VERSION ""

NS_ :

BS_:

BU_: BSM BSM2 CADM CVADAS ECM EPS ORC CANOE EVCU2

BO_ 2654556161 ME_SystemDebugData_1: 64 CVADAS
 SG_ FD14_1_Hook_PresentPtr_MCU1_0 : 0|32@1+ (1,0) [0|0] ""  CANOE
 SG_ FD14_1_ErrFaultInfo_MCU2_0 : 32|16@1+ (1,0) [0|0] ""  CANOE
 SG_ FD14_1_Err_FaultInfo_MCU2_1 : 48|16@1+ (1,0) [0|0] ""  CANOE
 SG_ FD14_1_Err_FaultInfo_MPU1_0 : 64|16@1+ (1,0) [0|0] ""  CANOE
 SG_ FD14_1_Err_FaultInfo_MCU1_0 : 80|16@1+ (1,0) [0|0] ""  CANOE
 SG_ FD14_1_WDG_Error_ID_MCU1_0 : 96|16@1+ (1,0) [0|0] ""  CANOE
 SG_ FD14_1_SDL_Fault_MCU1_0 : 112|16@1+ (1,0) [0|0] ""  CANOE
 SG_ FD14_1_Hook_Service_MCU1_0 : 128|16@1+ (1,0) [0|0] ""  CANOE
 SG_ FD14_1_Hook_DtErr_MCU1_0 : 144|16@1+ (1,0) [0|0] ""  CANOE
 SG_ FD14_1_Hook_Reserved_MCU1_0 : 160|16@1+ (1,0) [0|0] ""  CANOE
 SG_ FD14_1_Hook_fatalErr_MCU1_0 : 176|8@1+ (1,0) [0|0] ""  CANOE
 SG_ FD14_1_Hook_actTsk_MCU1_0 : 184|8@1+ (1,0) [0|0] ""  CANOE
 SG_ FD14_1_Hook_Error_MCU1_0 : 192|8@1+ (1,0) [0|0] ""  CANOE
 SG_ FD14_1_Hook_Type_MCU1_0 : 200|8@1+ (1,0) [0|0] ""  CANOE
 SG_ FD14_1_SSM_FltData1_MCU1_0 : 208|8@1+ (1,0) [0|0] ""  CANOE
 SG_ FD14_1_SSM_FltData2_MCU1_0 : 216|8@1+ (1,0) [0|0] ""  CANOE
 SG_ FD14_1_SSM_FltData3_MCU1_0 : 224|8@1+ (1,0) [0|0] ""  CANOE
 SG_ FD14_1_SSM_FltData4_MCU1_0 : 232|8@1+ (1,0) [0|0] ""  CANOE
 SG_ FD14_1_SSM_FltData5_MCU1_0 : 240|8@1+ (1,0) [0|0] ""  CANOE
 SG_ FD14_1_SSM_FltData6_MCU1_0 : 248|8@1+ (1,0) [0|0] ""  CANOE
 SG_ FD14_1_SSM_FltData7_MCU1_0 : 256|8@1+ (1,0) [0|0] ""  CANOE
 SG_ FD14_1_SSM_FltData8_MCU1_0 : 264|8@1+ (1,0) [0|0] ""  CANOE
 SG_ FD14_1_SSM_FltData9_MCU1_0 : 272|8@1+ (1,0) [0|0] ""  CANOE
 SG_ FD14_1_SSM_FltData10_MCU1_0 : 280|8@1+ (1,0) [0|0] ""  CANOE
 SG_ FD14_1_SSM_FltData11_MCU1_0 : 288|8@1+ (1,0) [0|0] ""  CANOE
 SG_ FD14_1_SSM_FltData12_MCU1_0 : 296|8@1+ (1,0) [0|0] ""  CANOE
 SG_ FD14_1_SSM_FltData13_MCU1_0 : 304|8@1+ (1,0) [0|0] ""  CANOE
 SG_ FD14_1_SSM_FltData14_MCU1_0 : 312|8@1+ (1,0) [0|0] ""  CANOE
 SG_ FD14_1_SSM_FltData15_MCU1_0 : 320|8@1+ (1,0) [0|0] ""  CANOE
 SG_ FD14_1_SSM_FltData16_MCU1_0 : 328|8@1+ (1,0) [0|0] ""  CANOE
 SG_ FD14_1_SSM_FltData17_MCU1_0 : 336|8@1+ (1,0) [0|0] ""  CANOE
 SG_ FD14_1_SSM_FltData18_MCU1_0 : 344|8@1+ (1,0) [0|0] ""  CANOE
 SG_ FD14_1_Err_FaultNum_MCU2_0 : 352|8@1+ (1,0) [0|0] ""  CANOE
 SG_ FD14_1_Err_FaultNum_MCU2_1 : 360|8@1+ (1,0) [0|0] ""  CANOE
 SG_ FD14_1_Err_FaultNum_MPU1_0 : 368|8@1+ (1,0) [0|0] ""  CANOE
 SG_ FD14_1_Err_FaultNum_MCU1_0 : 376|8@1+ (1,0) [0|0] ""  CANOE
 SG_ FD14_1_Reserved_MCU2_0 : 384|8@1+ (1,0) [0|0] ""  CANOE
 SG_ FD14_1_Reserved_MCU2_1 : 392|8@1+ (1,0) [0|0] ""  CANOE
 SG_ FD14_1_Reserved_MPU1_0 : 400|8@1+ (1,0) [0|0] ""  CANOE
 SG_ FD14_1_Reserved_MCU1_0 : 408|8@1+ (1,0) [0|0] ""  CANOE

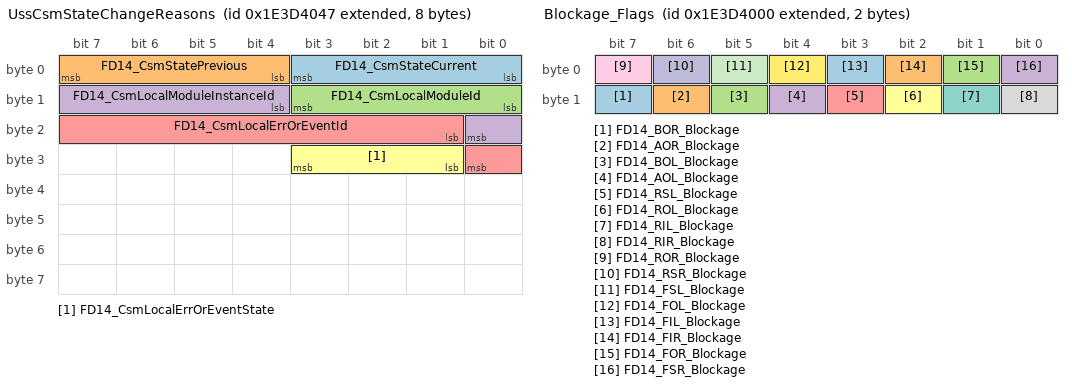
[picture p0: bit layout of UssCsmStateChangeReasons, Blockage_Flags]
BO_ 2654814279 UssCsmStateChangeReasons: 8 CVADAS
 SG_ FD14_CsmStateCurrent : 0|4@1+ (1,0) [0|15] ""  CANOE
 SG_ FD14_CsmStatePrevious : 4|4@1+ (1,0) [0|15] ""  CANOE
 SG_ FD14_CsmLocalModuleId : 8|4@1+ (1,0) [0|15] ""  CANOE
 SG_ FD14_CsmLocalModuleInstanceId : 12|5@1+ (1,0) [0|31] ""  CANOE
 SG_ FD14_CsmLocalErrOrEventId : 17|8@1+ (1,0) [0|255] ""  CANOE
 SG_ FD14_CsmLocalErrOrEventState : 25|3@1+ (1,0) [0|7] ""  CANOE

BO_ 2654552135 PntDebugData_Rx: 8 CANOE
 SG_ FD14_RawPntDebugSignal : 0|64@1+ (1,0) [0|0] ""  CVADAS

BO_ 2654552136 SetUSSParkingMode: 1 CANOE
 SG_ FD14_UssParkingModeSignal : 0|8@1+ (1,0) [0|0] ""  CVADAS

BO_ 2654814208 Blockage_Flags: 2 CVADAS
 SG_ FD14_BOR_Blockage : 15|1@1+ (1,0) [0|1] ""  CANOE
 SG_ FD14_AOR_Blockage : 14|1@1+ (1,0) [0|1] ""  CANOE
 SG_ FD14_BOL_Blockage : 13|1@1+ (1,0) [0|1] ""  CANOE
 SG_ FD14_AOL_Blockage : 12|1@1+ (1,0) [0|1] ""  CANOE
 SG_ FD14_RSL_Blockage : 11|1@1+ (1,0) [0|1] ""  CANOE
 SG_ FD14_ROL_Blockage : 10|1@1+ (1,0) [0|1] ""  CANOE
 SG_ FD14_RIL_Blockage : 9|1@1+ (1,0) [0|1] ""  CANOE
 SG_ FD14_RIR_Blockage : 8|1@1+ (1,0) [0|1] ""  CANOE
 SG_ FD14_ROR_Blockage : 7|1@1+ (1,0) [0|1] ""  CANOE
 SG_ FD14_RSR_Blockage : 6|1@1+ (1,0) [0|1] ""  CANOE
 SG_ FD14_FSL_Blockage : 5|1@1+ (1,0) [0|1] ""  CANOE
 SG_ FD14_FOL_Blockage : 4|1@1+ (1,0) [0|1] ""  CANOE
 SG_ FD14_FIL_Blockage : 3|1@1+ (1,0) [0|1] ""  CANOE
 SG_ FD14_FIR_Blockage : 2|1@1+ (1,0) [0|1] ""  CANOE
 SG_ FD14_FOR_Blockage : 1|1@1+ (1,0) [0|1] ""  CANOE
 SG_ FD14_FSR_Blockage : 0|1@1+ (1,0) [0|1] ""  CANOE

BO_ 2654552169 Debug_AP_Variables: 64 CVADAS
 SG_ FD14_IeAutoPark_e_AlgoState : 344|3@1+ (1,0) [0|4] ""  CANOE
 SG_ FD14_IeAP_e_AutoParkStatus : 331|3@1+ (1,0) [0|6] ""  CANOE
 SG_ FD14_MeAP_e_ParkAssistStatus : 336|3@1+ (1,0) [0|4] ""  CANOE
 SG_ FD14_MeAP_e_Park_state : 299|32@1- (1,0) [-32768|32768] ""  CANOE
 SG_ FD14_MeAP_a_ThrtlCmd : 267|32@1- (0.0001,0) [3.4E-038|3.4E+038] ""  CANOE
 SG_ FD14_MeAP_a_BrkCmd : 235|32@1- (0.0001,0) [3.4E-038|3.4E+038] ""  CANOE
 SG_ FD14_MeAP_deg_StrCmd : 203|32@1- (0.0001,0) [3.4E-038|3.4E+038] ""  CANOE
 SG_ FD14_MeAP_b_PPPADisable : 202|1@1+ (1,0) [0|1] ""  CANOE
 SG_ FD14_MeAP_b_PPPADefEng : 201|1@1+ (1,0) [0|1] ""  CANOE
 SG_ FD14_MeAP_b_PPPAActv4LOW : 200|1@1+ (1,0) [0|1] ""  CANOE
 SG_ FD14_MeAP_b_PPPAActvTrlr : 199|1@1+ (1,0) [0|1] ""  CANOE
 SG_ FD14_MeAP_b_PARBDisable : 198|1@1+ (1,0) [0|1] ""  CANOE
 SG_ FD14_MeAP_b_PARBActv4LOW : 197|1@1+ (1,0) [0|1] ""  CANOE
 SG_ FD14_MeAP_b_PARBActvTrlr : 196|1@1+ (1,0) [0|1] ""  CANOE
 SG_ FD14_MeAP_b_RPAVolDefMed : 195|1@1+ (1,0) [0|1] ""  CANOE
 SG_ FD14_MeAP_b_FPAVolDefMed : 194|1@1+ (1,0) [0|1] ""  CANOE
 SG_ FD14_MeAP_b_PAVolDefMed : 193|1@1+ (1,0) [0|1] ""  CANOE
 SG_ FD14_MeAP_b_RPAActvTrlr : 192|1@1+ (1,0) [0|1] ""  CANOE
 SG_ FD14_MeAP_b_RPADisable : 191|1@1+ (1,0) [0|1] ""  CANOE
 SG_ FD14_MeAP_b_FPADisable : 190|1@1+ (1,0) [0|1] ""  CANOE
 SG_ FD14_MeAP_b_FeatureEnbl : 189|1@1+ (1,0) [0|1] ""  CANOE
 SG_ FD14_MeAP_b_VehCndSts : 188|1@1+ (1,0) [0|1] ""  CANOE
 SG_ FD14_IeAP_b_MnvPosOk : 187|1@1+ (1,0) [0|1] ""  CANOE
 SG_ FD14_MeAP_b_SteerActionReq : 186|1@1+ (1,0) [0|1] ""  CANOE
 SG_ FD14_MeAP_b_PosMet : 185|1@1+ (1,0) [0|1] ""  CANOE
 SG_ FD14_MeAP_b_ManeuverSuccess : 184|1@1+ (1,0) [0|1] ""  CANOE
 SG_ FD14_MeAP_b_ManeuverAbort : 183|1@1+ (1,0) [0|1] ""  CANOE
 SG_ FD14_MeAP_b_BSMHandshakeActv : 182|1@1+ (1,0) [0|1] ""  CANOE
 SG_ FD14_MeAP_b_StandStill : 181|1@1+ (1,0) [0|1] ""  CANOE
 SG_ FD14_MeAP_b_DriverOverride : 180|1@1+ (1,0) [0|1] ""  CANOE
 SG_ FD14_MeAP_b_APInitSts : 179|1@1+ (1,0) [0|1] ""  CANOE
 SG_ FD14_MeAP_b_SeekSpdExceedTimeout : 178|1@1+ (1,0) [0|1] ""  CANOE
 SG_ FD14_MeAP_b_PausedPressBtnTimeou : 177|1@1+ (1,0) [0|1] ""  CANOE
 SG_ FD14_MeAP_b_ObjInPathTimeout : 176|1@1+ (1,0) [0|1] ""  CANOE
 SG_ FD14_MeAP_b_CamHandshakeTimeout : 175|1@1+ (1,0) [0|1] ""  CANOE
 SG_ FD14_MeAP_b_GearShiftWaitTimeout : 174|1@1+ (1,0) [0|1] ""  CANOE
 SG_ FD14_MeAP_b_EPSInterfaceTimeout : 173|1@1+ (1,0) [0|1] ""  CANOE
 SG_ FD14_MeAP_b_BSMInterfaceTimeout : 172|1@1+ (1,0) [0|1] ""  CANOE
 SG_ FD14_MeAP_b_VCOpPaused : 171|1@1+ (1,0) [0|1] ""  CANOE
 SG_ FD14_MeAP_b_RPAwithBrkStatus : 170|1@1+ (1,0) [0|1] ""  CANOE
 SG_ FD14_MeAP_b_RPAStatus : 169|1@1+ (1,0) [0|1] ""  CANOE
 SG_ FD14_MeAP_b_FPAStatus : 168|1@1+ (1,0) [0|1] ""  CANOE
 SG_ FD14_IeAP_e_AbortCon : 160|8@1+ (1,0) [0|255] ""  CANOE
 SG_ FD14_IeAP_cnt_CurrentVehSweep : 152|8@1+ (1,0) [0|255] ""  CANOE
 SG_ FD14_MeAP_e_PP_state : 144|8@1- (1,0) [-128|127] ""  CANOE
 SG_ FD14_MeAP_cm_RearRightMinXDist : 128|16@1- (1,0) [-32768|32768] ""  CANOE
 SG_ FD14_MeAP_cm_RearLeftMinXDist : 112|16@1- (1,0) [-32768|32768] ""  CANOE
 SG_ FD14_MeAP_cm_RearCenterMinXDist : 96|16@1- (1,0) [-32768|32768] ""  CANOE
 SG_ FD14_MeAP_cm_FrntRightMinXDist : 80|16@1- (1,0) [-32768|32768] ""  CANOE
 SG_ FD14_MeAP_cm_FrntLeftMinXDist : 64|16@1- (1,0) [-32768|32768] ""  CANOE
 SG_ FD14_MeAP_cm_FrntCenterMinXDist : 48|16@1- (1,0) [-32768|32768] ""  CANOE
 SG_ FD14_MeAP_cnt_TransDebugVar_Copy : 32|16@1- (1,0) [-32768|32768] ""  CANOE
 SG_ FD14_MeAP_cnt_TransDebugVar : 16|16@1+ (1,0) [0|512] ""  CANOE
 SG_ FD14_MeAP_cnt_StateDebugVar : 0|16@1+ (1,0) [0|512] ""  CANOE

BO_ 2654552217 Debug_CalibSts: 64 CVADAS
 SG_ FD14_CalibStatus_STM_Current_Rig : 120|8@1+ (1,0) [0|4] ""  CANOE
 SG_ FD14_CalibStatus_STM_Current_Rea : 112|8@1+ (1,0) [0|4] ""  CANOE
 SG_ FD14_CalibStatus_STM_Current_Lef : 104|8@1+ (1,0) [0|4] ""  CANOE
 SG_ FD14_CalibStatus_STM_Current_Fro : 96|8@1+ (1,0) [0|4] ""  CANOE
 SG_ FD14_CalibStatus_STM_OC_Right : 88|8@1+ (1,0) [0|4] ""  CANOE
 SG_ FD14_CalibStatus_STM_OC_Rear : 80|8@1+ (1,0) [0|4] ""  CANOE
 SG_ FD14_CalibStatus_STM_OC_Left : 72|8@1+ (1,0) [0|4] ""  CANOE
 SG_ FD14_CalibStatus_STM_OC_Front : 64|8@1+ (1,0) [0|4] ""  CANOE
 SG_ FD14_CalibStatus_STM_SC_Right : 56|8@1+ (1,0) [0|4] ""  CANOE
 SG_ FD14_CalibStatus_STM_SC_Rear : 48|8@1+ (1,0) [0|4] ""  CANOE
 SG_ FD14_CalibStatus_STM_SC_Left : 40|8@1+ (1,0) [0|4] ""  CANOE
 SG_ FD14_CalibStatus_STM_SC_Front : 32|8@1+ (1,0) [0|4] ""  CANOE
 SG_ FD14_CalibStatus_STM_EOL_Right : 24|8@1+ (1,0) [0|4] ""  CANOE
 SG_ FD14_CalibStatus_STM_EOL_Rear : 16|8@1+ (1,0) [0|4] ""  CANOE
 SG_ FD14_CalibStatus_STM_EOL_Left : 8|8@1+ (1,0) [0|4] ""  CANOE
 SG_ FD14_CalibStatus_STM_EOL_Front : 0|8@1+ (1,0) [0|4] ""  CANOE

BO_ 2654552163 Debug_CurrentCalib_Data_2: 64 CVADAS
 SG_ FD14_Z_f32_Current_Right : 352|32@1- (0.0001,0) [3.4E-038|3.4E+038] ""  CANOE
 SG_ FD14_Z_f32_Current_Rear : 320|32@1- (0.0001,0) [3.4E-038|3.4E+038] ""  CANOE
 SG_ FD14_Pitch_f32_Current_Right : 288|32@1- (0.0001,0) [3.4E-038|3.4E+038] ""  CANOE
 SG_ FD14_Pitch_f32_Current_Rear : 256|32@1- (0.0001,0) [3.4E-038|3.4E+038] ""  CANOE
 SG_ FD14_Roll_f32_Current_Right : 224|32@1- (0.0001,0) [3.4E-038|3.4E+038] ""  CANOE
 SG_ FD14_Roll_f32_Current_Rear : 192|32@1- (0.0001,0) [3.4E-038|3.4E+038] ""  CANOE
 SG_ FD14_Yaw_f32_Current_Right : 160|32@1- (0.0001,0) [3.4E-038|3.4E+038] ""  CANOE
 SG_ FD14_Yaw_f32_Current_Rear : 128|32@1- (0.0001,0) [3.4E-038|3.4E+038] ""  CANOE
 SG_ FD14_Y_f32_Current_Right : 96|32@1- (0.0001,0) [3.4E-038|3.4E+038] ""  CANOE
 SG_ FD14_Y_f32_Current_Rear : 64|32@1- (0.0001,0) [3.4E-038|3.4E+038] ""  CANOE
 SG_ FD14_X_f32_Current_Right : 32|32@1- (0.0001,0) [3.4E-038|3.4E+038] ""  CANOE
 SG_ FD14_X_f32_Current_Rear : 0|32@1- (0.0001,0) [3.4E-038|3.4E+038] ""  CANOE

BO_ 2654552152 Debug_EOLCalib_Data_1: 64 CVADAS
 SG_ FD14_Pitch_f32_EOL_Left : 352|32@1- (0.0001,0) [3.4E-038|3.4E+038] ""  CANOE
 SG_ FD14_Roll_f32_EOL_Left : 320|32@1- (0.0001,0) [3.4E-038|3.4E+038] ""  CANOE
 SG_ FD14_Yaw_f32_EOL_Left : 288|32@1- (0.0001,0) [3.4E-038|3.4E+038] ""  CANOE
 SG_ FD14_Z_f32_EOL_Left : 256|32@1- (0.0001,0) [3.4E-038|3.4E+038] ""  CANOE
 SG_ FD14_Y_f32_EOL_Left : 224|32@1- (0.0001,0) [3.4E-038|3.4E+038] ""  CANOE
 SG_ FD14_X_f32_EOL_Left : 192|32@1- (0.0001,0) [3.4E-038|3.4E+038] ""  CANOE
 SG_ FD14_Pitch_f32_EOL_Front : 160|32@1- (0.0001,0) [3.4E-038|3.4E+038] ""  CANOE
 SG_ FD14_Roll_f32_EOL_Front : 128|32@1- (0.0001,0) [3.4E-038|3.4E+038] ""  CANOE
 SG_ FD14_Yaw_f32_EOL_Front : 96|32@1- (0.0001,0) [3.4E-038|3.4E+038] ""  CANOE
 SG_ FD14_Z_f32_EOL_Front : 64|32@1- (0.0001,0) [3.4E-038|3.4E+038] ""  CANOE
 SG_ FD14_Y_f32_EOL_Front : 32|32@1- (0.0001,0) [3.4E-038|3.4E+038] ""  CANOE
 SG_ FD14_X_f32_EOL_Front : 0|32@1- (0.0001,0) [3.4E-038|3.4E+038] ""  CANOE

BO_ 2654552164 Debug_EOLCalib_Data_2: 64 CVADAS
 SG_ FD14_Roll_f32_EOL_Right : 352|32@1- (0.0001,0) [3.4E-038|3.4E+038] ""  CANOE
 SG_ FD14_Pitch_f32_EOL_Right : 320|32@1- (0.0001,0) [3.4E-038|3.4E+038] ""  CANOE
 SG_ FD14_Yaw_f32_EOL_Right : 288|32@1- (0.0001,0) [3.4E-038|3.4E+038] ""  CANOE
 SG_ FD14_Z_f32_EOL_Right : 256|32@1- (0.0001,0) [3.4E-038|3.4E+038] ""  CANOE
 SG_ FD14_Y_f32_EOL_Right : 224|32@1- (0.0001,0) [3.4E-038|3.4E+038] ""  CANOE
 SG_ FD14_X_f32_EOL_Right : 192|32@1- (0.0001,0) [3.4E-038|3.4E+038] ""  CANOE
 SG_ FD14_Pitch_f32_EOL_Rear : 160|32@1- (0.0001,0) [3.4E-038|3.4E+038] ""  CANOE
 SG_ FD14_Roll_f32_EOL_Rear : 128|32@1- (0.0001,0) [3.4E-038|3.4E+038] ""  CANOE
 SG_ FD14_Yaw_f32_EOL_Rear : 96|32@1- (0.0001,0) [3.4E-038|3.4E+038] ""  CANOE
 SG_ FD14_Z_f32_EOL_Rear : 64|32@1- (0.0001,0) [3.4E-038|3.4E+038] ""  CANOE
 SG_ FD14_Y_f32_EOL_Rear : 32|32@1- (0.0001,0) [3.4E-038|3.4E+038] ""  CANOE
 SG_ FD14_X_f32_EOL_Rear : 0|32@1- (0.0001,0) [3.4E-038|3.4E+038] ""  CANOE

BO_ 2654552216 Debug_ErrCodeAlgo: 64 CVADAS
 SG_ FD14_Err_Code_OC_Right : 88|8@1+ (1,0) [0|7] ""  CANOE
 SG_ FD14_Err_Code_OC_Rear : 80|8@1+ (1,0) [0|7] ""  CANOE
 SG_ FD14_Err_Code_OC_Left : 72|8@1+ (1,0) [0|7] ""  CANOE
 SG_ FD14_Err_Code_OC_Front : 64|8@1+ (1,0) [0|7] ""  CANOE
 SG_ FD14_Err_Code_SC_Right : 56|8@1+ (1,0) [0|7] ""  CANOE
 SG_ FD14_Err_Code_SC_Rear : 48|8@1+ (1,0) [0|7] ""  CANOE
 SG_ FD14_Err_Code_SC_Left : 40|8@1+ (1,0) [0|7] ""  CANOE
 SG_ FD14_Err_Code_SC_Front : 32|8@1+ (1,0) [0|7] ""  CANOE
 SG_ FD14_Err_Code_EOL_Rear_Copy_1 : 24|8@1+ (1,0) [0|19] ""  CANOE
 SG_ FD14_Err_Code_EOL_Rear : 16|8@1+ (1,0) [0|19] ""  CANOE
 SG_ FD14_Err_Code_EOL_Left : 8|8@1+ (1,0) [0|19] ""  CANOE
 SG_ FD14_Err_Code_EOL_Front : 0|8@1+ (1,0) [0|19] ""  CANOE

BO_ 2654552162 Debug_FeatureCollection: 64 CVADAS
 SG_ FD14_InvalidFeatures_Right_u32 : 352|32@1+ (1,0) [0|4294967295] ""  CANOE
 SG_ FD14_IgnoredFeatures_Right_u32 : 320|32@1+ (1,0) [0|4294967295] ""  CANOE
 SG_ FD14_ValidFeatures_Right_u32 : 288|32@1+ (1,0) [0|4294967295] ""  CANOE
 SG_ FD14_InvalidFeatures_Rear_u32 : 256|32@1+ (1,0) [0|4294967295] ""  CANOE
 SG_ FD14_IgnoredFeatures_Rear_u32 : 224|32@1+ (1,0) [0|4294967295] ""  CANOE
 SG_ FD14_ValidFeatures_Rear_u32 : 192|32@1+ (1,0) [0|4294967295] ""  CANOE
 SG_ FD14_InvalidFeatures_Left_u32 : 160|32@1+ (1,0) [0|4294967295] ""  CANOE
 SG_ FD14_IgnoredFeatures_Left_u32 : 128|32@1+ (1,0) [0|4294967295] ""  CANOE
 SG_ FD14_ValidFeatures_Left_u32 : 96|32@1+ (1,0) [0|4294967295] ""  CANOE
 SG_ FD14_InvalidFeatures_Front_u32 : 64|32@1+ (1,0) [0|4294967295] ""  CANOE
 SG_ FD14_IgnoredFeatures_Front_u32 : 32|32@1+ (1,0) [0|4294967295] ""  CANOE
 SG_ FD14_ValidFeatures_Front_u32 : 0|32@1+ (1,0) [0|4294967295] ""  CANOE

BO_ 2654552178 Debug_FPA_HMI_InfoToVC: 64 CVADAS
 SG_ FD14_perpParkDirectionSel : 296|2@1+ (1,0) [0|2] ""  CANOE
 SG_ FD14_parkExtSideSel : 288|2@1+ (1,0) [0|2] ""  CANOE
 SG_ FD14_slotSide : 280|2@1+ (1,0) [0|2] ""  CANOE
 SG_ FD14_parkingDirection : 272|2@1+ (1,0) [0|2] ""  CANOE
 SG_ FD14_parkingSlotType : 264|3@1+ (1,0) [0|7] ""  CANOE
 SG_ FD14_IsBackSftbtnSel : 259|1@1+ (1,0) [0|1] ""  CANOE
 SG_ FD14_IsSlotSel : 258|1@1+ (1,0) [0|1] ""  CANOE
 SG_ FD14_IsExitSftBtnSel : 257|1@1+ (1,0) [0|1] ""  CANOE
 SG_ FD14_IsParkSftBtnSel : 256|1@1+ (1,0) [0|1] ""  CANOE
 SG_ FD14_MaAP_m_ParkSpot4RearStreetY : 224|32@1- (0.0001,0) [-15|15] ""  CANOE
 SG_ FD14_MaAP_m_ParkSpot4RearStreetX : 192|32@1- (0.0001,0) [-15|15] ""  CANOE
 SG_ FD14_MaAP_m_ParkSpot3RearBorderY : 160|32@1- (0.0001,0) [-15|15] ""  CANOE
 SG_ FD14_MaAP_m_ParkSpot3RearBorderX : 128|32@1- (0.0001,0) [-15|15] ""  CANOE
 SG_ FD14_MaAP_m_ParkSpot2FrntBorderY : 96|32@1- (0.0001,0) [-15|15] ""  CANOE
 SG_ FD14_MaAP_m_ParkSpot2FrntBorderX : 64|32@1- (0.0001,0) [-15|15] ""  CANOE
 SG_ FD14_MaAP_m_ParkSpot1FrntStreetY : 32|32@1- (0.0001,0) [-15|15] ""  CANOE
 SG_ FD14_MaAP_m_ParkSpot1FrntStreetX : 0|32@1- (0.0001,0) [-15|15] ""  CANOE

BO_ 2654552149 Debug_HMI_Input_Data: 64 CVADAS
 SG_ FD14_tchScrnStatus_e : 216|8@1+ (1,0) [0|7] ""  CANOE
 SG_ FD14_View_Error_e : 208|8@1+ (1,0) [0|0] ""  CANOE
 SG_ FD14_DynOvl_Error_e : 200|8@1+ (1,0) [0|0] ""  CANOE
 SG_ FD14_SoftBtn_Error_e : 192|8@1+ (1,0) [0|0] ""  CANOE
 SG_ FD14_ImageDefeat_Error_e : 184|8@1+ (1,0) [0|0] ""  CANOE
 SG_ FD14_tgwDispStatus_e : 176|8@1+ (1,0) [0|0] ""  CANOE
 SG_ FD14_CameraDisplaySts2_e : 168|8@1+ (1,0) [0|0] ""  CANOE
 SG_ FD14_prndStatus_e : 160|8@1+ (1,0) [0|0] ""  CANOE
 SG_ FD14_transEquipped_e : 152|8@1+ (1,0) [0|0] ""  CANOE
 SG_ FD14_ignitionStatus_e : 144|8@1+ (1,0) [0|0] ""  CANOE
 SG_ FD14_trscStat_e : 136|8@1+ (1,0) [0|0] ""  CANOE
 SG_ FD14_NetCfg_TRSCM_e : 128|8@1+ (1,0) [0|0] ""  CANOE
 SG_ FD14_revGear_e : 120|8@1+ (1,0) [0|0] ""  CANOE
 SG_ FD14_lrwsST_e : 112|8@1+ (1,0) [0|0] ""  CANOE
 SG_ FD14_GW_C_I6_timeout_b : 109|1@1+ (1,0) [0|1] ""  CANOE
 SG_ FD14_SVC_Delay_Feature_b : 108|1@1+ (1,0) [0|1] ""  CANOE
 SG_ FD14_SVC_FFCV_Gridlines_Feature_ : 107|1@1+ (1,0) [0|1] ""  CANOE
 SG_ FD14_SVC_Static_Gridlines_Featur : 106|1@1+ (1,0) [0|1] ""  CANOE
 SG_ FD14_SVC_Dynamic_Gridlines_Featu : 105|1@1+ (1,0) [0|1] ""  CANOE
 SG_ FD14_TopVideoBlanked_b : 104|1@1+ (1,0) [0|1] ""  CANOE
 SG_ FD14_LanguageSelection_u8 : 96|8@1+ (1,0) [0|255] ""  CANOE
 SG_ FD14_vehicleLine_e : 88|8@1+ (1,0) [0|255] ""  CANOE
 SG_ FD14_tchScrnCoord_s_Y_u16 : 80|8@1+ (1,0) [0|255] ""  CANOE
 SG_ FD14_tchScrnCoord_s_X_u16 : 72|8@1+ (1,0) [0|255] ""  CANOE
 SG_ FD14_CAM_NA_Bitfield_u8 : 64|8@1+ (1,0) [0|255] ""  CANOE
 SG_ FD14_vehicleSpeed_f32 : 32|32@1- (1,0) [3.4E-038|3.4E+038] ""  CANOE
 SG_ FD14_steeringWheelAngle_f32 : 0|32@1- (1,0) [3.4E-038|3.4E+038] ""  CANOE

BO_ 2654552150 Debug_HMI_Internal_Data: 16 CVADAS
 SG_ FD14_LastViewBeforeTestPattern_e : 88|8@1+ (1,0) [0|25] ""  CANOE
 SG_ FD14_Prev_DisplayedViewByAcore_e : 80|8@1+ (1,0) [0|25] ""  CANOE
 SG_ FD14_Curr_DisplayedViewByAcore_e : 72|8@1+ (1,0) [0|25] ""  CANOE
 SG_ FD14_Prev_RequestedViewByHmiM_e : 64|8@1+ (1,0) [0|25] ""  CANOE
 SG_ FD14_Curr_RequestedViewByHmiM_e : 56|8@1+ (1,0) [0|25] ""  CANOE
 SG_ FD14_Prev_SystemState_e : 48|8@1+ (1,0) [0|2] ""  CANOE
 SG_ FD14_Curr_SystemState_e : 40|8@1+ (1,0) [0|2] ""  CANOE
 SG_ FD14_M_FFClatch_e : 32|8@1+ (1,0) [0|1] ""  CANOE
 SG_ FD14_M_BURV_Memory_e : 24|8@1+ (1,0) [0|1] ""  CANOE
 SG_ FD14_FRONT_TOP_BTN_PRESSED_b : 20|1@1+ (1,0) [0|1] ""  CANOE
 SG_ FD14_REAR_TOP_BTN_PRESSED_b : 19|1@1+ (1,0) [0|1] ""  CANOE
 SG_ FD14_MAGNIFIER_BTN_PRESSED_b : 18|1@1+ (1,0) [0|1] ""  CANOE
 SG_ FD14_X_BTN_PRESSED_b : 17|1@1+ (1,0) [0|1] ""  CANOE
 SG_ FD14_OFFROAD_ABSNT_MC_BTN_PRESSE : 16|1@1+ (1,0) [0|1] ""  CANOE
 SG_ FD14_OFFROAD_PRSNT_MC_BTN_PRESSE : 15|1@1+ (1,0) [0|1] ""  CANOE
 SG_ FD14_OFFRD_ABSNT_AUXCAM_BTN_PRES : 14|1@1+ (1,0) [0|1] ""  CANOE
 SG_ FD14_OFFRD_PRSNT_AUXCAM_BTN_PRES : 13|1@1+ (1,0) [0|1] ""  CANOE
 SG_ FD14_RVCONLY_BTN_PRESSED_b : 12|1@1+ (1,0) [0|1] ""  CANOE
 SG_ FD14_FFCV_BTN_PRESSED_b : 11|1@1+ (1,0) [0|1] ""  CANOE
 SG_ FD14_FRONT_CROSS_BTN_PRESSED_b : 10|1@1+ (1,0) [0|1] ""  CANOE
 SG_ FD14_REAR_CROSS_BTN_PRESSED_b : 9|1@1+ (1,0) [0|1] ""  CANOE
 SG_ FD14_IgnoreVehicleOffSpeed : 8|1@1+ (1,0) [0|1] ""  CANOE
 SG_ FD14_ZoomFactor_u8 : 0|8@1+ (1,0) [0|255] ""  CANOE

BO_ 2654552148 Debug_HMI_Trailer_Views_Data: 64 CVADAS
 SG_ FD14_TrailerCalibrationStatus : 264|8@1+ (1,0) [0|2] ""  CANOE
 SG_ FD14_TrscStatus : 256|8@1+ (1,0) [0|7] ""  CANOE
 SG_ FD14__JackKnifeAngle : 224|32@1- (1,0) [3.4E-038|3.4E+038] ""  CANOE
 SG_ FD14_TrailerAngleSign : 136|8@1+ (1,0) [0|1] ""  CANOE
 SG_ FD14_Prev_TRG_Stat : 128|8@1+ (1,0) [0|3] ""  CANOE
 SG_ FD14_Curr_TRG_Stat : 120|8@1+ (1,0) [0|3] ""  CANOE
 SG_ FD14_ItbmTrailerStatus : 216|8@1+ (1,0) [0|255] ""  CANOE
 SG_ FD14_TrailerConnectionStatus : 80|8@1+ (1,0) [0|255] ""  CANOE
 SG_ FD14_TrailerWheelBase : 208|8@1+ (1,0) [0|255] ""  CANOE
 SG_ FD14_KnobAngle : 176|32@1- (1,0) [3.4E-038|3.4E+038] ""  CANOE
 SG_ FD14_MaxTadAngle : 144|32@1- (1,0) [3.4E-038|3.4E+038] ""  CANOE
 SG_ FD14_TadAngle : 88|32@1- (1,0) [3.4E-038|3.4E+038] ""  CANOE
 SG_ FD14_STM_v_TRGAUTO_BTN_PRESSED_b : 31|1@1+ (1,0) [0|1] ""  CANOE
 SG_ FD14_STM_v_TRGRIGHT_BTN_PRESSED_ : 30|1@1+ (1,0) [0|1] ""  CANOE
 SG_ FD14_STM_v_TRGLEFT_BTN_PRESSED_b : 29|1@1+ (1,0) [0|1] ""  CANOE
 SG_ FD14_M_Progress_Bar_Percentage : 72|8@1+ (1,0) [0|255] ""  CANOE
 SG_ FD14_M_Maneuver_Initial_Run : 64|8@1+ (1,0) [0|255] ""  CANOE
 SG_ FD14_M_Progress_Bar_Distance : 56|8@1+ (1,0) [0|255] ""  CANOE
 SG_ FD14_M_Cplr_Htch_Distance : 48|8@1+ (1,0) [0|255] ""  CANOE
 SG_ FD14_M_CPLR_POS_Y_u : 40|8@1+ (1,0) [0|255] ""  CANOE
 SG_ FD14_M_CPLR_POS_X_u : 32|8@1+ (1,0) [0|255] ""  CANOE
 SG_ FD14_M_THA_SFT_BTN_PRESSED_b : 28|1@1+ (1,0) [0|1] ""  CANOE
 SG_ FD14_M_START_BTN_PRESSED_b : 24|1@1+ (1,0) [0|1] ""  CANOE
 SG_ FD14_M_CONFIRM_BTN_PRESSED_b : 25|1@1+ (1,0) [0|1] ""  CANOE
 SG_ FD14_M_VIEW_SCRN_TCH_STS_b : 26|1@1+ (1,0) [0|1] ""  CANOE
 SG_ FD14_M_VIEW_ZOOM_STS_b : 27|1@1+ (1,0) [0|1] ""  CANOE
 SG_ FD14_M_Current_THA_State_On_Scre : 16|8@1+ (1,0) [0|255] ""  CANOE
 SG_ FD14_M_Current_THA_State_On_Zync : 8|8@1+ (1,0) [0|255] ""  CANOE
 SG_ FD14_M_Requested_THA_State : 0|8@1+ (1,0) [0|255] ""  CANOE

BO_ 2654552320 Debug_ModuleState: 64 CVADAS
 SG_ FD14_OC_ModuleState_STM_Right : 88|8@1+ (1,0) [0|11] ""  CANOE
 SG_ FD14_OC_ModuleState_STM_Rear : 80|8@1+ (1,0) [0|11] ""  CANOE
 SG_ FD14_OC_ModuleState_STM_Left : 72|8@1+ (1,0) [0|11] ""  CANOE
 SG_ FD14_OC_ModuleState_STM_Front : 64|8@1+ (1,0) [0|11] ""  CANOE
 SG_ FD14_SC_ModuleState_STM_Right : 56|8@1+ (1,0) [0|12] ""  CANOE
 SG_ FD14_SC_ModuleState_STM_Rear : 48|8@1+ (1,0) [0|12] ""  CANOE
 SG_ FD14_SC_ModuleState_STM_Left : 40|8@1+ (1,0) [0|12] ""  CANOE
 SG_ FD14_SC_ModuleState_STM_Front : 32|8@1+ (1,0) [0|12] ""  CANOE
 SG_ FD14_EOL_ModuleState_STM_Right : 24|8@1+ (1,0) [0|8] ""  CANOE
 SG_ FD14_EOL_ModuleState_STM_Rear : 16|8@1+ (1,0) [0|8] ""  CANOE
 SG_ FD14_EOL_ModuleState_STM_Left : 8|8@1+ (1,0) [0|8] ""  CANOE
 SG_ FD14_EOL_ModuleState_STM_Front : 0|8@1+ (1,0) [0|8] ""  CANOE

BO_ 2654552176 Debug_NFCD_Obj_0_4: 64 CVADAS
 SG_ FD14_NFCD_DistanceToClosestPoint : 296|32@1- (0.0001,0) [-15|15] ""  CANOE
 SG_ FD14_NFCD_DistanceToClosest_0000 : 264|32@1- (0.0001,0) [-15|15] ""  CANOE
 SG_ FD14_NFCD_ObjValid_4 : 68|1@1+ (1,0) [0|1] ""  CANOE
 SG_ FD14_NFCD_ObjValid_3 : 67|1@1+ (1,0) [0|1] ""  CANOE
 SG_ FD14_NFCD_DistanceToClosest_0001 : 232|32@1- (0.0001,0) [-15|15] ""  CANOE
 SG_ FD14_NFCD_DistanceToClosest_0002 : 200|32@1- (0.0001,0) [-15|15] ""  CANOE
 SG_ FD14_NFCD_ObjValid_2 : 66|1@1+ (1,0) [0|1] ""  CANOE
 SG_ FD14_NFCD_DistanceToClosest_0003 : 168|32@1- (0.0001,0) [-15|15] ""  CANOE
 SG_ FD14_NFCD_DistanceToClosest_0004 : 136|32@1- (0.0001,0) [-15|15] ""  CANOE
 SG_ FD14_NFCD_ObjValid_1 : 65|1@1+ (1,0) [0|1] ""  CANOE
 SG_ FD14_NFCD_DistanceToClosest_0005 : 104|32@1- (0.0001,0) [-15|15] ""  CANOE
 SG_ FD14_NFCD_DistanceToClosest_0006 : 72|32@1- (0.0001,0) [-15|15] ""  CANOE
 SG_ FD14_NFCD_ObjValid_0 : 64|1@1+ (1,0) [0|1] ""  CANOE
 SG_ FD14_NFCD_DistanceToClosest_0007 : 32|32@1- (0.0001,0) [-15|15] ""  CANOE
 SG_ FD14_NFCD_DistanceToClosest_0008 : 0|32@1- (0.0001,0) [-15|15] ""  CANOE

BO_ 2654552177 Debug_NFCD_Obj_5_9: 64 CVADAS
 SG_ FD14_IeVBII_nfcd_MinDisToCollisi : 336|32@1- (0.0001,0) [-15|15] ""  CANOE
 SG_ FD14_NFCD_ObjValid_9 : 68|1@1+ (1,0) [0|1] ""  CANOE
 SG_ FD14_NFCD_DistanceToClosest_0009 : 304|32@1- (0.0001,0) [-15|15] ""  CANOE
 SG_ FD14_NFCD_DistanceToClosest_0010 : 272|32@1- (0.0001,0) [-15|15] ""  CANOE
 SG_ FD14_NFCD_ObjValid_8 : 67|1@1+ (1,0) [0|1] ""  CANOE
 SG_ FD14_NFCD_DistanceToClosest_0011 : 240|32@1- (0.0001,0) [-15|15] ""  CANOE
 SG_ FD14_NFCD_DistanceToClosest_0012 : 208|32@1- (0.0001,0) [-15|15] ""  CANOE
 SG_ FD14_NFCD_ObjValid_7 : 66|1@1+ (1,0) [0|1] ""  CANOE
 SG_ FD14_NFCD_DistanceToClosest_0013 : 176|32@1- (0.0001,0) [-15|15] ""  CANOE
 SG_ FD14_NFCD_DistanceToClosest_0014 : 144|32@1- (0.0001,0) [-15|15] ""  CANOE
 SG_ FD14_NFCD_ObjValid_6 : 65|1@1+ (1,0) [0|1] ""  CANOE
 SG_ FD14_NFCD_DistanceToClosest_0015 : 112|32@1- (0.0001,0) [-15|15] ""  CANOE
 SG_ FD14_NFCD_DistanceToClosest_0016 : 80|32@1- (0.0001,0) [-15|15] ""  CANOE
 SG_ FD14_NFCD_ObjValid_5 : 64|1@1+ (1,0) [0|1] ""  CANOE
 SG_ FD14_NFCD_DistanceToClosest_0017 : 32|32@1- (0.0001,0) [-15|15] ""  CANOE
 SG_ FD14_NFCD_DistanceToClosest_0018 : 0|32@1- (0.0001,0) [-15|15] ""  CANOE

BO_ 2654552160 Debug_OCCalib_Data: 64 CVADAS
 SG_ FD14_Z_f32_Current_Rear : 448|32@1- (0.0001,0) [3.4E-038|3.4E+038] ""  CANOE
 SG_ FD14_Y_f32_Current_Rear : 416|32@1- (0.0001,0) [3.4E-038|3.4E+038] ""  CANOE
 SG_ FD14_X_f32_Current_Rear : 384|32@1- (0.0001,0) [3.4E-038|3.4E+038] ""  CANOE
 SG_ FD14_Pitch_f32_OC_Right : 352|32@1- (0.0001,0) [3.4E-038|3.4E+038] ""  CANOE
 SG_ FD14_Roll_f32_OC_Right : 320|32@1- (0.0001,0) [3.4E-038|3.4E+038] ""  CANOE
 SG_ FD14_Yaw_f32_OC_Right : 288|32@1- (0.0001,0) [3.4E-038|3.4E+038] ""  CANOE
 SG_ FD14_Pitch_f32_OC_Rear : 256|32@1- (0.0001,0) [3.4E-038|3.4E+038] ""  CANOE
 SG_ FD14_Roll_f32_OC_Rear : 224|32@1- (0.0001,0) [3.4E-038|3.4E+038] ""  CANOE
 SG_ FD14_Yaw_f32_OC_Rear : 192|32@1- (0.0001,0) [3.4E-038|3.4E+038] ""  CANOE
 SG_ FD14_Pitch_f32_OC_Left : 160|32@1- (0.0001,0) [3.4E-038|3.4E+038] ""  CANOE
 SG_ FD14_Roll_f32_OC_Left : 128|32@1- (0.0001,0) [3.4E-038|3.4E+038] ""  CANOE
 SG_ FD14_Yaw_f32_OC_Left : 96|32@1- (0.0001,0) [3.4E-038|3.4E+038] ""  CANOE
 SG_ FD14_Pitch_f32_OC_Front : 64|32@1- (0.0001,0) [3.4E-038|3.4E+038] ""  CANOE
 SG_ FD14_Roll_f32_OC_Front : 32|32@1- (0.0001,0) [3.4E-038|3.4E+038] ""  CANOE
 SG_ FD14_Yaw_f32_OC_Front : 0|32@1- (0.0001,0) [3.4E-038|3.4E+038] ""  CANOE

BO_ 2654552153 Debug_SCCalib_Data: 64 CVADAS
 SG_ FD14_Pitch_f32_SC_Right : 352|32@1- (0.0001,0) [3.4E-038|3.4E+038] ""  CANOE
 SG_ FD14_Roll_f32_SC_Right : 320|32@1- (0.0001,0) [3.4E-038|3.4E+038] ""  CANOE
 SG_ FD14_Yaw_f32_SC_Right : 288|32@1- (0.0001,0) [3.4E-038|3.4E+038] ""  CANOE
 SG_ FD14_Pitch_f32_SC_Rear : 256|32@1- (0.0001,0) [3.4E-038|3.4E+038] ""  CANOE
 SG_ FD14_Roll_f32_SC_Rear : 224|32@1- (0.0001,0) [3.4E-038|3.4E+038] ""  CANOE
 SG_ FD14_Yaw_f32_SC_Rear : 192|32@1- (0.0001,0) [3.4E-038|3.4E+038] ""  CANOE
 SG_ FD14_Pitch_f32_SC_Left : 160|32@1- (0.0001,0) [3.4E-038|3.4E+038] ""  CANOE
 SG_ FD14_Roll_f32_SC_Left : 128|32@1- (0.0001,0) [3.4E-038|3.4E+038] ""  CANOE
 SG_ FD14_Yaw_f32_SC_Left : 96|32@1- (0.0001,0) [3.4E-038|3.4E+038] ""  CANOE
 SG_ FD14_Pitch_f32_SC_Front : 64|32@1- (0.0001,0) [3.4E-038|3.4E+038] ""  CANOE
 SG_ FD14_Roll_f32_SC_Front : 32|32@1- (0.0001,0) [3.4E-038|3.4E+038] ""  CANOE
 SG_ FD14_Yaw_f32_SC_Front : 0|32@1- (0.0001,0) [3.4E-038|3.4E+038] ""  CANOE

BO_ 2654552161 Debug_TargetData: 64 CVADAS
 SG_ FD14_TargetDetectRightRear_Right : 208|8@1- (1,0) [-128|127] ""  CANOE
 SG_ FD14_TargetDetectRightFront_Righ : 200|8@1- (1,0) [-128|127] ""  CANOE
 SG_ FD14_TargetDetectLeftRear_Right_ : 192|8@1- (1,0) [-128|127] ""  CANOE
 SG_ FD14_TargetDetectLeftFront_Right : 184|8@1- (1,0) [-128|127] ""  CANOE
 SG_ FD14_TargetLimitRear_Right_s8 : 176|8@1- (1,0) [-128|127] ""  CANOE
 SG_ FD14_TargetLimitFront_Right_s8 : 168|8@1- (1,0) [-128|127] ""  CANOE
 SG_ FD14_TargetInit_Right_s8 : 160|8@1- (1,0) [-128|127] ""  CANOE
 SG_ FD14_TargetDetectRightRear_Rear_ : 152|8@1- (1,0) [-128|127] ""  CANOE
 SG_ FD14_TargetDetectRightFront_Rear : 144|8@1- (1,0) [-128|127] ""  CANOE
 SG_ FD14_TargetDetectLeftRear_Rear_s : 136|8@1- (1,0) [-128|127] ""  CANOE
 SG_ FD14_TargetDetectLeftFront_Rear_ : 128|8@1- (1,0) [-128|127] ""  CANOE
 SG_ FD14_TargetLimitRear_Rear_s8 : 120|8@1- (1,0) [-128|127] ""  CANOE
 SG_ FD14_TargetLimitFront_Rear_s8 : 112|8@1- (1,0) [-128|127] ""  CANOE
 SG_ FD14_TargetInit_Rear_s8 : 104|8@1- (1,0) [-128|127] ""  CANOE
 SG_ FD14_TargetDetectRightRear_Left_ : 96|8@1- (1,0) [-128|127] ""  CANOE
 SG_ FD14_TargetDetectRightFront_Left : 88|8@1- (1,0) [-128|127] ""  CANOE
 SG_ FD14_TargetDetectLeftFront_Left_ : 80|8@1- (1,0) [-128|127] ""  CANOE
 SG_ FD14_TargetLimitRear_Left_s8 : 72|8@1- (1,0) [-128|127] ""  CANOE
 SG_ FD14_TargetLimitFront_Left_s8 : 64|8@1- (1,0) [-128|127] ""  CANOE
 SG_ FD14_TargetInit_Left_s8 : 56|8@1- (1,0) [-128|127] ""  CANOE
 SG_ FD14_TargetDetectRightRear_Front : 48|8@1- (1,0) [-128|127] ""  CANOE
 SG_ FD14_TargetDetectRightFront_Fron : 40|8@1- (1,0) [-128|127] ""  CANOE
 SG_ FD14_TargetDetectLeftRear_Front_ : 32|8@1- (1,0) [-128|127] ""  CANOE
 SG_ FD14_TargetDetectLeftFront_Front : 24|8@1- (1,0) [-128|127] ""  CANOE
 SG_ FD14_TargetLimitRear_Front_s8 : 16|8@1- (1,0) [-128|127] ""  CANOE
 SG_ FD14_TargetLimitFront_Front_s8 : 8|8@1- (1,0) [-128|127] ""  CANOE
 SG_ FD14_TargetInit_Front_s8 : 0|8@1- (1,0) [-128|127] ""  CANOE

BO_ 2654552194 DebugModelOutput: 64 CVADAS
 SG_ FD14_IeAP_cm_RearRightMinXDist_K : 176|12@1+ (1,0) [0|2000] "cm"  CANOE
 SG_ FD14_IeAP_cm_RearRightMinXDist : 160|12@1+ (1,0) [0|2000] "cm"  CANOE
 SG_ FD14_IeAP_cm_RearLeftMinXDist_KP : 144|12@1+ (1,0) [0|2000] "cm"  CANOE
 SG_ FD14_IeAP_cm_RearLeftMinXDist : 128|12@1+ (1,0) [0|2000] "cm"  CANOE
 SG_ FD14_IeAP_cm_RearCenterMinXDist_ : 112|12@1+ (1,0) [0|2000] "cm"  CANOE
 SG_ FD14_IeAP_cm_RearCenterMinXDist : 96|12@1+ (1,0) [0|2000] "cm"  CANOE
 SG_ FD14_IeAP_cm_FrntRightMinXDist_K : 80|12@1+ (1,0) [0|2000] "cm"  CANOE
 SG_ FD14_IeAP_cm_FrntRightMinXDist : 64|12@1+ (1,0) [0|2000] "cm"  CANOE
 SG_ FD14_IeAP_cm_FrntLeftMinXDist_KP : 48|12@1+ (1,0) [0|2000] "cm"  CANOE
 SG_ FD14_IeAP_cm_FrntLeftMinXDist : 32|12@1+ (1,0) [0|2000] "cm"  CANOE
 SG_ FD14_IeAP_cm_FrntCenterMinXDist_ : 16|12@1+ (1,0) [0|2000] "cm"  CANOE
 SG_ FD14_IeAP_cm_FrntCenterMinXDist : 0|12@1+ (1,0) [0|2000] "cm"  CANOE

BO_ 2654814232 DebugModelOutput_Feature_KPI_Tx: 64 CVADAS
 SG_ FD14_IeAP_cm_RearRightMinXD_0000 : 60|12@1+ (1,0) [0|2000] "cm"  CANOE
 SG_ FD14_IeAP_cm_RearLeftMinXDi_0000 : 48|12@1+ (1,0) [0|2000] "cm"  CANOE
 SG_ FD14_IeAP_cm_RearCenterMinX_0000 : 36|12@1+ (1,0) [0|2000] "cm"  CANOE
 SG_ FD14_IeAP_cm_FrntRightMinXD_0000 : 24|12@1+ (1,0) [0|2000] "cm"  CANOE
 SG_ FD14_IeAP_cm_FrntLeftMinXDi_0000 : 12|12@1+ (1,0) [0|2000] "cm"  CANOE
 SG_ FD14_IeAP_cm_FrntCenterMinX_0000 : 0|12@1+ (1,0) [0|2000] "cm"  CANOE

BO_ 2654814209 Diagnostics_Flags: 8 CVADAS
 SG_ FD14_BOR_CommUnknown : 63|1@1+ (1,0) [0|1] ""  CANOE
 SG_ FD14_AOR_CommUnknown : 62|1@1+ (1,0) [0|1] ""  CANOE
 SG_ FD14_BOL_CommUnknown : 61|1@1+ (1,0) [0|1] ""  CANOE
 SG_ FD14_AOL_CommUnknown : 60|1@1+ (1,0) [0|1] ""  CANOE
 SG_ FD14_RSL_CommUnknown : 59|1@1+ (1,0) [0|1] ""  CANOE
 SG_ FD14_ROL_CommUnknown : 58|1@1+ (1,0) [0|1] ""  CANOE
 SG_ FD14_RIL_CommUnknown : 57|1@1+ (1,0) [0|1] ""  CANOE
 SG_ FD14_RIR_CommUnknown : 56|1@1+ (1,0) [0|1] ""  CANOE
 SG_ FD14_ROR_CommUnknown : 55|1@1+ (1,0) [0|1] ""  CANOE
 SG_ FD14_RSR_CommUnknown : 54|1@1+ (1,0) [0|1] ""  CANOE
 SG_ FD14_FSL_CommUnknown : 53|1@1+ (1,0) [0|1] ""  CANOE
 SG_ FD14_FOL_CommUnknown : 52|1@1+ (1,0) [0|1] ""  CANOE
 SG_ FD14_FIL_CommUnknown : 51|1@1+ (1,0) [0|1] ""  CANOE
 SG_ FD14_FIR_CommUnknown : 50|1@1+ (1,0) [0|1] ""  CANOE
 SG_ FD14_FOR_CommUnknown : 49|1@1+ (1,0) [0|1] ""  CANOE
 SG_ FD14_FSR_CommUnknown : 48|1@1+ (1,0) [0|1] ""  CANOE
 SG_ FD14_BOR_hardware_Fault : 47|1@1+ (1,0) [0|1] ""  CANOE
 SG_ FD14_AOR_hardware_Fault : 46|1@1+ (1,0) [0|1] ""  CANOE
 SG_ FD14_BOL_hardware_Fault : 45|1@1+ (1,0) [0|1] ""  CANOE
 SG_ FD14_AOL_hardware_Fault : 44|1@1+ (1,0) [0|1] ""  CANOE
 SG_ FD14_RSL_hardware_Fault : 43|1@1+ (1,0) [0|1] ""  CANOE
 SG_ FD14_ROL_hardware_Fault : 42|1@1+ (1,0) [0|1] ""  CANOE
 SG_ FD14_RIL_hardware_Fault : 41|1@1+ (1,0) [0|1] ""  CANOE
 SG_ FD14_RIR_hardware_Fault : 40|1@1+ (1,0) [0|1] ""  CANOE
 SG_ FD14_ROR_hardware_Fault : 39|1@1+ (1,0) [0|1] ""  CANOE
 SG_ FD14_RSR_hardware_Fault : 38|1@1+ (1,0) [0|1] ""  CANOE
 SG_ FD14_FSL_hardware_Fault : 37|1@1+ (1,0) [0|1] ""  CANOE
 SG_ FD14_FOL_hardware_Fault : 36|1@1+ (1,0) [0|1] ""  CANOE
 SG_ FD14_FIL_hardware_Fault : 35|1@1+ (1,0) [0|1] ""  CANOE
 SG_ FD14_FIR_hardware_Fault : 34|1@1+ (1,0) [0|1] ""  CANOE
 SG_ FD14_FOR_hardware_Fault : 33|1@1+ (1,0) [0|1] ""  CANOE
 SG_ FD14_FSR_hardware_Fault : 32|1@1+ (1,0) [0|1] ""  CANOE
 SG_ FD14_FIR_comm_Fault : 18|1@1+ (1,0) [0|1] ""  CANOE
 SG_ FD14_BOR_comm_Fault : 31|1@1+ (1,0) [0|1] ""  CANOE
 SG_ FD14_AOR_comm_Fault : 30|1@1+ (1,0) [0|1] ""  CANOE
 SG_ FD14_BOL_comm_Fault : 29|1@1+ (1,0) [0|1] ""  CANOE
 SG_ FD14_AOL_comm_Fault : 28|1@1+ (1,0) [0|1] ""  CANOE
 SG_ FD14_RSL_comm_Fault : 27|1@1+ (1,0) [0|1] ""  CANOE
 SG_ FD14_ROL_comm_Fault : 26|1@1+ (1,0) [0|1] ""  CANOE
 SG_ FD14_RIL_comm_Fault : 25|1@1+ (1,0) [0|1] ""  CANOE
 SG_ FD14_RIR_comm_Fault : 24|1@1+ (1,0) [0|1] ""  CANOE
 SG_ FD14_ROR_comm_Fault : 23|1@1+ (1,0) [0|1] ""  CANOE
 SG_ FD14_RSR_comm_Fault : 22|1@1+ (1,0) [0|1] ""  CANOE
 SG_ FD14_FSL_comm_Fault : 21|1@1+ (1,0) [0|1] ""  CANOE
 SG_ FD14_FOL_comm_Fault : 20|1@1+ (1,0) [0|1] ""  CANOE
 SG_ FD14_FIL_comm_Fault : 19|1@1+ (1,0) [0|1] ""  CANOE
 SG_ FD14_FOR_comm_Fault : 17|1@1+ (1,0) [0|1] ""  CANOE
 SG_ FD14_FSR_comm_Fault : 16|1@1+ (1,0) [0|1] ""  CANOE
 SG_ FD14_RSR_overTemp_Fault : 6|1@1+ (1,0) [0|1] ""  CANOE
 SG_ FD14_RSL_overTemp_Fault : 11|1@1+ (1,0) [0|1] ""  CANOE
 SG_ FD14_ROR_overTemp_Fault : 7|1@1+ (1,0) [0|1] ""  CANOE
 SG_ FD14_ROL_overTemp_Fault : 10|1@1+ (1,0) [0|1] ""  CANOE
 SG_ FD14_RIR_overTemp_Fault : 8|1@1+ (1,0) [0|1] ""  CANOE
 SG_ FD14_RIL_overTemp_Fault : 9|1@1+ (1,0) [0|1] ""  CANOE
 SG_ FD14_FSL_overTemp_Fault : 5|1@1+ (1,0) [0|1] ""  CANOE
 SG_ FD14_FOL_overTemp_Fault : 4|1@1+ (1,0) [0|1] ""  CANOE
 SG_ FD14_FIR_overTemp_Fault : 2|1@1+ (1,0) [0|1] ""  CANOE
 SG_ FD14_FIL_overTemp_Fault : 3|1@1+ (1,0) [0|1] ""  CANOE
 SG_ FD14_BOR_overTemp_Fault : 15|1@1+ (1,0) [0|1] ""  CANOE
 SG_ FD14_BOL_overTemp_Fault : 13|1@1+ (1,0) [0|1] ""  CANOE
 SG_ FD14_AOR_overTemp_Fault : 14|1@1+ (1,0) [0|1] ""  CANOE
 SG_ FD14_AOL_overTemp_Fault : 12|1@1+ (1,0) [0|1] ""  CANOE
 SG_ FD14_FOR_overTemp_Fault : 1|1@1+ (1,0) [0|1] ""  CANOE
 SG_ FD14_FSR_overTemp_Fault : 0|1@1+ (1,0) [0|1] ""  CANOE

BO_ 2654552195 Distance_Point_Map_0: 64 CVADAS
 SG_ FD14_Point_Map_Cruising_Age_7 : 482|6@1+ (1,0) [0|63] ""  CANOE
 SG_ FD14_Point_Map_Cruising_Age_6 : 418|6@1+ (1,0) [0|63] ""  CANOE
 SG_ FD14_Point_Map_Cruising_Age_5 : 354|6@1+ (1,0) [0|63] ""  CANOE
 SG_ FD14_Point_Map_Cruising_Age_4 : 290|6@1+ (1,0) [0|63] ""  CANOE
 SG_ FD14_Point_Map_Cruising_Age_3 : 226|6@1+ (1,0) [0|63] ""  CANOE
 SG_ FD14_Point_Map_Cruising_Age_2 : 162|6@1+ (1,0) [0|63] ""  CANOE
 SG_ FD14_Point_Map_Cruising_Age_1 : 98|6@1+ (1,0) [0|63] ""  CANOE
 SG_ FD14_Point_Map_Cruising_Age_0 : 34|6@1+ (1,0) [0|63] ""  CANOE
 SG_ FD14_Point_Map_Reserved_7 : 504|8@1+ (1,0) [0|255] ""  CANOE
 SG_ FD14_Point_Map_Reserved_6 : 440|8@1+ (1,0) [0|255] ""  CANOE
 SG_ FD14_Point_Map_Reserved_5 : 376|8@1+ (1,0) [0|255] ""  CANOE
 SG_ FD14_Point_Map_Reserved_4 : 312|8@1+ (1,0) [0|255] ""  CANOE
 SG_ FD14_Point_Map_Reserved_3 : 248|8@1+ (1,0) [0|255] ""  CANOE
 SG_ FD14_Point_Map_Reserved_2 : 184|8@1+ (1,0) [0|255] ""  CANOE
 SG_ FD14_Point_Map_Reserved_1 : 120|8@1+ (1,0) [0|255] ""  CANOE
 SG_ FD14_Point_Map_Reserved_0 : 56|8@1+ (1,0) [0|255] ""  CANOE
 SG_ FD14_Point_Map_Age_7 : 496|8@1+ (1,0) [0|255] ""  CANOE
 SG_ FD14_Point_Map_Confidence_7 : 488|8@1+ (1,0) [0|255] ""  CANOE
 SG_ FD14_Point_Map_Height_7 : 480|2@1+ (1,0) [0|3] ""  CANOE
 SG_ FD14_Point_Map_Y_7 : 464|16@1- (1,0) [-32768|32767] ""  CANOE
 SG_ FD14_Point_Map_X_7 : 448|16@1- (1,0) [-32768|32767] ""  CANOE
 SG_ FD14_Point_Map_Age_6 : 432|8@1+ (1,0) [0|255] ""  CANOE
 SG_ FD14_Point_Map_Confidence_6 : 424|8@1+ (1,0) [0|255] ""  CANOE
 SG_ FD14_Point_Map_Height_6 : 416|2@1+ (1,0) [0|3] ""  CANOE
 SG_ FD14_Point_Map_Y_6 : 400|16@1- (1,0) [-32768|32767] ""  CANOE
 SG_ FD14_Point_Map_X_6 : 384|16@1- (1,0) [-32768|32767] ""  CANOE
 SG_ FD14_Point_Map_Age_5 : 368|8@1+ (1,0) [0|255] ""  CANOE
 SG_ FD14_Point_Map_Confidence_5 : 360|8@1+ (1,0) [0|255] ""  CANOE
 SG_ FD14_Point_Map_Height_5 : 352|2@1+ (1,0) [0|3] ""  CANOE
 SG_ FD14_Point_Map_Y_5 : 336|16@1- (1,0) [-32768|32767] ""  CANOE
 SG_ FD14_Point_Map_X_5 : 320|16@1- (1,0) [-32768|32767] ""  CANOE
 SG_ FD14_Point_Map_Age_4 : 304|8@1+ (1,0) [0|255] ""  CANOE
 SG_ FD14_Point_Map_Confidence_4 : 296|8@1+ (1,0) [0|255] ""  CANOE
 SG_ FD14_Point_Map_Height_4 : 288|2@1+ (1,0) [0|3] ""  CANOE
 SG_ FD14_Point_Map_Y_4 : 272|16@1- (1,0) [-32768|32767] ""  CANOE
 SG_ FD14_Point_Map_X_4 : 256|16@1- (1,0) [-32768|32767] ""  CANOE
 SG_ FD14_Point_Map_Age_3 : 240|8@1+ (1,0) [0|255] ""  CANOE
 SG_ FD14_Point_Map_Confidence_3 : 232|8@1+ (1,0) [0|255] ""  CANOE
 SG_ FD14_Point_Map_Height_3 : 224|2@1+ (1,0) [0|3] ""  CANOE
 SG_ FD14_Point_Map_Y_3 : 208|16@1- (1,0) [-32768|32767] ""  CANOE
 SG_ FD14_Point_Map_X_3 : 192|16@1- (1,0) [-32768|32767] ""  CANOE
 SG_ FD14_Point_Map_Age_2 : 176|8@1+ (1,0) [0|255] ""  CANOE
 SG_ FD14_Point_Map_Confidence_2 : 168|8@1+ (1,0) [0|255] ""  CANOE
 SG_ FD14_Point_Map_Height_2 : 160|2@1+ (1,0) [0|3] ""  CANOE
 SG_ FD14_Point_Map_Y_2 : 144|16@1- (1,0) [-32768|32767] ""  CANOE
 SG_ FD14_Point_Map_X_2 : 128|16@1- (1,0) [-32768|32767] ""  CANOE
 SG_ FD14_Point_Map_Age_1 : 112|8@1+ (1,0) [0|255] ""  CANOE
 SG_ FD14_Point_Map_Confidence_1 : 104|8@1+ (1,0) [0|255] ""  CANOE
 SG_ FD14_Point_Map_Height_1 : 96|2@1+ (1,0) [0|3] ""  CANOE
 SG_ FD14_Point_Map_Y_1 : 80|16@1- (1,0) [-32768|32767] ""  CANOE
 SG_ FD14_Point_Map_X_1 : 64|16@1- (1,0) [-32768|32767] ""  CANOE
 SG_ FD14_Point_Map_Age_0 : 48|8@1+ (1,0) [0|255] ""  CANOE
 SG_ FD14_Point_Map_Confidence_0 : 40|8@1+ (1,0) [0|255] ""  CANOE
 SG_ FD14_Point_Map_Height_0 : 32|2@1+ (1,0) [0|3] ""  CANOE
 SG_ FD14_Point_Map_Y_0 : 16|16@1- (1,0) [-32768|32767] ""  CANOE
 SG_ FD14_Point_Map_X_0 : 0|16@1- (1,0) [-32768|32767] ""  CANOE

BO_ 2654552196 Distance_Point_Map_1: 64 CVADAS
 SG_ FD14_Point_Map_Cruising_Age_15 : 482|6@1+ (1,0) [0|63] ""  CANOE
 SG_ FD14_Point_Map_Cruising_Age_14 : 418|6@1+ (1,0) [0|63] ""  CANOE
 SG_ FD14_Point_Map_Cruising_Age_13 : 354|6@1+ (1,0) [0|63] ""  CANOE
 SG_ FD14_Point_Map_Cruising_Age_12 : 290|6@1+ (1,0) [0|63] ""  CANOE
 SG_ FD14_Point_Map_Cruising_Age_11 : 226|6@1+ (1,0) [0|63] ""  CANOE
 SG_ FD14_Point_Map_Cruising_Age_10 : 162|6@1+ (1,0) [0|63] ""  CANOE
 SG_ FD14_Point_Map_Cruising_Age_9 : 98|6@1+ (1,0) [0|63] ""  CANOE
 SG_ FD14_Point_Map_Cruising_Age_8 : 34|6@1+ (1,0) [0|63] ""  CANOE
 SG_ FD14_Point_Map_Reserved_8 : 56|8@1+ (1,0) [0|255] ""  CANOE
 SG_ FD14_Point_Map_Age_8 : 48|8@1+ (1,0) [0|255] ""  CANOE
 SG_ FD14_Point_Map_Confidence_8 : 40|8@1+ (1,0) [0|255] ""  CANOE
 SG_ FD14_Point_Map_Height_8 : 32|2@1+ (1,0) [0|3] ""  CANOE
 SG_ FD14_Point_Map_Y_8 : 16|16@1- (1,0) [-32768|32767] ""  CANOE
 SG_ FD14_Point_Map_X_8 : 0|16@1- (1,0) [-32768|32767] ""  CANOE
 SG_ FD14_Point_Map_Reserved_15 : 504|8@1+ (1,0) [0|255] ""  CANOE
 SG_ FD14_Point_Map_Reserved_14 : 440|8@1+ (1,0) [0|255] ""  CANOE
 SG_ FD14_Point_Map_Reserved_13 : 376|8@1+ (1,0) [0|255] ""  CANOE
 SG_ FD14_Point_Map_Reserved_12 : 312|8@1+ (1,0) [0|255] ""  CANOE
 SG_ FD14_Point_Map_Reserved_11 : 248|8@1+ (1,0) [0|255] ""  CANOE
 SG_ FD14_Point_Map_Reserved_10 : 184|8@1+ (1,0) [0|255] ""  CANOE
 SG_ FD14_Point_Map_Reserved_9 : 120|8@1+ (1,0) [0|255] ""  CANOE
 SG_ FD14_Point_Map_Age_15 : 496|8@1+ (1,0) [0|255] ""  CANOE
 SG_ FD14_Point_Map_Confidence_15 : 488|8@1+ (1,0) [0|255] ""  CANOE
 SG_ FD14_Point_Map_Height_15 : 480|2@1+ (1,0) [0|3] ""  CANOE
 SG_ FD14_Point_Map_Y_15 : 464|16@1- (1,0) [-32768|32767] ""  CANOE
 SG_ FD14_Point_Map_X_15 : 448|16@1- (1,0) [-32768|32767] ""  CANOE
 SG_ FD14_Point_Map_Age_14 : 432|8@1+ (1,0) [0|255] ""  CANOE
 SG_ FD14_Point_Map_Confidence_14 : 424|8@1+ (1,0) [0|255] ""  CANOE
 SG_ FD14_Point_Map_Height_14 : 416|2@1+ (1,0) [0|3] ""  CANOE
 SG_ FD14_Point_Map_Y_14 : 400|16@1- (1,0) [-32768|32767] ""  CANOE
 SG_ FD14_Point_Map_X_14 : 384|16@1- (1,0) [-32768|32767] ""  CANOE
 SG_ FD14_Point_Map_Age_13 : 368|8@1+ (1,0) [0|255] ""  CANOE
 SG_ FD14_Point_Map_Confidence_13 : 360|8@1+ (1,0) [0|255] ""  CANOE
 SG_ FD14_Point_Map_Height_13 : 352|2@1+ (1,0) [0|3] ""  CANOE
 SG_ FD14_Point_Map_Y_13 : 336|16@1- (1,0) [-32768|32767] ""  CANOE
 SG_ FD14_Point_Map_X_13 : 320|16@1- (1,0) [-32768|32767] ""  CANOE
 SG_ FD14_Point_Map_Age_12 : 304|8@1+ (1,0) [0|255] ""  CANOE
 SG_ FD14_Point_Map_Confidence_12 : 296|8@1+ (1,0) [0|255] ""  CANOE
 SG_ FD14_Point_Map_Height_12 : 288|2@1+ (1,0) [0|3] ""  CANOE
 SG_ FD14_Point_Map_Y_12 : 272|16@1- (1,0) [-32768|32767] ""  CANOE
 SG_ FD14_Point_Map_X_12 : 256|16@1- (1,0) [-32768|32767] ""  CANOE
 SG_ FD14_Point_Map_Age_11 : 240|8@1+ (1,0) [0|255] ""  CANOE
 SG_ FD14_Point_Map_Confidence_11 : 232|8@1+ (1,0) [0|255] ""  CANOE
 SG_ FD14_Point_Map_Height_11 : 224|2@1+ (1,0) [0|3] ""  CANOE
 SG_ FD14_Point_Map_Y_11 : 208|16@1- (1,0) [-32768|32767] ""  CANOE
 SG_ FD14_Point_Map_X_11 : 192|16@1- (1,0) [-32768|32767] ""  CANOE
 SG_ FD14_Point_Map_Age_10 : 176|8@1+ (1,0) [0|255] ""  CANOE
 SG_ FD14_Point_Map_Confidence_10 : 168|8@1+ (1,0) [0|255] ""  CANOE
 SG_ FD14_Point_Map_Height_10 : 160|2@1+ (1,0) [0|3] ""  CANOE
 SG_ FD14_Point_Map_Y_10 : 144|16@1- (1,0) [-32768|32767] ""  CANOE
 SG_ FD14_Point_Map_X_10 : 128|16@1- (1,0) [-32768|32767] ""  CANOE
 SG_ FD14_Point_Map_Age_9 : 112|8@1+ (1,0) [0|255] ""  CANOE
 SG_ FD14_Point_Map_Confidence_9 : 104|8@1+ (1,0) [0|255] ""  CANOE
 SG_ FD14_Point_Map_Height_9 : 96|2@1+ (1,0) [0|3] ""  CANOE
 SG_ FD14_Point_Map_Y_9 : 80|16@1- (1,0) [-32768|32767] ""  CANOE
 SG_ FD14_Point_Map_X_9 : 64|16@1- (1,0) [-32768|32767] ""  CANOE

BO_ 2654552197 Distance_Point_Map_2: 64 CVADAS
 SG_ FD14_Point_Map_Cruising_Age_23 : 482|6@1+ (1,0) [0|63] ""  CANOE
 SG_ FD14_Point_Map_Cruising_Age_22 : 418|6@1+ (1,0) [0|63] ""  CANOE
 SG_ FD14_Point_Map_Cruising_Age_21 : 354|6@1+ (1,0) [0|63] ""  CANOE
 SG_ FD14_Point_Map_Cruising_Age_20 : 290|6@1+ (1,0) [0|63] ""  CANOE
 SG_ FD14_Point_Map_Cruising_Age_19 : 226|6@1+ (1,0) [0|63] ""  CANOE
 SG_ FD14_Point_Map_Cruising_Age_18 : 162|6@1+ (1,0) [0|63] ""  CANOE
 SG_ FD14_Point_Map_Cruising_Age_17 : 98|6@1+ (1,0) [0|63] ""  CANOE
 SG_ FD14_Point_Map_Cruising_Age_16 : 34|6@1+ (1,0) [0|63] ""  CANOE
 SG_ FD14_Point_Map_Reserved_17 : 120|8@1+ (1,0) [0|255] ""  CANOE
 SG_ FD14_Point_Map_Height_17 : 96|2@1+ (1,0) [0|3] ""  CANOE
 SG_ FD14_Point_Map_Age_17 : 112|8@1+ (1,0) [0|255] ""  CANOE
 SG_ FD14_Point_Map_Confidence_17 : 104|8@1+ (1,0) [0|255] ""  CANOE
 SG_ FD14_Point_Map_Y_17 : 80|16@1- (1,0) [-32768|32767] ""  CANOE
 SG_ FD14_Point_Map_X_17 : 64|16@1- (1,0) [-32768|32767] ""  CANOE
 SG_ FD14_Point_Map_Reserved_16 : 56|8@1+ (1,0) [0|255] ""  CANOE
 SG_ FD14_Point_Map_Age_16 : 48|8@1+ (1,0) [0|255] ""  CANOE
 SG_ FD14_Point_Map_Confidence_16 : 40|8@1+ (1,0) [0|255] ""  CANOE
 SG_ FD14_Point_Map_Height_16 : 32|2@1+ (1,0) [0|3] ""  CANOE
 SG_ FD14_Point_Map_Y_16 : 16|16@1- (1,0) [-32768|32767] ""  CANOE
 SG_ FD14_Point_Map_X_16 : 0|16@1- (1,0) [-32768|32767] ""  CANOE
 SG_ FD14_Point_Map_Reserved_23 : 504|8@1+ (1,0) [0|255] ""  CANOE
 SG_ FD14_Point_Map_Reserved_22 : 440|8@1+ (1,0) [0|255] ""  CANOE
 SG_ FD14_Point_Map_Reserved_21 : 376|8@1+ (1,0) [0|255] ""  CANOE
 SG_ FD14_Point_Map_Reserved_20 : 312|8@1+ (1,0) [0|255] ""  CANOE
 SG_ FD14_Point_Map_Reserved_19 : 248|8@1+ (1,0) [0|255] ""  CANOE
 SG_ FD14_Point_Map_Reserved_18 : 184|8@1+ (1,0) [0|255] ""  CANOE
 SG_ FD14_Point_Map_Age_23 : 496|8@1+ (1,0) [0|255] ""  CANOE
 SG_ FD14_Point_Map_Confidence_23 : 488|8@1+ (1,0) [0|255] ""  CANOE
 SG_ FD14_Point_Map_Height_23 : 480|2@1+ (1,0) [0|3] ""  CANOE
 SG_ FD14_Point_Map_Y_23 : 464|16@1- (1,0) [-32768|32767] ""  CANOE
 SG_ FD14_Point_Map_X_23 : 448|16@1- (1,0) [-32768|32767] ""  CANOE
 SG_ FD14_Point_Map_Age_22 : 432|8@1+ (1,0) [0|255] ""  CANOE
 SG_ FD14_Point_Map_Confidence_22 : 424|8@1+ (1,0) [0|255] ""  CANOE
 SG_ FD14_Point_Map_Height_22 : 416|2@1+ (1,0) [0|3] ""  CANOE
 SG_ FD14_Point_Map_Y_22 : 400|16@1- (1,0) [-32768|32767] ""  CANOE
 SG_ FD14_Point_Map_X_22 : 384|16@1- (1,0) [-32768|32767] ""  CANOE
 SG_ FD14_Point_Map_Age_21 : 368|8@1+ (1,0) [0|255] ""  CANOE
 SG_ FD14_Point_Map_Confidence_21 : 360|8@1+ (1,0) [0|255] ""  CANOE
 SG_ FD14_Point_Map_Height_21 : 352|2@1+ (1,0) [0|3] ""  CANOE
 SG_ FD14_Point_Map_Y_21 : 336|16@1- (1,0) [-32768|32767] ""  CANOE
 SG_ FD14_Point_Map_X_21 : 320|16@1- (1,0) [-32768|32767] ""  CANOE
 SG_ FD14_Point_Map_Age_20 : 304|8@1+ (1,0) [0|255] ""  CANOE
 SG_ FD14_Point_Map_Confidence_20 : 296|8@1+ (1,0) [0|255] ""  CANOE
 SG_ FD14_Point_Map_Height_20 : 288|2@1+ (1,0) [0|3] ""  CANOE
 SG_ FD14_Point_Map_Y_20 : 272|16@1- (1,0) [-32768|32767] ""  CANOE
 SG_ FD14_Point_Map_X_20 : 256|16@1- (1,0) [-32768|32767] ""  CANOE
 SG_ FD14_Point_Map_Age_19 : 240|8@1+ (1,0) [0|255] ""  CANOE
 SG_ FD14_Point_Map_Confidence_19 : 232|8@1+ (1,0) [0|255] ""  CANOE
 SG_ FD14_Point_Map_Height_19 : 224|2@1+ (1,0) [0|3] ""  CANOE
 SG_ FD14_Point_Map_Y_19 : 208|16@1- (1,0) [-32768|32767] ""  CANOE
 SG_ FD14_Point_Map_X_19 : 192|16@1- (1,0) [-32768|32767] ""  CANOE
 SG_ FD14_Point_Map_Age_18 : 176|8@1+ (1,0) [0|255] ""  CANOE
 SG_ FD14_Point_Map_Confidence_18 : 168|8@1+ (1,0) [0|255] ""  CANOE
 SG_ FD14_Point_Map_Height_18 : 160|2@1+ (1,0) [0|3] ""  CANOE
 SG_ FD14_Point_Map_Y_18 : 144|16@1- (1,0) [-32768|32767] ""  CANOE
 SG_ FD14_Point_Map_X_18 : 128|16@1- (1,0) [-32768|32767] ""  CANOE

BO_ 2654552198 Distance_Point_Map_3: 64 CVADAS
 SG_ FD14_Point_Map_Cruising_Age_31 : 482|6@1+ (1,0) [0|63] ""  CANOE
 SG_ FD14_Point_Map_Cruising_Age_30 : 418|6@1+ (1,0) [0|63] ""  CANOE
 SG_ FD14_Point_Map_Cruising_Age_29 : 354|6@1+ (1,0) [0|63] ""  CANOE
 SG_ FD14_Point_Map_Cruising_Age_28 : 290|6@1+ (1,0) [0|63] ""  CANOE
 SG_ FD14_Point_Map_Cruising_Age_27 : 226|6@1+ (1,0) [0|63] ""  CANOE
 SG_ FD14_Point_Map_Cruising_Age_26 : 162|6@1+ (1,0) [0|63] ""  CANOE
 SG_ FD14_Point_Map_Cruising_Age_25 : 98|6@1+ (1,0) [0|63] ""  CANOE
 SG_ FD14_Point_Map_Cruising_Age_24 : 34|6@1+ (1,0) [0|63] ""  CANOE
 SG_ FD14_Point_Map_Reserved_26 : 184|8@1+ (1,0) [0|255] ""  CANOE
 SG_ FD14_Point_Map_Age_26 : 176|8@1+ (1,0) [0|255] ""  CANOE
 SG_ FD14_Point_Map_Confidence_26 : 168|8@1+ (1,0) [0|255] ""  CANOE
 SG_ FD14_Point_Map_Height_26 : 160|2@1+ (1,0) [0|3] ""  CANOE
 SG_ FD14_Point_Map_Y_26 : 144|16@1- (1,0) [-32768|32767] ""  CANOE
 SG_ FD14_Point_Map_X_26 : 128|16@1- (1,0) [-32768|32767] ""  CANOE
 SG_ FD14_Point_Map_Reserved_25 : 120|8@1+ (1,0) [0|255] ""  CANOE
 SG_ FD14_Point_Map_Age_25 : 112|8@1+ (1,0) [0|255] ""  CANOE
 SG_ FD14_Point_Map_Confidence_25 : 104|8@1+ (1,0) [0|255] ""  CANOE
 SG_ FD14_Point_Map_Height_25 : 96|2@1+ (1,0) [0|3] ""  CANOE
 SG_ FD14_Point_Map_Y_25 : 80|16@1- (1,0) [-32768|32767] ""  CANOE
 SG_ FD14_Point_Map_X_25 : 64|16@1- (1,0) [-32768|32767] ""  CANOE
 SG_ FD14_Point_Map_Reserved_24 : 56|8@1+ (1,0) [0|255] ""  CANOE
 SG_ FD14_Point_Map_Age_24 : 48|8@1+ (1,0) [0|255] ""  CANOE
 SG_ FD14_Point_Map_Confidence_24 : 40|8@1+ (1,0) [0|255] ""  CANOE
 SG_ FD14_Point_Map_Height_24 : 32|2@1+ (1,0) [0|3] ""  CANOE
 SG_ FD14_Point_Map_Y_24 : 16|16@1- (1,0) [-32768|32767] ""  CANOE
 SG_ FD14_Point_Map_X_24 : 0|16@1- (1,0) [-32768|32767] ""  CANOE
 SG_ FD14_Point_Map_Reserved_31 : 504|8@1+ (1,0) [0|255] ""  CANOE
 SG_ FD14_Point_Map_Reserved_30 : 440|8@1+ (1,0) [0|255] ""  CANOE
 SG_ FD14_Point_Map_Reserved_29 : 376|8@1+ (1,0) [0|255] ""  CANOE
 SG_ FD14_Point_Map_Reserved_28 : 312|8@1+ (1,0) [0|255] ""  CANOE
 SG_ FD14_Point_Map_Reserved_27 : 248|8@1+ (1,0) [0|255] ""  CANOE
 SG_ FD14_Point_Map_Age_31 : 496|8@1+ (1,0) [0|255] ""  CANOE
 SG_ FD14_Point_Map_Confidence_31 : 488|8@1+ (1,0) [0|255] ""  CANOE
 SG_ FD14_Point_Map_Height_31 : 480|2@1+ (1,0) [0|3] ""  CANOE
 SG_ FD14_Point_Map_Y_31 : 464|16@1- (1,0) [-32768|32767] ""  CANOE
 SG_ FD14_Point_Map_X_31 : 448|16@1- (1,0) [-32768|32767] ""  CANOE
 SG_ FD14_Point_Map_Age_30 : 432|8@1+ (1,0) [0|255] ""  CANOE
 SG_ FD14_Point_Map_Confidence_30 : 424|8@1+ (1,0) [0|255] ""  CANOE
 SG_ FD14_Point_Map_Height_30 : 416|2@1+ (1,0) [0|3] ""  CANOE
 SG_ FD14_Point_Map_Y_30 : 400|16@1- (1,0) [-32768|32767] ""  CANOE
 SG_ FD14_Point_Map_X_30 : 384|16@1- (1,0) [-32768|32767] ""  CANOE
 SG_ FD14_Point_Map_Age_29 : 368|8@1+ (1,0) [0|255] ""  CANOE
 SG_ FD14_Point_Map_Confidence_29 : 360|8@1+ (1,0) [0|255] ""  CANOE
 SG_ FD14_Point_Map_Height_29 : 352|2@1+ (1,0) [0|3] ""  CANOE
 SG_ FD14_Point_Map_Y_29 : 336|16@1- (1,0) [-32768|32767] ""  CANOE
 SG_ FD14_Point_Map_X_29 : 320|16@1- (1,0) [-32768|32767] ""  CANOE
 SG_ FD14_Point_Map_Age_28 : 304|8@1+ (1,0) [0|255] ""  CANOE
 SG_ FD14_Point_Map_Confidence_28 : 296|8@1+ (1,0) [0|255] ""  CANOE
 SG_ FD14_Point_Map_Height_28 : 288|2@1+ (1,0) [0|3] ""  CANOE
 SG_ FD14_Point_Map_Y_28 : 272|16@1- (1,0) [-32768|32767] ""  CANOE
 SG_ FD14_Point_Map_X_27 : 192|16@1- (1,0) [-32768|32767] ""  CANOE
 SG_ FD14_Point_Map_Age_27 : 240|8@1+ (1,0) [0|255] ""  CANOE
 SG_ FD14_Point_Map_Confidence_27 : 232|8@1+ (1,0) [0|255] ""  CANOE
 SG_ FD14_Point_Map_Height_27 : 224|2@1+ (1,0) [0|3] ""  CANOE
 SG_ FD14_Point_Map_Y_27 : 208|16@1- (1,0) [-32768|32767] ""  CANOE
 SG_ FD14_Point_Map_X_28 : 256|16@1- (1,0) [-32768|32767] ""  CANOE

BO_ 2654552199 Distance_Point_Map_4: 64 CVADAS
 SG_ FD14_Point_Map_Cruising_Age_39 : 482|6@1+ (1,0) [0|63] ""  CANOE
 SG_ FD14_Point_Map_Cruising_Age_38 : 418|6@1+ (1,0) [0|63] ""  CANOE
 SG_ FD14_Point_Map_Cruising_Age_37 : 354|6@1+ (1,0) [0|63] ""  CANOE
 SG_ FD14_Point_Map_Cruising_Age_36 : 290|6@1+ (1,0) [0|63] ""  CANOE
 SG_ FD14_Point_Map_Cruising_Age_35 : 226|6@1+ (1,0) [0|63] ""  CANOE
 SG_ FD14_Point_Map_Cruising_Age_34 : 162|6@1+ (1,0) [0|63] ""  CANOE
 SG_ FD14_Point_Map_Cruising_Age_33 : 98|6@1+ (1,0) [0|63] ""  CANOE
 SG_ FD14_Point_Map_Cruising_Age_32 : 34|6@1+ (1,0) [0|63] ""  CANOE
 SG_ FD14_Point_Map_Reserved_35 : 248|8@1+ (1,0) [0|255] ""  CANOE
 SG_ FD14_Point_Map_Age_35 : 240|8@1+ (1,0) [0|255] ""  CANOE
 SG_ FD14_Point_Map_Confidence_35 : 232|8@1+ (1,0) [0|255] ""  CANOE
 SG_ FD14_Point_Map_Height_35 : 224|2@1+ (1,0) [0|3] ""  CANOE
 SG_ FD14_Point_Map_Y_35 : 208|16@1- (1,0) [-32768|32767] ""  CANOE
 SG_ FD14_Point_Map_X_35 : 192|16@1- (1,0) [-32768|32767] ""  CANOE
 SG_ FD14_Point_Map_Reserved_34 : 184|8@1+ (1,0) [0|255] ""  CANOE
 SG_ FD14_Point_Map_Age_34 : 176|8@1+ (1,0) [0|255] ""  CANOE
 SG_ FD14_Point_Map_Confidence_34 : 168|8@1+ (1,0) [0|255] ""  CANOE
 SG_ FD14_Point_Map_Height_34 : 160|2@1+ (1,0) [0|3] ""  CANOE
 SG_ FD14_Point_Map_Y_34 : 144|16@1- (1,0) [-32768|32767] ""  CANOE
 SG_ FD14_Point_Map_X_34 : 128|16@1- (1,0) [-32768|32767] ""  CANOE
 SG_ FD14_Point_Map_Reserved_33 : 120|8@1+ (1,0) [0|255] ""  CANOE
 SG_ FD14_Point_Map_Age_33 : 112|8@1+ (1,0) [0|255] ""  CANOE
 SG_ FD14_Point_Map_Confidence_33 : 104|8@1+ (1,0) [0|255] ""  CANOE
 SG_ FD14_Point_Map_Height_33 : 96|2@1+ (1,0) [0|3] ""  CANOE
 SG_ FD14_Point_Map_Y_33 : 80|16@1- (1,0) [-32768|32767] ""  CANOE
 SG_ FD14_Point_Map_X_33 : 64|16@1- (1,0) [-32768|32767] ""  CANOE
 SG_ FD14_Point_Map_Reserved_32 : 56|8@1+ (1,0) [0|255] ""  CANOE
 SG_ FD14_Point_Map_Age_32 : 48|8@1+ (1,0) [0|255] ""  CANOE
 SG_ FD14_Point_Map_Confidence_32 : 40|8@1+ (1,0) [0|255] ""  CANOE
 SG_ FD14_Point_Map_Height_32 : 32|2@1+ (1,0) [0|3] ""  CANOE
 SG_ FD14_Point_Map_Y_32 : 16|16@1- (1,0) [-32768|32767] ""  CANOE
 SG_ FD14_Point_Map_X_32 : 0|16@1- (1,0) [-32768|32767] ""  CANOE
 SG_ FD14_Point_Map_Reserved_39 : 504|8@1+ (1,0) [0|255] ""  CANOE
 SG_ FD14_Point_Map_Reserved_38 : 440|8@1+ (1,0) [0|255] ""  CANOE
 SG_ FD14_Point_Map_Reserved_37 : 376|8@1+ (1,0) [0|255] ""  CANOE
 SG_ FD14_Point_Map_Reserved_36 : 312|8@1+ (1,0) [0|255] ""  CANOE
 SG_ FD14_Point_Map_Age_39 : 496|8@1+ (1,0) [0|255] ""  CANOE
 SG_ FD14_Point_Map_Confidence_39 : 488|8@1+ (1,0) [0|255] ""  CANOE
 SG_ FD14_Point_Map_Height_39 : 480|2@1+ (1,0) [0|3] ""  CANOE
 SG_ FD14_Point_Map_Y_39 : 464|16@1- (1,0) [-32768|32767] ""  CANOE
 SG_ FD14_Point_Map_X_39 : 448|16@1- (1,0) [-32768|32767] ""  CANOE
 SG_ FD14_Point_Map_Age_38 : 432|8@1+ (1,0) [0|255] ""  CANOE
 SG_ FD14_Point_Map_Confidence_38 : 424|8@1+ (1,0) [0|255] ""  CANOE
 SG_ FD14_Point_Map_Height_38 : 416|2@1+ (1,0) [0|3] ""  CANOE
 SG_ FD14_Point_Map_Y_38 : 400|16@1- (1,0) [-32768|32767] ""  CANOE
 SG_ FD14_Point_Map_X_38 : 384|16@1- (1,0) [-32768|32767] ""  CANOE
 SG_ FD14_Point_Map_Age_37 : 368|8@1+ (1,0) [0|255] ""  CANOE
 SG_ FD14_Point_Map_Confidence_37 : 360|8@1+ (1,0) [0|255] ""  CANOE
 SG_ FD14_Point_Map_Height_37 : 352|2@1+ (1,0) [0|3] ""  CANOE
 SG_ FD14_Point_Map_Y_37 : 336|16@1- (1,0) [-32768|32767] ""  CANOE
 SG_ FD14_Point_Map_X_37 : 320|16@1- (1,0) [-32768|32767] ""  CANOE
 SG_ FD14_Point_Map_Age_36 : 304|8@1+ (1,0) [0|255] ""  CANOE
 SG_ FD14_Point_Map_Confidence_36 : 296|8@1+ (1,0) [0|255] ""  CANOE
 SG_ FD14_Point_Map_Height_36 : 288|2@1+ (1,0) [0|3] ""  CANOE
 SG_ FD14_Point_Map_Y_36 : 272|16@1- (1,0) [-32768|32767] ""  CANOE
 SG_ FD14_Point_Map_X_36 : 256|16@1- (1,0) [-32768|32767] ""  CANOE

BO_ 2654552200 Distance_Point_Map_5: 64 CVADAS
 SG_ FD14_Point_Map_Cruising_Age_47 : 482|6@1+ (1,0) [0|63] ""  CANOE
 SG_ FD14_Point_Map_Cruising_Age_46 : 418|6@1+ (1,0) [0|63] ""  CANOE
 SG_ FD14_Point_Map_Cruising_Age_45 : 354|6@1+ (1,0) [0|63] ""  CANOE
 SG_ FD14_Point_Map_Cruising_Age_44 : 290|6@1+ (1,0) [0|63] ""  CANOE
 SG_ FD14_Point_Map_Cruising_Age_43 : 226|6@1+ (1,0) [0|63] ""  CANOE
 SG_ FD14_Point_Map_Cruising_Age_42 : 162|6@1+ (1,0) [0|63] ""  CANOE
 SG_ FD14_Point_Map_Cruising_Age_41 : 98|6@1+ (1,0) [0|63] ""  CANOE
 SG_ FD14_Point_Map_Cruising_Age_40 : 34|6@1+ (1,0) [0|63] ""  CANOE
 SG_ FD14_Point_Map_Reserved_44 : 312|8@1+ (1,0) [0|255] ""  CANOE
 SG_ FD14_Point_Map_Age_44 : 304|8@1+ (1,0) [0|255] ""  CANOE
 SG_ FD14_Point_Map_Confidence_44 : 296|8@1+ (1,0) [0|255] ""  CANOE
 SG_ FD14_Point_Map_Height_44 : 288|2@1+ (1,0) [0|3] ""  CANOE
 SG_ FD14_Point_Map_Y_44 : 272|16@1- (1,0) [-32768|32767] ""  CANOE
 SG_ FD14_Point_Map_X_44 : 256|16@1- (1,0) [-32768|32767] ""  CANOE
 SG_ FD14_Point_Map_Reserved_43 : 248|8@1+ (1,0) [0|255] ""  CANOE
 SG_ FD14_Point_Map_Age_43 : 240|8@1+ (1,0) [0|255] ""  CANOE
 SG_ FD14_Point_Map_Confidence_43 : 232|8@1+ (1,0) [0|255] ""  CANOE
 SG_ FD14_Point_Map_Height_43 : 224|2@1+ (1,0) [0|3] ""  CANOE
 SG_ FD14_Point_Map_Y_43 : 208|16@1- (1,0) [-32768|32767] ""  CANOE
 SG_ FD14_Point_Map_X_43 : 192|16@1- (1,0) [-32768|32767] ""  CANOE
 SG_ FD14_Point_Map_Reserved_42 : 184|8@1+ (1,0) [0|255] ""  CANOE
 SG_ FD14_Point_Map_Age_42 : 176|8@1+ (1,0) [0|255] ""  CANOE
 SG_ FD14_Point_Map_Confidence_42 : 168|8@1+ (1,0) [0|255] ""  CANOE
 SG_ FD14_Point_Map_Height_42 : 160|2@1+ (1,0) [0|3] ""  CANOE
 SG_ FD14_Point_Map_Y_42 : 144|16@1- (1,0) [-32768|32767] ""  CANOE
 SG_ FD14_Point_Map_X_42 : 128|16@1- (1,0) [-32768|32767] ""  CANOE
 SG_ FD14_Point_Map_Reserved_41 : 120|8@1+ (1,0) [0|255] ""  CANOE
 SG_ FD14_Point_Map_Age_41 : 112|8@1+ (1,0) [0|255] ""  CANOE
 SG_ FD14_Point_Map_Confidence_41 : 104|8@1+ (1,0) [0|255] ""  CANOE
 SG_ FD14_Point_Map_Height_41 : 96|2@1+ (1,0) [0|3] ""  CANOE
 SG_ FD14_Point_Map_Y_41 : 80|16@1- (1,0) [-32768|32767] ""  CANOE
 SG_ FD14_Point_Map_X_41 : 64|16@1- (1,0) [-32768|32767] ""  CANOE
 SG_ FD14_Point_Map_Reserved_40 : 56|8@1+ (1,0) [0|255] ""  CANOE
 SG_ FD14_Point_Map_Age_40 : 48|8@1+ (1,0) [0|255] ""  CANOE
 SG_ FD14_Point_Map_Confidence_40 : 40|8@1+ (1,0) [0|255] ""  CANOE
 SG_ FD14_Point_Map_Height_40 : 32|2@1+ (1,0) [0|3] ""  CANOE
 SG_ FD14_Point_Map_Y_40 : 16|16@1- (1,0) [-32768|32767] ""  CANOE
 SG_ FD14_Point_Map_X_40 : 0|16@1- (1,0) [-32768|32767] ""  CANOE
 SG_ FD14_Point_Map_Reserved_47 : 504|8@1+ (1,0) [0|255] ""  CANOE
 SG_ FD14_Point_Map_Reserved_46 : 440|8@1+ (1,0) [0|255] ""  CANOE
 SG_ FD14_Point_Map_Reserved_45 : 376|8@1+ (1,0) [0|255] ""  CANOE
 SG_ FD14_Point_Map_Age_47 : 496|8@1+ (1,0) [0|255] ""  CANOE
 SG_ FD14_Point_Map_Confidence_47 : 488|8@1+ (1,0) [0|255] ""  CANOE
 SG_ FD14_Point_Map_Height_47 : 480|2@1+ (1,0) [0|3] ""  CANOE
 SG_ FD14_Point_Map_Y_47 : 464|16@1- (1,0) [-32768|32767] ""  CANOE
 SG_ FD14_Point_Map_X_47 : 448|16@1- (1,0) [-32768|32767] ""  CANOE
 SG_ FD14_Point_Map_Age_46 : 432|8@1+ (1,0) [0|255] ""  CANOE
 SG_ FD14_Point_Map_Confidence_46 : 424|8@1+ (1,0) [0|255] ""  CANOE
 SG_ FD14_Point_Map_Height_46 : 416|2@1+ (1,0) [0|3] ""  CANOE
 SG_ FD14_Point_Map_Y_46 : 400|16@1- (1,0) [-32768|32767] ""  CANOE
 SG_ FD14_Point_Map_X_46 : 384|16@1- (1,0) [-32768|32767] ""  CANOE
 SG_ FD14_Point_Map_Age_45 : 368|8@1+ (1,0) [0|255] ""  CANOE
 SG_ FD14_Point_Map_Confidence_45 : 360|8@1+ (1,0) [0|255] ""  CANOE
 SG_ FD14_Point_Map_Height_45 : 352|2@1+ (1,0) [0|3] ""  CANOE
 SG_ FD14_Point_Map_Y_45 : 336|16@1- (1,0) [-32768|32767] ""  CANOE
 SG_ FD14_Point_Map_X_45 : 320|16@1- (1,0) [-32768|32767] ""  CANOE

BO_ 2654552201 Distance_Point_Map_6: 64 CVADAS
 SG_ FD14_Point_Map_Cruising_Age_55 : 482|6@1+ (1,0) [0|63] ""  CANOE
 SG_ FD14_Point_Map_Cruising_Age_54 : 418|6@1+ (1,0) [0|63] ""  CANOE
 SG_ FD14_Point_Map_Cruising_Age_53 : 354|6@1+ (1,0) [0|63] ""  CANOE
 SG_ FD14_Point_Map_Cruising_Age_52 : 290|6@1+ (1,0) [0|63] ""  CANOE
 SG_ FD14_Point_Map_Cruising_Age_51 : 226|6@1+ (1,0) [0|63] ""  CANOE
 SG_ FD14_Point_Map_Cruising_Age_50 : 162|6@1+ (1,0) [0|63] ""  CANOE
 SG_ FD14_Point_Map_Cruising_Age_49 : 98|6@1+ (1,0) [0|63] ""  CANOE
 SG_ FD14_Point_Map_Cruising_Age_48 : 34|6@1+ (1,0) [0|63] ""  CANOE
 SG_ FD14_Point_Map_Reserved_53 : 376|8@1+ (1,0) [0|255] ""  CANOE
 SG_ FD14_Point_Map_Age_53 : 368|8@1+ (1,0) [0|255] ""  CANOE
 SG_ FD14_Point_Map_Confidence_53 : 360|8@1+ (1,0) [0|255] ""  CANOE
 SG_ FD14_Point_Map_Height_53 : 352|2@1+ (1,0) [0|3] ""  CANOE
 SG_ FD14_Point_Map_Y_53 : 336|16@1- (1,0) [-32768|32767] ""  CANOE
 SG_ FD14_Point_Map_X_53 : 320|16@1- (1,0) [-32768|32767] ""  CANOE
 SG_ FD14_Point_Map_Reserved_52 : 312|8@1+ (1,0) [0|255] ""  CANOE
 SG_ FD14_Point_Map_Age_52 : 304|8@1+ (1,0) [0|255] ""  CANOE
 SG_ FD14_Point_Map_Confidence_52 : 296|8@1+ (1,0) [0|255] ""  CANOE
 SG_ FD14_Point_Map_Height_52 : 288|2@1+ (1,0) [0|3] ""  CANOE
 SG_ FD14_Point_Map_Y_52 : 272|16@1- (1,0) [-32768|32767] ""  CANOE
 SG_ FD14_Point_Map_X_52 : 256|16@1- (1,0) [-32768|32767] ""  CANOE
 SG_ FD14_Point_Map_Reserved_51 : 248|8@1+ (1,0) [0|255] ""  CANOE
 SG_ FD14_Point_Map_Age_51 : 240|8@1+ (1,0) [0|255] ""  CANOE
 SG_ FD14_Point_Map_Confidence_51 : 232|8@1+ (1,0) [0|255] ""  CANOE
 SG_ FD14_Point_Map_Height_51 : 224|2@1+ (1,0) [0|3] ""  CANOE
 SG_ FD14_Point_Map_Y_51 : 208|16@1- (1,0) [-32768|32767] ""  CANOE
 SG_ FD14_Point_Map_X_51 : 192|16@1- (1,0) [-32768|32767] ""  CANOE
 SG_ FD14_Point_Map_Reserved_50 : 184|8@1+ (1,0) [0|255] ""  CANOE
 SG_ FD14_Point_Map_Age_50 : 176|8@1+ (1,0) [0|255] ""  CANOE
 SG_ FD14_Point_Map_Confidence_50 : 168|8@1+ (1,0) [0|255] ""  CANOE
 SG_ FD14_Point_Map_Height_50 : 160|2@1+ (1,0) [0|3] ""  CANOE
 SG_ FD14_Point_Map_Y_50 : 144|16@1- (1,0) [-32768|32767] ""  CANOE
 SG_ FD14_Point_Map_X_50 : 128|16@1- (1,0) [-32768|32767] ""  CANOE
 SG_ FD14_Point_Map_Reserved_49 : 120|8@1+ (1,0) [0|255] ""  CANOE
 SG_ FD14_Point_Map_Age_49 : 112|8@1+ (1,0) [0|255] ""  CANOE
 SG_ FD14_Point_Map_Confidence_49 : 104|8@1+ (1,0) [0|255] ""  CANOE
 SG_ FD14_Point_Map_Height_49 : 96|2@1+ (1,0) [0|3] ""  CANOE
 SG_ FD14_Point_Map_Y_49 : 80|16@1- (1,0) [-32768|32767] ""  CANOE
 SG_ FD14_Point_Map_X_49 : 64|16@1- (1,0) [-32768|32767] ""  CANOE
 SG_ FD14_Point_Map_Reserved_48 : 56|8@1+ (1,0) [0|255] ""  CANOE
 SG_ FD14_Point_Map_Age_48 : 48|8@1+ (1,0) [0|255] ""  CANOE
 SG_ FD14_Point_Map_Confidence_48 : 40|8@1+ (1,0) [0|255] ""  CANOE
 SG_ FD14_Point_Map_Height_48 : 32|2@1+ (1,0) [0|3] ""  CANOE
 SG_ FD14_Point_Map_Y_48 : 16|16@1- (1,0) [-32768|32767] ""  CANOE
 SG_ FD14_Point_Map_X_48 : 0|16@1- (1,0) [-32768|32767] ""  CANOE
 SG_ FD14_Point_Map_Reserved_54 : 440|8@1+ (1,0) [0|255] ""  CANOE
 SG_ FD14_Point_Map_Reserved_55 : 504|8@1+ (1,0) [0|255] ""  CANOE
 SG_ FD14_Point_Map_Confidence_55 : 488|8@1+ (1,0) [0|255] ""  CANOE
 SG_ FD14_Point_Map_Age_55 : 496|8@1+ (1,0) [0|255] ""  CANOE
 SG_ FD14_Point_Map_Height_55 : 480|2@1+ (1,0) [0|3] ""  CANOE
 SG_ FD14_Point_Map_Y_55 : 464|16@1- (1,0) [-32768|32767] ""  CANOE
 SG_ FD14_Point_Map_X_55 : 448|16@1- (1,0) [-32768|32767] ""  CANOE
 SG_ FD14_Point_Map_Age_54 : 432|8@1+ (1,0) [0|255] ""  CANOE
 SG_ FD14_Point_Map_Confidence_54 : 424|8@1+ (1,0) [0|255] ""  CANOE
 SG_ FD14_Point_Map_Height_54 : 416|2@1+ (1,0) [0|3] ""  CANOE
 SG_ FD14_Point_Map_Y_54 : 400|16@1- (1,0) [-32768|32767] ""  CANOE
 SG_ FD14_Point_Map_X_54 : 384|16@1- (1,0) [-32768|32767] ""  CANOE

BO_ 2654552208 Distance_Point_Map_7: 64 CVADAS
 SG_ FD14_Point_Map_Cruising_Age_63 : 482|6@1+ (1,0) [0|63] ""  CANOE
 SG_ FD14_Point_Map_Cruising_Age_62 : 418|6@1+ (1,0) [0|63] ""  CANOE
 SG_ FD14_Point_Map_Cruising_Age_61 : 354|6@1+ (1,0) [0|63] ""  CANOE
 SG_ FD14_Point_Map_Cruising_Age_60 : 290|6@1+ (1,0) [0|63] ""  CANOE
 SG_ FD14_Point_Map_Cruising_Age_59 : 226|6@1+ (1,0) [0|63] ""  CANOE
 SG_ FD14_Point_Map_Cruising_Age_58 : 162|6@1+ (1,0) [0|63] ""  CANOE
 SG_ FD14_Point_Map_Cruising_Age_57 : 98|6@1+ (1,0) [0|63] ""  CANOE
 SG_ FD14_Point_Map_Cruising_Age_56 : 34|6@1+ (1,0) [0|63] ""  CANOE
 SG_ FD14_Point_Map_Reserved_62 : 440|8@1+ (1,0) [0|255] ""  CANOE
 SG_ FD14_Point_Map_Age_62 : 432|8@1+ (1,0) [0|255] ""  CANOE
 SG_ FD14_Point_Map_Confidence_62 : 424|8@1+ (1,0) [0|255] ""  CANOE
 SG_ FD14_Point_Map_Height_62 : 416|2@1+ (1,0) [0|3] ""  CANOE
 SG_ FD14_Point_Map_Y_62 : 400|16@1- (1,0) [-32768|32767] ""  CANOE
 SG_ FD14_Point_Map_X_62 : 384|16@1- (1,0) [-32768|32767] ""  CANOE
 SG_ FD14_Point_Map_Reserved_61 : 376|8@1+ (1,0) [0|255] ""  CANOE
 SG_ FD14_Point_Map_Age_61 : 368|8@1+ (1,0) [0|255] ""  CANOE
 SG_ FD14_Point_Map_Confidence_61 : 360|8@1+ (1,0) [0|255] ""  CANOE
 SG_ FD14_Point_Map_Height_61 : 352|2@1+ (1,0) [0|3] ""  CANOE
 SG_ FD14_Point_Map_Y_61 : 336|16@1- (1,0) [-32768|32767] ""  CANOE
 SG_ FD14_Point_Map_X_61 : 320|16@1- (1,0) [-32768|32767] ""  CANOE
 SG_ FD14_Point_Map_Reserved_60 : 312|8@1+ (1,0) [0|255] ""  CANOE
 SG_ FD14_Point_Map_Confidence_60 : 296|8@1+ (1,0) [0|255] ""  CANOE
 SG_ FD14_Point_Map_Height_60 : 288|2@1+ (1,0) [0|3] ""  CANOE
 SG_ FD14_Point_Map_Age_60 : 304|8@1+ (1,0) [0|255] ""  CANOE
 SG_ FD14_Point_Map_Y_60 : 272|16@1- (1,0) [-32768|32767] ""  CANOE
 SG_ FD14_Point_Map_X_60 : 256|16@1- (1,0) [-32768|32767] ""  CANOE
 SG_ FD14_Point_Map_Reserved_59 : 248|8@1+ (1,0) [0|255] ""  CANOE
 SG_ FD14_Point_Map_Age_59 : 240|8@1+ (1,0) [0|255] ""  CANOE
 SG_ FD14_Point_Map_Confidence_59 : 232|8@1+ (1,0) [0|255] ""  CANOE
 SG_ FD14_Point_Map_Height_59 : 224|2@1+ (1,0) [0|3] ""  CANOE
 SG_ FD14_Point_Map_Y_59 : 208|16@1- (1,0) [-32768|32767] ""  CANOE
 SG_ FD14_Point_Map_X_59 : 192|16@1- (1,0) [-32768|32767] ""  CANOE
 SG_ FD14_Point_Map_Reserved_58 : 184|8@1+ (1,0) [0|255] ""  CANOE
 SG_ FD14_Point_Map_Age_58 : 176|8@1+ (1,0) [0|255] ""  CANOE
 SG_ FD14_Point_Map_Confidence_58 : 168|8@1+ (1,0) [0|255] ""  CANOE
 SG_ FD14_Point_Map_Height_58 : 160|2@1+ (1,0) [0|3] ""  CANOE
 SG_ FD14_Point_Map_Y_58 : 144|16@1- (1,0) [-32768|32767] ""  CANOE
 SG_ FD14_Point_Map_X_58 : 128|16@1- (1,0) [-32768|32767] ""  CANOE
 SG_ FD14_Point_Map_Reserved_57 : 120|8@1+ (1,0) [0|255] ""  CANOE
 SG_ FD14_Point_Map_Age_57 : 112|8@1+ (1,0) [0|255] ""  CANOE
 SG_ FD14_Point_Map_Confidence_57 : 104|8@1+ (1,0) [0|255] ""  CANOE
 SG_ FD14_Point_Map_Height_57 : 96|2@1+ (1,0) [0|3] ""  CANOE
 SG_ FD14_Point_Map_Y_57 : 80|16@1- (1,0) [-32768|32767] ""  CANOE
 SG_ FD14_Point_Map_X_57 : 64|16@1- (1,0) [-32768|32767] ""  CANOE
 SG_ FD14_Point_Map_Reserved_56 : 56|8@1+ (1,0) [0|255] ""  CANOE
 SG_ FD14_Point_Map_Age_56 : 48|8@1+ (1,0) [0|255] ""  CANOE
 SG_ FD14_Point_Map_Confidence_56 : 40|8@1+ (1,0) [0|255] ""  CANOE
 SG_ FD14_Point_Map_Height_56 : 32|2@1+ (1,0) [0|3] ""  CANOE
 SG_ FD14_Point_Map_Y_56 : 16|16@1- (1,0) [-32768|32767] ""  CANOE
 SG_ FD14_Point_Map_X_56 : 0|16@1- (1,0) [-32768|32767] ""  CANOE
 SG_ FD14_Point_Map_Reserved_63 : 504|8@1+ (1,0) [0|255] ""  CANOE
 SG_ FD14_Point_Map_Age_63 : 496|8@1+ (1,0) [0|255] ""  CANOE
 SG_ FD14_Point_Map_Confidence_63 : 488|8@1+ (1,0) [0|255] ""  CANOE
 SG_ FD14_Point_Map_Height_63 : 480|2@1+ (1,0) [0|3] ""  CANOE
 SG_ FD14_Point_Map_Y_63 : 464|16@1- (1,0) [-32768|32767] ""  CANOE
 SG_ FD14_Point_Map_X_63 : 448|16@1- (1,0) [-32768|32767] ""  CANOE

CM_ "Project_DT24_ProjectStandard_FD-CAN14 [CS00155_FD]";
BA_DEF_ SG_  "GenSigStartValue" INT 0 2147483647;
BA_DEF_ SG_  "GenSigInactiveValue" INT 0 2147483647;
BA_DEF_ SG_  "GenSigSendType" ENUM  "NotUsed","OnWrite","OnWriteWithRepetition","OnChange","OnChangeWithRepetition","IfActive","IfActiveWithRepetition","NoSigSendType";
BA_DEF_ SG_  "GenSigTimeoutTime_BSM" INT 0 65535;
BA_DEF_ SG_  "GenSigTimeoutTime_BSM2" INT 0 65535;
BA_DEF_ SG_  "GenSigTimeoutTime_CADM" INT 0 65535;
BA_DEF_ SG_  "GenSigTimeoutTime_CVADAS" INT 0 65535;
BA_DEF_ SG_  "GenSigTimeoutTime_ECM" INT 0 65535;
BA_DEF_ SG_  "GenSigTimeoutTime_EPS" INT 0 65535;
BA_DEF_ SG_  "GenSigTimeoutTime_EVCU2" INT 0 65535;
BA_DEF_ SG_  "GenSigTimeoutTime_ORC" INT 0 65535;
BA_DEF_ BO_  "DiagRequest" ENUM  "No","Yes";
BA_DEF_ BO_  "Type" ENUM  "P","C","PE","COC","PE_Cntrl","E","E_Cntrl","OC","S","BAF","DC","EM","MM","ISO-TP","-";
BA_DEF_ BO_  "DiagResponse" ENUM  "No","Yes";
BA_DEF_ BO_  "NmMessage" ENUM  "No","Yes";
BA_DEF_ BO_  "GenMsgSendType" ENUM  "Cyclic","NotUsed","NotUsed","NotUsed","NotUsed","NotUsed","NotUsed","NotUsed","NoMsgSendType";
BA_DEF_ BO_  "GenMsgNrOfRepetition" INT 0 255;
BA_DEF_ BO_  "GenMsgILSupport" ENUM  "No","Yes";
BA_DEF_ BO_  "GenMsgCycleTimeFast" INT 0 65535;
BA_DEF_ BO_  "GenMsgCycleTime" INT 0 65535;
BA_DEF_ BO_  "GenMsgDelayTime" INT 0 65535;
BA_DEF_ BO_  "NmAsrMessage" ENUM  "No","Yes";
BA_DEF_ BO_  "DiagState" ENUM  "No","Yes";
BA_DEF_ BO_  "DiagConnection" HEX 0 65535;
BA_DEF_ BO_  "VFrameFormat" ENUM  "StandardCAN","ExtendedCAN","reserved","reserved","reserved","reserved","reserved","reserved","reserved","reserved","reserved","reserved","reserved","reserved","StandardCAN_FD","ExtendedCAN_FD";
BA_DEF_ BO_  "CANFD_BRS" ENUM  "No","Yes";
BA_DEF_  "Manufacturer" STRING ;
BA_DEF_  "NmType" STRING ;
BA_DEF_  "BusType" STRING ;
BA_DEF_  "Baudrate" INT 0 1000000;
BA_DEF_  "DBName" STRING ;
BA_DEF_  "NmAsrTimeoutTime" INT 1 65535;
BA_DEF_  "NmAsrWaitBusSleepTime" INT 1 65535;
BA_DEF_  "NmAsrRepeatMessageTime" INT 1 65535;
BA_DEF_  "NmAsrMessageCount" INT 1 256;
BA_DEF_  "NmAsrBaseAddress" HEX 235487232 2147483647;
BA_DEF_  "NmAsrCanMsgCycleTime" INT 1 65535;
BA_DEF_  "Version" HEX 0 255;
BA_DEF_  "VersionWeek" INT 0 53;
BA_DEF_  "VersionYear" INT 0 99;
BA_DEF_ BU_  "Description" STRING ;
BA_DEF_ BU_  "NmStationAddress" HEX 0 255;
BA_DEF_ BU_  "NmNode" ENUM  "No","Yes";
BA_DEF_ BU_  "NmAsrNode" ENUM  "No","Yes";
BA_DEF_ BU_  "NmAsrNodeIdentifier" HEX 0 255;
BA_DEF_ BU_  "NmAsrCanMsgReducedTime" INT 1 65535;
BA_DEF_ BU_  "NmNodeType" ENUM  "+15_NotWakeable","+30_Wakeable","+30_NotWakeable","kMaster","kSlave15","kSlave30","none";
BA_DEF_ BU_  "NwmNodeType" ENUM  "+15_NotWakeable","+30_Wakeable","+30_NotWakeable","kMaster","kSlave15","kSlave30","none";
BA_DEF_ SG_  "SystemSignalLongSymbol" STRING ;
BA_DEF_DEF_  "GenSigStartValue" 0;
BA_DEF_DEF_  "GenSigInactiveValue" 0;
BA_DEF_DEF_  "GenSigSendType" "NoSigSendType";
BA_DEF_DEF_  "GenSigTimeoutTime_BSM" 2500;
BA_DEF_DEF_  "GenSigTimeoutTime_BSM2" 2500;
BA_DEF_DEF_  "GenSigTimeoutTime_CADM" 2500;
BA_DEF_DEF_  "GenSigTimeoutTime_CVADAS" 2500;
BA_DEF_DEF_  "GenSigTimeoutTime_ECM" 2500;
BA_DEF_DEF_  "GenSigTimeoutTime_EPS" 2500;
BA_DEF_DEF_  "GenSigTimeoutTime_EVCU2" 2500;
BA_DEF_DEF_  "GenSigTimeoutTime_ORC" 2500;
BA_DEF_DEF_  "DiagRequest" "No";
BA_DEF_DEF_  "Type" "-";
BA_DEF_DEF_  "DiagResponse" "No";
BA_DEF_DEF_  "NmMessage" "No";
BA_DEF_DEF_  "GenMsgSendType" "NoMsgSendType";
BA_DEF_DEF_  "GenMsgNrOfRepetition" 0;
BA_DEF_DEF_  "GenMsgILSupport" "No";
BA_DEF_DEF_  "GenMsgCycleTimeFast" 0;
BA_DEF_DEF_  "GenMsgCycleTime" 0;
BA_DEF_DEF_  "GenMsgDelayTime" 0;
BA_DEF_DEF_  "NmAsrMessage" "No";
BA_DEF_DEF_  "DiagState" "No";
BA_DEF_DEF_  "DiagConnection" 0;
BA_DEF_DEF_  "VFrameFormat" "StandardCAN_FD";
BA_DEF_DEF_  "CANFD_BRS" "No";
BA_DEF_DEF_  "Manufacturer" "Fiat";
BA_DEF_DEF_  "NmType" "";
BA_DEF_DEF_  "BusType" "CAN";
BA_DEF_DEF_  "Baudrate" 500000;
BA_DEF_DEF_  "DBName" "CAN";
BA_DEF_DEF_  "NmAsrTimeoutTime" 1000;
BA_DEF_DEF_  "NmAsrWaitBusSleepTime" 750;
BA_DEF_DEF_  "NmAsrRepeatMessageTime" 800;
BA_DEF_DEF_  "NmAsrMessageCount" 256;
BA_DEF_DEF_  "NmAsrBaseAddress" 506724352;
BA_DEF_DEF_  "NmAsrCanMsgCycleTime" 200;
BA_DEF_DEF_  "Version" 160;
BA_DEF_DEF_  "VersionWeek" 45;
BA_DEF_DEF_  "VersionYear" 22;
BA_DEF_DEF_  "Description" "";
BA_DEF_DEF_  "NmStationAddress" 0;
BA_DEF_DEF_  "NmNode" "Yes";
BA_DEF_DEF_  "NmAsrNode" "Yes";
BA_DEF_DEF_  "NmAsrNodeIdentifier" 0;
BA_DEF_DEF_  "NmAsrCanMsgReducedTime" 100;
BA_DEF_DEF_  "NmNodeType" "none";
BA_DEF_DEF_  "NwmNodeType" "none";
BA_DEF_DEF_  "SystemSignalLongSymbol" "";
BA_ "NmType" "NmAsr";
BA_ "BusType" "CAN FD";
BA_ "NmAsrTimeoutTime" 8000;
BA_ "NmAsrWaitBusSleepTime" 1000;
BA_ "NmAsrRepeatMessageTime" 5000;
BA_ "NmAsrBaseAddress" 507002880;
BA_ "NmAsrCanMsgCycleTime" 1000;
BA_ "DBName" "FDCAN14";
BA_ "Description" BU_ BSM "Braking System Module";
BA_ "NmStationAddress" BU_ BSM 6;
BA_ "NmAsrNodeIdentifier" BU_ BSM 6;
BA_ "NmAsrCanMsgReducedTime" BU_ BSM 525;
BA_ "NmNodeType" BU_ BSM 2;
BA_ "NwmNodeType" BU_ BSM 2;
BA_ "Description" BU_ BSM2 "Brake System Module 2";
BA_ "NmStationAddress" BU_ BSM2 148;
BA_ "NmAsrNodeIdentifier" BU_ BSM2 148;
BA_ "NmAsrCanMsgReducedTime" BU_ BSM2 625;
BA_ "NmNodeType" BU_ BSM2 2;
BA_ "NwmNodeType" BU_ BSM2 2;
BA_ "Description" BU_ CADM "Central ADAS Decision Module";
BA_ "NmStationAddress" BU_ CADM 141;
BA_ "NmAsrNodeIdentifier" BU_ CADM 141;
BA_ "NmAsrCanMsgReducedTime" BU_ CADM 650;
BA_ "NmNodeType" BU_ CADM 2;
BA_ "NwmNodeType" BU_ CADM 2;
BA_ "Description" BU_ CVADAS "Central Vision ADAS";
BA_ "NmStationAddress" BU_ CVADAS 24;
BA_ "NmAsrNodeIdentifier" BU_ CVADAS 24;
BA_ "NmAsrCanMsgReducedTime" BU_ CVADAS 675;
BA_ "NmNodeType" BU_ CVADAS 2;
BA_ "NwmNodeType" BU_ CVADAS 2;
BA_ "Description" BU_ ECM "Engine Control Module";
BA_ "NmStationAddress" BU_ ECM 1;
BA_ "NmAsrNodeIdentifier" BU_ ECM 1;
BA_ "NmAsrCanMsgReducedTime" BU_ ECM 575;
BA_ "NmNodeType" BU_ ECM 2;
BA_ "NwmNodeType" BU_ ECM 2;
BA_ "Description" BU_ EPS "Electric Power Steering";
BA_ "NmStationAddress" BU_ EPS 2;
BA_ "NmAsrNodeIdentifier" BU_ EPS 2;
BA_ "NmAsrCanMsgReducedTime" BU_ EPS 600;
BA_ "NmNodeType" BU_ EPS 2;
BA_ "NwmNodeType" BU_ EPS 2;
BA_ "Description" BU_ ORC "Occupant Restraint Control";
BA_ "NmStationAddress" BU_ ORC 26;
BA_ "NmAsrNodeIdentifier" BU_ ORC 26;
BA_ "NmAsrCanMsgReducedTime" BU_ ORC 925;
BA_ "NmNodeType" BU_ ORC 2;
BA_ "NwmNodeType" BU_ ORC 2;
BA_ "NwmNodeType" BU_ EVCU2 2;
BA_ "NmNodeType" BU_ EVCU2 2;
BA_ "NmAsrCanMsgReducedTime" BU_ EVCU2 950;
BA_ "NmAsrNodeIdentifier" BU_ EVCU2 64;
BA_ "NmStationAddress" BU_ EVCU2 64;
BA_ "Description" BU_ EVCU2 "Electric Vehicle Control Unit 2";
BA_ "CANFD_BRS" BO_ 2654556161 1;
BA_ "GenMsgILSupport" BO_ 2654556161 1;
BA_ "VFrameFormat" BO_ 2654556161 15;
BA_ "GenMsgILSupport" BO_ 2654814279 1;
BA_ "CANFD_BRS" BO_ 2654814279 1;
BA_ "VFrameFormat" BO_ 2654814279 15;
BA_ "CANFD_BRS" BO_ 2654552135 1;
BA_ "GenMsgCycleTime" BO_ 2654552135 40;
BA_ "GenMsgILSupport" BO_ 2654552135 1;
BA_ "GenMsgSendType" BO_ 2654552135 0;
BA_ "VFrameFormat" BO_ 2654552135 15;
BA_ "GenMsgCycleTime" BO_ 2654552136 40;
BA_ "GenMsgILSupport" BO_ 2654552136 1;
BA_ "GenMsgSendType" BO_ 2654552136 0;
BA_ "VFrameFormat" BO_ 2654552136 1;
BA_ "GenMsgILSupport" BO_ 2654814208 1;
BA_ "VFrameFormat" BO_ 2654814208 1;
BA_ "CANFD_BRS" BO_ 2654552169 1;
BA_ "GenMsgILSupport" BO_ 2654552169 1;
BA_ "VFrameFormat" BO_ 2654552169 15;
BA_ "CANFD_BRS" BO_ 2654552217 1;
BA_ "GenMsgILSupport" BO_ 2654552217 1;
BA_ "VFrameFormat" BO_ 2654552217 15;
BA_ "CANFD_BRS" BO_ 2654552163 1;
BA_ "GenMsgILSupport" BO_ 2654552163 1;
BA_ "VFrameFormat" BO_ 2654552163 15;
BA_ "CANFD_BRS" BO_ 2654552152 1;
BA_ "GenMsgILSupport" BO_ 2654552152 1;
BA_ "VFrameFormat" BO_ 2654552152 15;
BA_ "CANFD_BRS" BO_ 2654552164 1;
BA_ "GenMsgILSupport" BO_ 2654552164 1;
BA_ "VFrameFormat" BO_ 2654552164 15;
BA_ "CANFD_BRS" BO_ 2654552216 1;
BA_ "GenMsgILSupport" BO_ 2654552216 1;
BA_ "VFrameFormat" BO_ 2654552216 15;
BA_ "CANFD_BRS" BO_ 2654552162 1;
BA_ "GenMsgILSupport" BO_ 2654552162 1;
BA_ "VFrameFormat" BO_ 2654552162 15;
BA_ "CANFD_BRS" BO_ 2654552178 1;
BA_ "GenMsgILSupport" BO_ 2654552178 1;
BA_ "VFrameFormat" BO_ 2654552178 15;
BA_ "CANFD_BRS" BO_ 2654552149 1;
BA_ "GenMsgILSupport" BO_ 2654552149 1;
BA_ "VFrameFormat" BO_ 2654552149 15;
BA_ "CANFD_BRS" BO_ 2654552150 1;
BA_ "GenMsgILSupport" BO_ 2654552150 1;
BA_ "VFrameFormat" BO_ 2654552150 15;
BA_ "CANFD_BRS" BO_ 2654552148 1;
BA_ "GenMsgILSupport" BO_ 2654552148 1;
BA_ "VFrameFormat" BO_ 2654552148 15;
BA_ "CANFD_BRS" BO_ 2654552320 1;
BA_ "GenMsgILSupport" BO_ 2654552320 1;
BA_ "VFrameFormat" BO_ 2654552320 15;
BA_ "CANFD_BRS" BO_ 2654552176 1;
BA_ "GenMsgILSupport" BO_ 2654552176 1;
BA_ "VFrameFormat" BO_ 2654552176 15;
BA_ "CANFD_BRS" BO_ 2654552177 1;
BA_ "GenMsgILSupport" BO_ 2654552177 1;
BA_ "VFrameFormat" BO_ 2654552177 15;
BA_ "CANFD_BRS" BO_ 2654552160 1;
BA_ "GenMsgILSupport" BO_ 2654552160 1;
BA_ "VFrameFormat" BO_ 2654552160 15;
BA_ "CANFD_BRS" BO_ 2654552153 1;
BA_ "GenMsgILSupport" BO_ 2654552153 1;
BA_ "VFrameFormat" BO_ 2654552153 15;
BA_ "CANFD_BRS" BO_ 2654552161 1;
BA_ "GenMsgILSupport" BO_ 2654552161 1;
BA_ "VFrameFormat" BO_ 2654552161 15;
BA_ "CANFD_BRS" BO_ 2654552194 1;
BA_ "GenMsgILSupport" BO_ 2654552194 1;
BA_ "VFrameFormat" BO_ 2654552194 15;
BA_ "CANFD_BRS" BO_ 2654814232 1;
BA_ "GenMsgILSupport" BO_ 2654814232 1;
BA_ "VFrameFormat" BO_ 2654814232 15;
BA_ "CANFD_BRS" BO_ 2654814209 1;
BA_ "GenMsgILSupport" BO_ 2654814209 1;
BA_ "VFrameFormat" BO_ 2654814209 15;
BA_ "CANFD_BRS" BO_ 2654552195 1;
BA_ "GenMsgILSupport" BO_ 2654552195 1;
BA_ "VFrameFormat" BO_ 2654552195 15;
BA_ "CANFD_BRS" BO_ 2654552196 1;
BA_ "GenMsgILSupport" BO_ 2654552196 1;
BA_ "VFrameFormat" BO_ 2654552196 15;
BA_ "CANFD_BRS" BO_ 2654552197 1;
BA_ "GenMsgILSupport" BO_ 2654552197 1;
BA_ "VFrameFormat" BO_ 2654552197 15;
BA_ "CANFD_BRS" BO_ 2654552198 1;
BA_ "GenMsgILSupport" BO_ 2654552198 1;
BA_ "VFrameFormat" BO_ 2654552198 15;
BA_ "CANFD_BRS" BO_ 2654552199 1;
BA_ "GenMsgILSupport" BO_ 2654552199 1;
BA_ "VFrameFormat" BO_ 2654552199 15;
BA_ "CANFD_BRS" BO_ 2654552200 1;
BA_ "GenMsgILSupport" BO_ 2654552200 1;
BA_ "VFrameFormat" BO_ 2654552200 15;
BA_ "CANFD_BRS" BO_ 2654552201 1;
BA_ "GenMsgILSupport" BO_ 2654552201 1;
BA_ "VFrameFormat" BO_ 2654552201 15;
BA_ "CANFD_BRS" BO_ 2654552208 1;
BA_ "GenMsgILSupport" BO_ 2654552208 1;
BA_ "VFrameFormat" BO_ 2654552208 15;
BA_ "GenSigSendType" SG_ 2654556161 FD14_1_Hook_PresentPtr_MCU1_0 1;
BA_ "GenSigSendType" SG_ 2654556161 FD14_1_ErrFaultInfo_MCU2_0 1;
BA_ "GenSigSendType" SG_ 2654556161 FD14_1_Err_FaultInfo_MCU2_1 1;
BA_ "GenSigSendType" SG_ 2654556161 FD14_1_Err_FaultInfo_MPU1_0 1;
BA_ "GenSigSendType" SG_ 2654556161 FD14_1_Err_FaultInfo_MCU1_0 1;
BA_ "GenSigSendType" SG_ 2654556161 FD14_1_WDG_Error_ID_MCU1_0 1;
BA_ "GenSigSendType" SG_ 2654556161 FD14_1_SDL_Fault_MCU1_0 1;
BA_ "GenSigSendType" SG_ 2654556161 FD14_1_Hook_Service_MCU1_0 1;
BA_ "GenSigSendType" SG_ 2654556161 FD14_1_Hook_DtErr_MCU1_0 1;
BA_ "GenSigSendType" SG_ 2654556161 FD14_1_Hook_Reserved_MCU1_0 1;
BA_ "GenSigSendType" SG_ 2654556161 FD14_1_Hook_fatalErr_MCU1_0 1;
BA_ "GenSigSendType" SG_ 2654556161 FD14_1_Hook_actTsk_MCU1_0 1;
BA_ "GenSigSendType" SG_ 2654556161 FD14_1_Hook_Error_MCU1_0 1;
BA_ "GenSigSendType" SG_ 2654556161 FD14_1_Hook_Type_MCU1_0 1;
BA_ "GenSigSendType" SG_ 2654556161 FD14_1_SSM_FltData1_MCU1_0 1;
BA_ "GenSigSendType" SG_ 2654556161 FD14_1_SSM_FltData2_MCU1_0 1;
BA_ "GenSigSendType" SG_ 2654556161 FD14_1_SSM_FltData3_MCU1_0 1;
BA_ "GenSigSendType" SG_ 2654556161 FD14_1_SSM_FltData4_MCU1_0 1;
BA_ "GenSigSendType" SG_ 2654556161 FD14_1_SSM_FltData5_MCU1_0 1;
BA_ "GenSigSendType" SG_ 2654556161 FD14_1_SSM_FltData6_MCU1_0 1;
BA_ "GenSigSendType" SG_ 2654556161 FD14_1_SSM_FltData7_MCU1_0 1;
BA_ "GenSigSendType" SG_ 2654556161 FD14_1_SSM_FltData8_MCU1_0 1;
BA_ "GenSigSendType" SG_ 2654556161 FD14_1_SSM_FltData9_MCU1_0 1;
BA_ "GenSigSendType" SG_ 2654556161 FD14_1_SSM_FltData10_MCU1_0 1;
BA_ "GenSigSendType" SG_ 2654556161 FD14_1_SSM_FltData11_MCU1_0 1;
BA_ "GenSigSendType" SG_ 2654556161 FD14_1_SSM_FltData12_MCU1_0 1;
BA_ "GenSigSendType" SG_ 2654556161 FD14_1_SSM_FltData13_MCU1_0 1;
BA_ "GenSigSendType" SG_ 2654556161 FD14_1_SSM_FltData14_MCU1_0 1;
BA_ "GenSigSendType" SG_ 2654556161 FD14_1_SSM_FltData15_MCU1_0 1;
BA_ "GenSigSendType" SG_ 2654556161 FD14_1_SSM_FltData16_MCU1_0 1;
BA_ "GenSigSendType" SG_ 2654556161 FD14_1_SSM_FltData17_MCU1_0 1;
BA_ "GenSigSendType" SG_ 2654556161 FD14_1_SSM_FltData18_MCU1_0 1;
BA_ "GenSigSendType" SG_ 2654556161 FD14_1_Err_FaultNum_MCU2_0 1;
BA_ "GenSigSendType" SG_ 2654556161 FD14_1_Err_FaultNum_MCU2_1 1;
BA_ "GenSigSendType" SG_ 2654556161 FD14_1_Err_FaultNum_MPU1_0 1;
BA_ "GenSigSendType" SG_ 2654556161 FD14_1_Err_FaultNum_MCU1_0 1;
BA_ "GenSigSendType" SG_ 2654556161 FD14_1_Reserved_MCU2_0 1;
BA_ "GenSigSendType" SG_ 2654556161 FD14_1_Reserved_MCU2_1 1;
BA_ "GenSigSendType" SG_ 2654556161 FD14_1_Reserved_MPU1_0 1;
BA_ "GenSigSendType" SG_ 2654556161 FD14_1_Reserved_MCU1_0 1;
BA_ "GenSigStartValue" SG_ 2654814279 FD14_CsmStateCurrent 15;
BA_ "GenSigSendType" SG_ 2654814279 FD14_CsmStateCurrent 1;
BA_ "GenSigStartValue" SG_ 2654814279 FD14_CsmStatePrevious 15;
BA_ "GenSigSendType" SG_ 2654814279 FD14_CsmStatePrevious 1;
BA_ "GenSigStartValue" SG_ 2654814279 FD14_CsmLocalModuleId 15;
BA_ "GenSigSendType" SG_ 2654814279 FD14_CsmLocalModuleId 1;
BA_ "GenSigSendType" SG_ 2654814279 FD14_CsmLocalModuleInstanceId 1;
BA_ "GenSigSendType" SG_ 2654814279 FD14_CsmLocalErrOrEventId 1;
BA_ "GenSigSendType" SG_ 2654814279 FD14_CsmLocalErrOrEventState 1;
BA_ "GenSigStartValue" SG_ 2654814279 FD14_CsmLocalErrOrEventState 7;
BA_ "GenSigSendType" SG_ 2654552135 FD14_RawPntDebugSignal 1;
BA_ "GenSigSendType" SG_ 2654552136 FD14_UssParkingModeSignal 1;
BA_ "GenSigSendType" SG_ 2654814208 FD14_BOR_Blockage 1;
BA_ "GenSigSendType" SG_ 2654814208 FD14_AOR_Blockage 1;
BA_ "GenSigSendType" SG_ 2654814208 FD14_BOL_Blockage 1;
BA_ "GenSigSendType" SG_ 2654814208 FD14_AOL_Blockage 1;
BA_ "GenSigSendType" SG_ 2654814208 FD14_RSL_Blockage 1;
BA_ "GenSigSendType" SG_ 2654814208 FD14_ROL_Blockage 1;
BA_ "GenSigSendType" SG_ 2654814208 FD14_RIL_Blockage 1;
BA_ "GenSigSendType" SG_ 2654814208 FD14_RIR_Blockage 1;
BA_ "GenSigSendType" SG_ 2654814208 FD14_ROR_Blockage 1;
BA_ "GenSigSendType" SG_ 2654814208 FD14_RSR_Blockage 1;
BA_ "GenSigSendType" SG_ 2654814208 FD14_FSL_Blockage 1;
BA_ "GenSigSendType" SG_ 2654814208 FD14_FOL_Blockage 1;
BA_ "GenSigSendType" SG_ 2654814208 FD14_FIL_Blockage 1;
BA_ "GenSigSendType" SG_ 2654814208 FD14_FIR_Blockage 1;
BA_ "GenSigSendType" SG_ 2654814208 FD14_FOR_Blockage 1;
BA_ "GenSigSendType" SG_ 2654814208 FD14_FSR_Blockage 1;
BA_ "GenSigSendType" SG_ 2654552169 FD14_IeAutoPark_e_AlgoState 1;
BA_ "GenSigSendType" SG_ 2654552169 FD14_IeAP_e_AutoParkStatus 1;
BA_ "GenSigSendType" SG_ 2654552169 FD14_MeAP_e_ParkAssistStatus 1;
BA_ "GenSigSendType" SG_ 2654552169 FD14_MeAP_e_Park_state 1;
BA_ "GenSigSendType" SG_ 2654552169 FD14_MeAP_a_ThrtlCmd 1;
BA_ "GenSigSendType" SG_ 2654552169 FD14_MeAP_a_BrkCmd 1;
BA_ "GenSigSendType" SG_ 2654552169 FD14_MeAP_deg_StrCmd 1;
BA_ "GenSigSendType" SG_ 2654552169 FD14_MeAP_b_PPPADisable 1;
BA_ "GenSigSendType" SG_ 2654552169 FD14_MeAP_b_PPPADefEng 1;
BA_ "GenSigSendType" SG_ 2654552169 FD14_MeAP_b_PPPAActv4LOW 1;
BA_ "GenSigSendType" SG_ 2654552169 FD14_MeAP_b_PPPAActvTrlr 1;
BA_ "GenSigSendType" SG_ 2654552169 FD14_MeAP_b_PARBDisable 1;
BA_ "GenSigSendType" SG_ 2654552169 FD14_MeAP_b_PARBActv4LOW 1;
BA_ "GenSigSendType" SG_ 2654552169 FD14_MeAP_b_PARBActvTrlr 1;
BA_ "GenSigSendType" SG_ 2654552169 FD14_MeAP_b_RPAVolDefMed 1;
BA_ "GenSigSendType" SG_ 2654552169 FD14_MeAP_b_FPAVolDefMed 1;
BA_ "GenSigSendType" SG_ 2654552169 FD14_MeAP_b_PAVolDefMed 1;
BA_ "GenSigSendType" SG_ 2654552169 FD14_MeAP_b_RPAActvTrlr 1;
BA_ "GenSigSendType" SG_ 2654552169 FD14_MeAP_b_RPADisable 1;
BA_ "GenSigSendType" SG_ 2654552169 FD14_MeAP_b_FPADisable 1;
BA_ "GenSigSendType" SG_ 2654552169 FD14_MeAP_b_FeatureEnbl 1;
BA_ "GenSigSendType" SG_ 2654552169 FD14_MeAP_b_VehCndSts 1;
BA_ "GenSigSendType" SG_ 2654552169 FD14_IeAP_b_MnvPosOk 1;
BA_ "GenSigSendType" SG_ 2654552169 FD14_MeAP_b_SteerActionReq 1;
BA_ "GenSigSendType" SG_ 2654552169 FD14_MeAP_b_PosMet 1;
BA_ "GenSigSendType" SG_ 2654552169 FD14_MeAP_b_ManeuverSuccess 1;
BA_ "GenSigSendType" SG_ 2654552169 FD14_MeAP_b_ManeuverAbort 1;
BA_ "GenSigSendType" SG_ 2654552169 FD14_MeAP_b_BSMHandshakeActv 1;
BA_ "GenSigSendType" SG_ 2654552169 FD14_MeAP_b_StandStill 1;
BA_ "GenSigSendType" SG_ 2654552169 FD14_MeAP_b_DriverOverride 1;
BA_ "GenSigSendType" SG_ 2654552169 FD14_MeAP_b_APInitSts 1;
BA_ "GenSigSendType" SG_ 2654552169 FD14_MeAP_b_SeekSpdExceedTimeout 1;
BA_ "GenSigSendType" SG_ 2654552169 FD14_MeAP_b_PausedPressBtnTimeou 1;
BA_ "SystemSignalLongSymbol" SG_ 2654552169 FD14_MeAP_b_PausedPressBtnTimeou "FD14_MeAP_b_PausedPressBtnTimeout";
BA_ "GenSigSendType" SG_ 2654552169 FD14_MeAP_b_ObjInPathTimeout 1;
BA_ "GenSigSendType" SG_ 2654552169 FD14_MeAP_b_CamHandshakeTimeout 1;
BA_ "GenSigSendType" SG_ 2654552169 FD14_MeAP_b_GearShiftWaitTimeout 1;
BA_ "GenSigSendType" SG_ 2654552169 FD14_MeAP_b_EPSInterfaceTimeout 1;
BA_ "GenSigSendType" SG_ 2654552169 FD14_MeAP_b_BSMInterfaceTimeout 1;
BA_ "GenSigSendType" SG_ 2654552169 FD14_MeAP_b_VCOpPaused 1;
BA_ "GenSigSendType" SG_ 2654552169 FD14_MeAP_b_RPAwithBrkStatus 1;
BA_ "GenSigSendType" SG_ 2654552169 FD14_MeAP_b_RPAStatus 1;
BA_ "GenSigSendType" SG_ 2654552169 FD14_MeAP_b_FPAStatus 1;
BA_ "GenSigSendType" SG_ 2654552169 FD14_IeAP_e_AbortCon 1;
BA_ "GenSigSendType" SG_ 2654552169 FD14_IeAP_cnt_CurrentVehSweep 1;
BA_ "GenSigSendType" SG_ 2654552169 FD14_MeAP_e_PP_state 1;
BA_ "GenSigSendType" SG_ 2654552169 FD14_MeAP_cm_RearRightMinXDist 1;
BA_ "GenSigSendType" SG_ 2654552169 FD14_MeAP_cm_RearLeftMinXDist 1;
BA_ "GenSigSendType" SG_ 2654552169 FD14_MeAP_cm_RearCenterMinXDist 1;
BA_ "GenSigSendType" SG_ 2654552169 FD14_MeAP_cm_FrntRightMinXDist 1;
BA_ "GenSigSendType" SG_ 2654552169 FD14_MeAP_cm_FrntLeftMinXDist 1;
BA_ "GenSigSendType" SG_ 2654552169 FD14_MeAP_cm_FrntCenterMinXDist 1;
BA_ "GenSigSendType" SG_ 2654552169 FD14_MeAP_cnt_TransDebugVar_Copy 1;
BA_ "SystemSignalLongSymbol" SG_ 2654552169 FD14_MeAP_cnt_TransDebugVar_Copy "FD14_MeAP_cnt_TransDebugVar_Copy_1";
BA_ "GenSigSendType" SG_ 2654552169 FD14_MeAP_cnt_TransDebugVar 1;
BA_ "GenSigSendType" SG_ 2654552169 FD14_MeAP_cnt_StateDebugVar 1;
BA_ "GenSigSendType" SG_ 2654552217 FD14_CalibStatus_STM_Current_Rig 1;
BA_ "SystemSignalLongSymbol" SG_ 2654552217 FD14_CalibStatus_STM_Current_Rig "FD14_CalibStatus_STM_Current_Right";
BA_ "GenSigSendType" SG_ 2654552217 FD14_CalibStatus_STM_Current_Rea 1;
BA_ "SystemSignalLongSymbol" SG_ 2654552217 FD14_CalibStatus_STM_Current_Rea "FD14_CalibStatus_STM_Current_Rear";
BA_ "GenSigSendType" SG_ 2654552217 FD14_CalibStatus_STM_Current_Lef 1;
BA_ "SystemSignalLongSymbol" SG_ 2654552217 FD14_CalibStatus_STM_Current_Lef "FD14_CalibStatus_STM_Current_Left";
BA_ "GenSigSendType" SG_ 2654552217 FD14_CalibStatus_STM_Current_Fro 1;
BA_ "SystemSignalLongSymbol" SG_ 2654552217 FD14_CalibStatus_STM_Current_Fro "FD14_CalibStatus_STM_Current_Front";
BA_ "GenSigSendType" SG_ 2654552217 FD14_CalibStatus_STM_OC_Right 1;
BA_ "GenSigSendType" SG_ 2654552217 FD14_CalibStatus_STM_OC_Rear 1;
BA_ "GenSigSendType" SG_ 2654552217 FD14_CalibStatus_STM_OC_Left 1;
BA_ "GenSigSendType" SG_ 2654552217 FD14_CalibStatus_STM_OC_Front 1;
BA_ "GenSigSendType" SG_ 2654552217 FD14_CalibStatus_STM_SC_Right 1;
BA_ "GenSigSendType" SG_ 2654552217 FD14_CalibStatus_STM_SC_Rear 1;
BA_ "GenSigSendType" SG_ 2654552217 FD14_CalibStatus_STM_SC_Left 1;
BA_ "GenSigSendType" SG_ 2654552217 FD14_CalibStatus_STM_SC_Front 1;
BA_ "GenSigSendType" SG_ 2654552217 FD14_CalibStatus_STM_EOL_Right 1;
BA_ "GenSigSendType" SG_ 2654552217 FD14_CalibStatus_STM_EOL_Rear 1;
BA_ "GenSigSendType" SG_ 2654552217 FD14_CalibStatus_STM_EOL_Left 1;
BA_ "GenSigSendType" SG_ 2654552217 FD14_CalibStatus_STM_EOL_Front 1;
BA_ "GenSigSendType" SG_ 2654552163 FD14_Z_f32_Current_Right 1;
BA_ "GenSigSendType" SG_ 2654552163 FD14_Z_f32_Current_Rear 1;
BA_ "GenSigSendType" SG_ 2654552163 FD14_Pitch_f32_Current_Right 1;
BA_ "GenSigSendType" SG_ 2654552163 FD14_Pitch_f32_Current_Rear 1;
BA_ "GenSigSendType" SG_ 2654552163 FD14_Roll_f32_Current_Right 1;
BA_ "GenSigSendType" SG_ 2654552163 FD14_Roll_f32_Current_Rear 1;
BA_ "GenSigSendType" SG_ 2654552163 FD14_Yaw_f32_Current_Right 1;
BA_ "GenSigSendType" SG_ 2654552163 FD14_Yaw_f32_Current_Rear 1;
BA_ "GenSigSendType" SG_ 2654552163 FD14_Y_f32_Current_Right 1;
BA_ "GenSigSendType" SG_ 2654552163 FD14_Y_f32_Current_Rear 1;
BA_ "GenSigSendType" SG_ 2654552163 FD14_X_f32_Current_Right 1;
BA_ "GenSigSendType" SG_ 2654552163 FD14_X_f32_Current_Rear 1;
BA_ "GenSigSendType" SG_ 2654552152 FD14_Pitch_f32_EOL_Left 1;
BA_ "GenSigSendType" SG_ 2654552152 FD14_Roll_f32_EOL_Left 1;
BA_ "GenSigSendType" SG_ 2654552152 FD14_Yaw_f32_EOL_Left 1;
BA_ "GenSigSendType" SG_ 2654552152 FD14_Z_f32_EOL_Left 1;
BA_ "GenSigSendType" SG_ 2654552152 FD14_Y_f32_EOL_Left 1;
BA_ "GenSigSendType" SG_ 2654552152 FD14_X_f32_EOL_Left 1;
BA_ "GenSigSendType" SG_ 2654552152 FD14_Pitch_f32_EOL_Front 1;
BA_ "GenSigSendType" SG_ 2654552152 FD14_Roll_f32_EOL_Front 1;
BA_ "GenSigSendType" SG_ 2654552152 FD14_Yaw_f32_EOL_Front 1;
BA_ "GenSigSendType" SG_ 2654552152 FD14_Z_f32_EOL_Front 1;
BA_ "GenSigSendType" SG_ 2654552152 FD14_Y_f32_EOL_Front 1;
BA_ "GenSigSendType" SG_ 2654552152 FD14_X_f32_EOL_Front 1;
BA_ "GenSigSendType" SG_ 2654552164 FD14_Roll_f32_EOL_Right 1;
BA_ "GenSigSendType" SG_ 2654552164 FD14_Pitch_f32_EOL_Right 1;
BA_ "GenSigSendType" SG_ 2654552164 FD14_Yaw_f32_EOL_Right 1;
BA_ "GenSigSendType" SG_ 2654552164 FD14_Z_f32_EOL_Right 1;
BA_ "GenSigSendType" SG_ 2654552164 FD14_Y_f32_EOL_Right 1;
BA_ "GenSigSendType" SG_ 2654552164 FD14_X_f32_EOL_Right 1;
BA_ "GenSigSendType" SG_ 2654552164 FD14_Pitch_f32_EOL_Rear 1;
BA_ "GenSigSendType" SG_ 2654552164 FD14_Roll_f32_EOL_Rear 1;
BA_ "GenSigSendType" SG_ 2654552164 FD14_Yaw_f32_EOL_Rear 1;
BA_ "GenSigSendType" SG_ 2654552164 FD14_Z_f32_EOL_Rear 1;
BA_ "GenSigSendType" SG_ 2654552164 FD14_Y_f32_EOL_Rear 1;
BA_ "GenSigSendType" SG_ 2654552164 FD14_X_f32_EOL_Rear 1;
BA_ "GenSigSendType" SG_ 2654552216 FD14_Err_Code_OC_Right 1;
BA_ "GenSigSendType" SG_ 2654552216 FD14_Err_Code_OC_Rear 1;
BA_ "GenSigSendType" SG_ 2654552216 FD14_Err_Code_OC_Left 1;
BA_ "GenSigSendType" SG_ 2654552216 FD14_Err_Code_OC_Front 1;
BA_ "GenSigSendType" SG_ 2654552216 FD14_Err_Code_SC_Right 1;
BA_ "GenSigSendType" SG_ 2654552216 FD14_Err_Code_SC_Rear 1;
BA_ "GenSigSendType" SG_ 2654552216 FD14_Err_Code_SC_Left 1;
BA_ "GenSigSendType" SG_ 2654552216 FD14_Err_Code_SC_Front 1;
BA_ "GenSigSendType" SG_ 2654552216 FD14_Err_Code_EOL_Rear_Copy_1 1;
BA_ "GenSigSendType" SG_ 2654552216 FD14_Err_Code_EOL_Rear 1;
BA_ "GenSigSendType" SG_ 2654552216 FD14_Err_Code_EOL_Left 1;
BA_ "GenSigSendType" SG_ 2654552216 FD14_Err_Code_EOL_Front 1;
BA_ "GenSigSendType" SG_ 2654552162 FD14_InvalidFeatures_Right_u32 1;
BA_ "GenSigSendType" SG_ 2654552162 FD14_IgnoredFeatures_Right_u32 1;
BA_ "GenSigSendType" SG_ 2654552162 FD14_ValidFeatures_Right_u32 1;
BA_ "GenSigSendType" SG_ 2654552162 FD14_InvalidFeatures_Rear_u32 1;
BA_ "GenSigSendType" SG_ 2654552162 FD14_IgnoredFeatures_Rear_u32 1;
BA_ "GenSigSendType" SG_ 2654552162 FD14_ValidFeatures_Rear_u32 1;
BA_ "GenSigSendType" SG_ 2654552162 FD14_InvalidFeatures_Left_u32 1;
BA_ "GenSigSendType" SG_ 2654552162 FD14_IgnoredFeatures_Left_u32 1;
BA_ "GenSigSendType" SG_ 2654552162 FD14_ValidFeatures_Left_u32 1;
BA_ "GenSigSendType" SG_ 2654552162 FD14_InvalidFeatures_Front_u32 1;
BA_ "GenSigSendType" SG_ 2654552162 FD14_IgnoredFeatures_Front_u32 1;
BA_ "GenSigSendType" SG_ 2654552162 FD14_ValidFeatures_Front_u32 1;
BA_ "GenSigSendType" SG_ 2654552178 FD14_perpParkDirectionSel 1;
BA_ "GenSigSendType" SG_ 2654552178 FD14_parkExtSideSel 1;
BA_ "GenSigSendType" SG_ 2654552178 FD14_slotSide 1;
BA_ "GenSigSendType" SG_ 2654552178 FD14_parkingDirection 1;
BA_ "GenSigSendType" SG_ 2654552178 FD14_parkingSlotType 1;
BA_ "GenSigSendType" SG_ 2654552178 FD14_IsBackSftbtnSel 1;
BA_ "GenSigSendType" SG_ 2654552178 FD14_IsSlotSel 1;
BA_ "GenSigSendType" SG_ 2654552178 FD14_IsExitSftBtnSel 1;
BA_ "GenSigSendType" SG_ 2654552178 FD14_IsParkSftBtnSel 1;
BA_ "GenSigSendType" SG_ 2654552178 FD14_MaAP_m_ParkSpot4RearStreetY 1;
BA_ "GenSigSendType" SG_ 2654552178 FD14_MaAP_m_ParkSpot4RearStreetX 1;
BA_ "GenSigSendType" SG_ 2654552178 FD14_MaAP_m_ParkSpot3RearBorderY 1;
BA_ "GenSigSendType" SG_ 2654552178 FD14_MaAP_m_ParkSpot3RearBorderX 1;
BA_ "GenSigSendType" SG_ 2654552178 FD14_MaAP_m_ParkSpot2FrntBorderY 1;
BA_ "GenSigSendType" SG_ 2654552178 FD14_MaAP_m_ParkSpot2FrntBorderX 1;
BA_ "GenSigSendType" SG_ 2654552178 FD14_MaAP_m_ParkSpot1FrntStreetY 1;
BA_ "GenSigSendType" SG_ 2654552178 FD14_MaAP_m_ParkSpot1FrntStreetX 1;
BA_ "GenSigSendType" SG_ 2654552149 FD14_tchScrnStatus_e 1;
BA_ "GenSigSendType" SG_ 2654552149 FD14_View_Error_e 1;
BA_ "GenSigSendType" SG_ 2654552149 FD14_DynOvl_Error_e 1;
BA_ "GenSigSendType" SG_ 2654552149 FD14_SoftBtn_Error_e 1;
BA_ "GenSigSendType" SG_ 2654552149 FD14_ImageDefeat_Error_e 1;
BA_ "GenSigSendType" SG_ 2654552149 FD14_tgwDispStatus_e 1;
BA_ "GenSigSendType" SG_ 2654552149 FD14_CameraDisplaySts2_e 1;
BA_ "GenSigSendType" SG_ 2654552149 FD14_prndStatus_e 1;
BA_ "GenSigSendType" SG_ 2654552149 FD14_transEquipped_e 1;
BA_ "GenSigSendType" SG_ 2654552149 FD14_ignitionStatus_e 1;
BA_ "GenSigSendType" SG_ 2654552149 FD14_trscStat_e 1;
BA_ "GenSigSendType" SG_ 2654552149 FD14_NetCfg_TRSCM_e 1;
BA_ "GenSigSendType" SG_ 2654552149 FD14_revGear_e 1;
BA_ "GenSigSendType" SG_ 2654552149 FD14_lrwsST_e 1;
BA_ "GenSigSendType" SG_ 2654552149 FD14_GW_C_I6_timeout_b 1;
BA_ "GenSigStartValue" SG_ 2654552149 FD14_GW_C_I6_timeout_b 1;
BA_ "GenSigSendType" SG_ 2654552149 FD14_SVC_Delay_Feature_b 1;
BA_ "GenSigStartValue" SG_ 2654552149 FD14_SVC_Delay_Feature_b 1;
BA_ "GenSigSendType" SG_ 2654552149 FD14_SVC_FFCV_Gridlines_Feature_ 1;
BA_ "GenSigStartValue" SG_ 2654552149 FD14_SVC_FFCV_Gridlines_Feature_ 1;
BA_ "SystemSignalLongSymbol" SG_ 2654552149 FD14_SVC_FFCV_Gridlines_Feature_ "FD14_SVC_FFCV_Gridlines_Feature_b";
BA_ "GenSigSendType" SG_ 2654552149 FD14_SVC_Static_Gridlines_Featur 1;
BA_ "GenSigStartValue" SG_ 2654552149 FD14_SVC_Static_Gridlines_Featur 1;
BA_ "SystemSignalLongSymbol" SG_ 2654552149 FD14_SVC_Static_Gridlines_Featur "FD14_SVC_Static_Gridlines_Feature_b";
BA_ "GenSigSendType" SG_ 2654552149 FD14_SVC_Dynamic_Gridlines_Featu 1;
BA_ "GenSigStartValue" SG_ 2654552149 FD14_SVC_Dynamic_Gridlines_Featu 1;
BA_ "SystemSignalLongSymbol" SG_ 2654552149 FD14_SVC_Dynamic_Gridlines_Featu "FD14_SVC_Dynamic_Gridlines_Feature_b";
BA_ "GenSigSendType" SG_ 2654552149 FD14_TopVideoBlanked_b 1;
BA_ "GenSigStartValue" SG_ 2654552149 FD14_TopVideoBlanked_b 1;
BA_ "GenSigSendType" SG_ 2654552149 FD14_LanguageSelection_u8 1;
BA_ "GenSigSendType" SG_ 2654552149 FD14_vehicleLine_e 1;
BA_ "GenSigSendType" SG_ 2654552149 FD14_tchScrnCoord_s_Y_u16 1;
BA_ "GenSigSendType" SG_ 2654552149 FD14_tchScrnCoord_s_X_u16 1;
BA_ "GenSigSendType" SG_ 2654552149 FD14_CAM_NA_Bitfield_u8 1;
BA_ "GenSigSendType" SG_ 2654552149 FD14_vehicleSpeed_f32 1;
BA_ "GenSigSendType" SG_ 2654552149 FD14_steeringWheelAngle_f32 1;
BA_ "GenSigSendType" SG_ 2654552150 FD14_LastViewBeforeTestPattern_e 1;
BA_ "GenSigSendType" SG_ 2654552150 FD14_Prev_DisplayedViewByAcore_e 1;
BA_ "GenSigSendType" SG_ 2654552150 FD14_Curr_DisplayedViewByAcore_e 1;
BA_ "GenSigSendType" SG_ 2654552150 FD14_Prev_RequestedViewByHmiM_e 1;
BA_ "GenSigSendType" SG_ 2654552150 FD14_Curr_RequestedViewByHmiM_e 1;
BA_ "GenSigSendType" SG_ 2654552150 FD14_Prev_SystemState_e 1;
BA_ "GenSigSendType" SG_ 2654552150 FD14_Curr_SystemState_e 1;
BA_ "GenSigSendType" SG_ 2654552150 FD14_M_FFClatch_e 1;
BA_ "GenSigSendType" SG_ 2654552150 FD14_M_BURV_Memory_e 1;
BA_ "GenSigSendType" SG_ 2654552150 FD14_FRONT_TOP_BTN_PRESSED_b 1;
BA_ "GenSigSendType" SG_ 2654552150 FD14_REAR_TOP_BTN_PRESSED_b 1;
BA_ "GenSigSendType" SG_ 2654552150 FD14_MAGNIFIER_BTN_PRESSED_b 1;
BA_ "GenSigSendType" SG_ 2654552150 FD14_X_BTN_PRESSED_b 1;
BA_ "GenSigSendType" SG_ 2654552150 FD14_OFFROAD_ABSNT_MC_BTN_PRESSE 1;
BA_ "SystemSignalLongSymbol" SG_ 2654552150 FD14_OFFROAD_ABSNT_MC_BTN_PRESSE "FD14_OFFROAD_ABSNT_MC_BTN_PRESSED_b";
BA_ "GenSigSendType" SG_ 2654552150 FD14_OFFROAD_PRSNT_MC_BTN_PRESSE 1;
BA_ "SystemSignalLongSymbol" SG_ 2654552150 FD14_OFFROAD_PRSNT_MC_BTN_PRESSE "FD14_OFFROAD_PRSNT_MC_BTN_PRESSED_b";
BA_ "GenSigSendType" SG_ 2654552150 FD14_OFFRD_ABSNT_AUXCAM_BTN_PRES 1;
BA_ "SystemSignalLongSymbol" SG_ 2654552150 FD14_OFFRD_ABSNT_AUXCAM_BTN_PRES "FD14_OFFRD_ABSNT_AUXCAM_BTN_PRESSED_b";
BA_ "GenSigSendType" SG_ 2654552150 FD14_OFFRD_PRSNT_AUXCAM_BTN_PRES 1;
BA_ "SystemSignalLongSymbol" SG_ 2654552150 FD14_OFFRD_PRSNT_AUXCAM_BTN_PRES "FD14_OFFRD_PRSNT_AUXCAM_BTN_PRESSED_b";
BA_ "GenSigSendType" SG_ 2654552150 FD14_RVCONLY_BTN_PRESSED_b 1;
BA_ "GenSigSendType" SG_ 2654552150 FD14_FFCV_BTN_PRESSED_b 1;
BA_ "GenSigSendType" SG_ 2654552150 FD14_FRONT_CROSS_BTN_PRESSED_b 1;
BA_ "GenSigSendType" SG_ 2654552150 FD14_REAR_CROSS_BTN_PRESSED_b 1;
BA_ "GenSigSendType" SG_ 2654552150 FD14_IgnoreVehicleOffSpeed 1;
BA_ "GenSigSendType" SG_ 2654552150 FD14_ZoomFactor_u8 1;
BA_ "GenSigSendType" SG_ 2654552148 FD14_TrailerCalibrationStatus 1;
BA_ "GenSigSendType" SG_ 2654552148 FD14_TrscStatus 1;
BA_ "GenSigSendType" SG_ 2654552148 FD14__JackKnifeAngle 1;
BA_ "GenSigSendType" SG_ 2654552148 FD14_TrailerAngleSign 1;
BA_ "GenSigSendType" SG_ 2654552148 FD14_Prev_TRG_Stat 1;
BA_ "GenSigSendType" SG_ 2654552148 FD14_Curr_TRG_Stat 1;
BA_ "GenSigSendType" SG_ 2654552148 FD14_ItbmTrailerStatus 1;
BA_ "GenSigSendType" SG_ 2654552148 FD14_TrailerConnectionStatus 1;
BA_ "GenSigSendType" SG_ 2654552148 FD14_TrailerWheelBase 1;
BA_ "GenSigSendType" SG_ 2654552148 FD14_KnobAngle 1;
BA_ "GenSigSendType" SG_ 2654552148 FD14_MaxTadAngle 1;
BA_ "GenSigSendType" SG_ 2654552148 FD14_TadAngle 1;
BA_ "GenSigSendType" SG_ 2654552148 FD14_STM_v_TRGAUTO_BTN_PRESSED_b 1;
BA_ "GenSigSendType" SG_ 2654552148 FD14_STM_v_TRGRIGHT_BTN_PRESSED_ 1;
BA_ "SystemSignalLongSymbol" SG_ 2654552148 FD14_STM_v_TRGRIGHT_BTN_PRESSED_ "FD14_STM_v_TRGRIGHT_BTN_PRESSED_b";
BA_ "GenSigSendType" SG_ 2654552148 FD14_STM_v_TRGLEFT_BTN_PRESSED_b 1;
BA_ "GenSigSendType" SG_ 2654552148 FD14_M_Progress_Bar_Percentage 1;
BA_ "GenSigSendType" SG_ 2654552148 FD14_M_Maneuver_Initial_Run 1;
BA_ "GenSigSendType" SG_ 2654552148 FD14_M_Progress_Bar_Distance 1;
BA_ "GenSigSendType" SG_ 2654552148 FD14_M_Cplr_Htch_Distance 1;
BA_ "GenSigSendType" SG_ 2654552148 FD14_M_CPLR_POS_Y_u 1;
BA_ "GenSigSendType" SG_ 2654552148 FD14_M_CPLR_POS_X_u 1;
BA_ "GenSigSendType" SG_ 2654552148 FD14_M_THA_SFT_BTN_PRESSED_b 1;
BA_ "GenSigSendType" SG_ 2654552148 FD14_M_START_BTN_PRESSED_b 1;
BA_ "GenSigSendType" SG_ 2654552148 FD14_M_CONFIRM_BTN_PRESSED_b 1;
BA_ "GenSigSendType" SG_ 2654552148 FD14_M_VIEW_SCRN_TCH_STS_b 1;
BA_ "GenSigSendType" SG_ 2654552148 FD14_M_VIEW_ZOOM_STS_b 1;
BA_ "GenSigSendType" SG_ 2654552148 FD14_M_Current_THA_State_On_Scre 1;
BA_ "SystemSignalLongSymbol" SG_ 2654552148 FD14_M_Current_THA_State_On_Scre "FD14_M_Current_THA_State_On_Screen";
BA_ "GenSigSendType" SG_ 2654552148 FD14_M_Current_THA_State_On_Zync 1;
BA_ "GenSigSendType" SG_ 2654552148 FD14_M_Requested_THA_State 1;
BA_ "GenSigSendType" SG_ 2654552320 FD14_OC_ModuleState_STM_Right 1;
BA_ "GenSigSendType" SG_ 2654552320 FD14_OC_ModuleState_STM_Rear 1;
BA_ "GenSigSendType" SG_ 2654552320 FD14_OC_ModuleState_STM_Left 1;
BA_ "GenSigSendType" SG_ 2654552320 FD14_OC_ModuleState_STM_Front 1;
BA_ "GenSigSendType" SG_ 2654552320 FD14_SC_ModuleState_STM_Right 1;
BA_ "GenSigSendType" SG_ 2654552320 FD14_SC_ModuleState_STM_Rear 1;
BA_ "GenSigSendType" SG_ 2654552320 FD14_SC_ModuleState_STM_Left 1;
BA_ "GenSigSendType" SG_ 2654552320 FD14_SC_ModuleState_STM_Front 1;
BA_ "GenSigSendType" SG_ 2654552320 FD14_EOL_ModuleState_STM_Right 1;
BA_ "GenSigSendType" SG_ 2654552320 FD14_EOL_ModuleState_STM_Rear 1;
BA_ "GenSigSendType" SG_ 2654552320 FD14_EOL_ModuleState_STM_Left 1;
BA_ "GenSigSendType" SG_ 2654552320 FD14_EOL_ModuleState_STM_Front 1;
BA_ "GenSigSendType" SG_ 2654552176 FD14_NFCD_DistanceToClosestPoint 1;
BA_ "SystemSignalLongSymbol" SG_ 2654552176 FD14_NFCD_DistanceToClosestPoint "FD14_NFCD_DistanceToClosestPoint_1_4";
BA_ "GenSigSendType" SG_ 2654552176 FD14_NFCD_DistanceToClosest_0000 1;
BA_ "SystemSignalLongSymbol" SG_ 2654552176 FD14_NFCD_DistanceToClosest_0000 "FD14_NFCD_DistanceToClosestPoint_0_4";
BA_ "GenSigSendType" SG_ 2654552176 FD14_NFCD_ObjValid_4 1;
BA_ "GenSigSendType" SG_ 2654552176 FD14_NFCD_ObjValid_3 1;
BA_ "GenSigSendType" SG_ 2654552176 FD14_NFCD_DistanceToClosest_0001 1;
BA_ "SystemSignalLongSymbol" SG_ 2654552176 FD14_NFCD_DistanceToClosest_0001 "FD14_NFCD_DistanceToClosestPoint_1_3";
BA_ "GenSigSendType" SG_ 2654552176 FD14_NFCD_DistanceToClosest_0002 1;
BA_ "SystemSignalLongSymbol" SG_ 2654552176 FD14_NFCD_DistanceToClosest_0002 "FD14_NFCD_DistanceToClosestPoint_0_3";
BA_ "GenSigSendType" SG_ 2654552176 FD14_NFCD_ObjValid_2 1;
BA_ "GenSigSendType" SG_ 2654552176 FD14_NFCD_DistanceToClosest_0003 1;
BA_ "SystemSignalLongSymbol" SG_ 2654552176 FD14_NFCD_DistanceToClosest_0003 "FD14_NFCD_DistanceToClosestPoint_1_2";
BA_ "GenSigSendType" SG_ 2654552176 FD14_NFCD_DistanceToClosest_0004 1;
BA_ "SystemSignalLongSymbol" SG_ 2654552176 FD14_NFCD_DistanceToClosest_0004 "FD14_NFCD_DistanceToClosestPoint_0_2";
BA_ "GenSigSendType" SG_ 2654552176 FD14_NFCD_ObjValid_1 1;
BA_ "GenSigSendType" SG_ 2654552176 FD14_NFCD_DistanceToClosest_0005 1;
BA_ "SystemSignalLongSymbol" SG_ 2654552176 FD14_NFCD_DistanceToClosest_0005 "FD14_NFCD_DistanceToClosestPoint_1_1";
BA_ "GenSigSendType" SG_ 2654552176 FD14_NFCD_DistanceToClosest_0006 1;
BA_ "SystemSignalLongSymbol" SG_ 2654552176 FD14_NFCD_DistanceToClosest_0006 "FD14_NFCD_DistanceToClosestPoint_0_1";
BA_ "GenSigSendType" SG_ 2654552176 FD14_NFCD_ObjValid_0 1;
BA_ "GenSigSendType" SG_ 2654552176 FD14_NFCD_DistanceToClosest_0007 1;
BA_ "SystemSignalLongSymbol" SG_ 2654552176 FD14_NFCD_DistanceToClosest_0007 "FD14_NFCD_DistanceToClosestPoint_1_0";
BA_ "GenSigSendType" SG_ 2654552176 FD14_NFCD_DistanceToClosest_0008 1;
BA_ "SystemSignalLongSymbol" SG_ 2654552176 FD14_NFCD_DistanceToClosest_0008 "FD14_NFCD_DistanceToClosestPoint_0_0";
BA_ "GenSigSendType" SG_ 2654552177 FD14_IeVBII_nfcd_MinDisToCollisi 1;
BA_ "SystemSignalLongSymbol" SG_ 2654552177 FD14_IeVBII_nfcd_MinDisToCollisi "FD14_IeVBII_nfcd_MinDisToCollisionObj";
BA_ "GenSigSendType" SG_ 2654552177 FD14_NFCD_ObjValid_9 1;
BA_ "GenSigSendType" SG_ 2654552177 FD14_NFCD_DistanceToClosest_0009 1;
BA_ "SystemSignalLongSymbol" SG_ 2654552177 FD14_NFCD_DistanceToClosest_0009 "FD14_NFCD_DistanceToClosestPoint_1_9";
BA_ "GenSigSendType" SG_ 2654552177 FD14_NFCD_DistanceToClosest_0010 1;
BA_ "SystemSignalLongSymbol" SG_ 2654552177 FD14_NFCD_DistanceToClosest_0010 "FD14_NFCD_DistanceToClosestPoint_0_9";
BA_ "GenSigSendType" SG_ 2654552177 FD14_NFCD_ObjValid_8 1;
BA_ "GenSigSendType" SG_ 2654552177 FD14_NFCD_DistanceToClosest_0011 1;
BA_ "SystemSignalLongSymbol" SG_ 2654552177 FD14_NFCD_DistanceToClosest_0011 "FD14_NFCD_DistanceToClosestPoint_1_8";
BA_ "GenSigSendType" SG_ 2654552177 FD14_NFCD_DistanceToClosest_0012 1;
BA_ "SystemSignalLongSymbol" SG_ 2654552177 FD14_NFCD_DistanceToClosest_0012 "FD14_NFCD_DistanceToClosestPoint_0_8";
BA_ "GenSigSendType" SG_ 2654552177 FD14_NFCD_ObjValid_7 1;
BA_ "GenSigSendType" SG_ 2654552177 FD14_NFCD_DistanceToClosest_0013 1;
BA_ "SystemSignalLongSymbol" SG_ 2654552177 FD14_NFCD_DistanceToClosest_0013 "FD14_NFCD_DistanceToClosestPoint_1_7";
BA_ "GenSigSendType" SG_ 2654552177 FD14_NFCD_DistanceToClosest_0014 1;
BA_ "SystemSignalLongSymbol" SG_ 2654552177 FD14_NFCD_DistanceToClosest_0014 "FD14_NFCD_DistanceToClosestPoint_0_7";
BA_ "GenSigSendType" SG_ 2654552177 FD14_NFCD_ObjValid_6 1;
BA_ "GenSigSendType" SG_ 2654552177 FD14_NFCD_DistanceToClosest_0015 1;
BA_ "SystemSignalLongSymbol" SG_ 2654552177 FD14_NFCD_DistanceToClosest_0015 "FD14_NFCD_DistanceToClosestPoint_1_6";
BA_ "GenSigSendType" SG_ 2654552177 FD14_NFCD_DistanceToClosest_0016 1;
BA_ "SystemSignalLongSymbol" SG_ 2654552177 FD14_NFCD_DistanceToClosest_0016 "FD14_NFCD_DistanceToClosestPoint_0_6";
BA_ "GenSigSendType" SG_ 2654552177 FD14_NFCD_ObjValid_5 1;
BA_ "GenSigSendType" SG_ 2654552177 FD14_NFCD_DistanceToClosest_0017 1;
BA_ "SystemSignalLongSymbol" SG_ 2654552177 FD14_NFCD_DistanceToClosest_0017 "FD14_NFCD_DistanceToClosestPoint_1_5";
BA_ "GenSigSendType" SG_ 2654552177 FD14_NFCD_DistanceToClosest_0018 1;
BA_ "SystemSignalLongSymbol" SG_ 2654552177 FD14_NFCD_DistanceToClosest_0018 "FD14_NFCD_DistanceToClosestPoint_0_5";
BA_ "GenSigSendType" SG_ 2654552160 FD14_Z_f32_Current_Rear 1;
BA_ "GenSigSendType" SG_ 2654552160 FD14_Y_f32_Current_Rear 1;
BA_ "GenSigSendType" SG_ 2654552160 FD14_X_f32_Current_Rear 1;
BA_ "GenSigSendType" SG_ 2654552160 FD14_Pitch_f32_OC_Right 1;
BA_ "GenSigSendType" SG_ 2654552160 FD14_Roll_f32_OC_Right 1;
BA_ "GenSigSendType" SG_ 2654552160 FD14_Yaw_f32_OC_Right 1;
BA_ "GenSigSendType" SG_ 2654552160 FD14_Pitch_f32_OC_Rear 1;
BA_ "GenSigSendType" SG_ 2654552160 FD14_Roll_f32_OC_Rear 1;
BA_ "GenSigSendType" SG_ 2654552160 FD14_Yaw_f32_OC_Rear 1;
BA_ "GenSigSendType" SG_ 2654552160 FD14_Pitch_f32_OC_Left 1;
BA_ "GenSigSendType" SG_ 2654552160 FD14_Roll_f32_OC_Left 1;
BA_ "GenSigSendType" SG_ 2654552160 FD14_Yaw_f32_OC_Left 1;
BA_ "GenSigSendType" SG_ 2654552160 FD14_Pitch_f32_OC_Front 1;
BA_ "GenSigSendType" SG_ 2654552160 FD14_Roll_f32_OC_Front 1;
BA_ "GenSigSendType" SG_ 2654552160 FD14_Yaw_f32_OC_Front 1;
BA_ "GenSigSendType" SG_ 2654552153 FD14_Pitch_f32_SC_Right 1;
BA_ "GenSigSendType" SG_ 2654552153 FD14_Roll_f32_SC_Right 1;
BA_ "GenSigSendType" SG_ 2654552153 FD14_Yaw_f32_SC_Right 1;
BA_ "GenSigSendType" SG_ 2654552153 FD14_Pitch_f32_SC_Rear 1;
BA_ "GenSigSendType" SG_ 2654552153 FD14_Roll_f32_SC_Rear 1;
BA_ "GenSigSendType" SG_ 2654552153 FD14_Yaw_f32_SC_Rear 1;
BA_ "GenSigSendType" SG_ 2654552153 FD14_Pitch_f32_SC_Left 1;
BA_ "GenSigSendType" SG_ 2654552153 FD14_Roll_f32_SC_Left 1;
BA_ "GenSigSendType" SG_ 2654552153 FD14_Yaw_f32_SC_Left 1;
BA_ "GenSigSendType" SG_ 2654552153 FD14_Pitch_f32_SC_Front 1;
BA_ "GenSigSendType" SG_ 2654552153 FD14_Roll_f32_SC_Front 1;
BA_ "GenSigSendType" SG_ 2654552153 FD14_Yaw_f32_SC_Front 1;
BA_ "GenSigSendType" SG_ 2654552161 FD14_TargetDetectRightRear_Right 1;
BA_ "SystemSignalLongSymbol" SG_ 2654552161 FD14_TargetDetectRightRear_Right "FD14_TargetDetectRightRear_Right_s8";
BA_ "GenSigSendType" SG_ 2654552161 FD14_TargetDetectRightFront_Righ 1;
BA_ "SystemSignalLongSymbol" SG_ 2654552161 FD14_TargetDetectRightFront_Righ "FD14_TargetDetectRightFront_Right_s8";
BA_ "GenSigSendType" SG_ 2654552161 FD14_TargetDetectLeftRear_Right_ 1;
BA_ "SystemSignalLongSymbol" SG_ 2654552161 FD14_TargetDetectLeftRear_Right_ "FD14_TargetDetectLeftRear_Right_s8";
BA_ "GenSigSendType" SG_ 2654552161 FD14_TargetDetectLeftFront_Right 1;
BA_ "SystemSignalLongSymbol" SG_ 2654552161 FD14_TargetDetectLeftFront_Right "FD14_TargetDetectLeftFront_Right_s8";
BA_ "GenSigSendType" SG_ 2654552161 FD14_TargetLimitRear_Right_s8 1;
BA_ "GenSigSendType" SG_ 2654552161 FD14_TargetLimitFront_Right_s8 1;
BA_ "GenSigSendType" SG_ 2654552161 FD14_TargetInit_Right_s8 1;
BA_ "GenSigSendType" SG_ 2654552161 FD14_TargetDetectRightRear_Rear_ 1;
BA_ "SystemSignalLongSymbol" SG_ 2654552161 FD14_TargetDetectRightRear_Rear_ "FD14_TargetDetectRightRear_Rear_s8";
BA_ "GenSigSendType" SG_ 2654552161 FD14_TargetDetectRightFront_Rear 1;
BA_ "SystemSignalLongSymbol" SG_ 2654552161 FD14_TargetDetectRightFront_Rear "FD14_TargetDetectRightFront_Rear_s8";
BA_ "GenSigSendType" SG_ 2654552161 FD14_TargetDetectLeftRear_Rear_s 1;
BA_ "SystemSignalLongSymbol" SG_ 2654552161 FD14_TargetDetectLeftRear_Rear_s "FD14_TargetDetectLeftRear_Rear_s8";
BA_ "GenSigSendType" SG_ 2654552161 FD14_TargetDetectLeftFront_Rear_ 1;
BA_ "SystemSignalLongSymbol" SG_ 2654552161 FD14_TargetDetectLeftFront_Rear_ "FD14_TargetDetectLeftFront_Rear_s8";
BA_ "GenSigSendType" SG_ 2654552161 FD14_TargetLimitRear_Rear_s8 1;
BA_ "GenSigSendType" SG_ 2654552161 FD14_TargetLimitFront_Rear_s8 1;
BA_ "GenSigSendType" SG_ 2654552161 FD14_TargetInit_Rear_s8 1;
BA_ "GenSigSendType" SG_ 2654552161 FD14_TargetDetectRightRear_Left_ 1;
BA_ "SystemSignalLongSymbol" SG_ 2654552161 FD14_TargetDetectRightRear_Left_ "FD14_TargetDetectRightRear_Left_s8";
BA_ "GenSigSendType" SG_ 2654552161 FD14_TargetDetectRightFront_Left 1;
BA_ "SystemSignalLongSymbol" SG_ 2654552161 FD14_TargetDetectRightFront_Left "FD14_TargetDetectRightFront_Left_s8";
BA_ "GenSigSendType" SG_ 2654552161 FD14_TargetDetectLeftFront_Left_ 1;
BA_ "SystemSignalLongSymbol" SG_ 2654552161 FD14_TargetDetectLeftFront_Left_ "FD14_TargetDetectLeftFront_Left_s8";
BA_ "GenSigSendType" SG_ 2654552161 FD14_TargetLimitRear_Left_s8 1;
BA_ "GenSigSendType" SG_ 2654552161 FD14_TargetLimitFront_Left_s8 1;
BA_ "GenSigSendType" SG_ 2654552161 FD14_TargetInit_Left_s8 1;
BA_ "GenSigSendType" SG_ 2654552161 FD14_TargetDetectRightRear_Front 1;
BA_ "SystemSignalLongSymbol" SG_ 2654552161 FD14_TargetDetectRightRear_Front "FD14_TargetDetectRightRear_Front_s8";
BA_ "GenSigSendType" SG_ 2654552161 FD14_TargetDetectRightFront_Fron 1;
BA_ "SystemSignalLongSymbol" SG_ 2654552161 FD14_TargetDetectRightFront_Fron "FD14_TargetDetectRightFront_Front_s8";
BA_ "GenSigSendType" SG_ 2654552161 FD14_TargetDetectLeftRear_Front_ 1;
BA_ "SystemSignalLongSymbol" SG_ 2654552161 FD14_TargetDetectLeftRear_Front_ "FD14_TargetDetectLeftRear_Front_s8";
BA_ "GenSigSendType" SG_ 2654552161 FD14_TargetDetectLeftFront_Front 1;
BA_ "SystemSignalLongSymbol" SG_ 2654552161 FD14_TargetDetectLeftFront_Front "FD14_TargetDetectLeftFront_Front_s8";
BA_ "GenSigSendType" SG_ 2654552161 FD14_TargetLimitRear_Front_s8 1;
BA_ "GenSigSendType" SG_ 2654552161 FD14_TargetLimitFront_Front_s8 1;
BA_ "GenSigSendType" SG_ 2654552161 FD14_TargetInit_Front_s8 1;
BA_ "GenSigSendType" SG_ 2654552194 FD14_IeAP_cm_RearRightMinXDist_K 1;
BA_ "SystemSignalLongSymbol" SG_ 2654552194 FD14_IeAP_cm_RearRightMinXDist_K "FD14_IeAP_cm_RearRightMinXDist_KPI";
BA_ "GenSigSendType" SG_ 2654552194 FD14_IeAP_cm_RearRightMinXDist 1;
BA_ "GenSigSendType" SG_ 2654552194 FD14_IeAP_cm_RearLeftMinXDist_KP 1;
BA_ "SystemSignalLongSymbol" SG_ 2654552194 FD14_IeAP_cm_RearLeftMinXDist_KP "FD14_IeAP_cm_RearLeftMinXDist_KPI";
BA_ "GenSigSendType" SG_ 2654552194 FD14_IeAP_cm_RearLeftMinXDist 1;
BA_ "GenSigSendType" SG_ 2654552194 FD14_IeAP_cm_RearCenterMinXDist_ 1;
BA_ "SystemSignalLongSymbol" SG_ 2654552194 FD14_IeAP_cm_RearCenterMinXDist_ "FD14_IeAP_cm_RearCenterMinXDist_KPI";
BA_ "GenSigSendType" SG_ 2654552194 FD14_IeAP_cm_RearCenterMinXDist 1;
BA_ "GenSigSendType" SG_ 2654552194 FD14_IeAP_cm_FrntRightMinXDist_K 1;
BA_ "SystemSignalLongSymbol" SG_ 2654552194 FD14_IeAP_cm_FrntRightMinXDist_K "FD14_IeAP_cm_FrntRightMinXDist_KPI";
BA_ "GenSigSendType" SG_ 2654552194 FD14_IeAP_cm_FrntRightMinXDist 1;
BA_ "GenSigSendType" SG_ 2654552194 FD14_IeAP_cm_FrntLeftMinXDist_KP 1;
BA_ "SystemSignalLongSymbol" SG_ 2654552194 FD14_IeAP_cm_FrntLeftMinXDist_KP "FD14_IeAP_cm_FrntLeftMinXDist_KPI";
BA_ "GenSigSendType" SG_ 2654552194 FD14_IeAP_cm_FrntLeftMinXDist 1;
BA_ "GenSigSendType" SG_ 2654552194 FD14_IeAP_cm_FrntCenterMinXDist_ 1;
BA_ "SystemSignalLongSymbol" SG_ 2654552194 FD14_IeAP_cm_FrntCenterMinXDist_ "FD14_IeAP_cm_FrntCenterMinXDist_KPI";
BA_ "GenSigSendType" SG_ 2654552194 FD14_IeAP_cm_FrntCenterMinXDist 1;
BA_ "GenSigSendType" SG_ 2654814232 FD14_IeAP_cm_RearRightMinXD_0000 1;
BA_ "SystemSignalLongSymbol" SG_ 2654814232 FD14_IeAP_cm_RearRightMinXD_0000 "FD14_IeAP_cm_RearRightMinXDist_KPI";
BA_ "GenSigSendType" SG_ 2654814232 FD14_IeAP_cm_RearLeftMinXDi_0000 1;
BA_ "SystemSignalLongSymbol" SG_ 2654814232 FD14_IeAP_cm_RearLeftMinXDi_0000 "FD14_IeAP_cm_RearLeftMinXDist_KPI";
BA_ "GenSigSendType" SG_ 2654814232 FD14_IeAP_cm_RearCenterMinX_0000 1;
BA_ "SystemSignalLongSymbol" SG_ 2654814232 FD14_IeAP_cm_RearCenterMinX_0000 "FD14_IeAP_cm_RearCenterMinXDist_KPI";
BA_ "GenSigSendType" SG_ 2654814232 FD14_IeAP_cm_FrntRightMinXD_0000 1;
BA_ "SystemSignalLongSymbol" SG_ 2654814232 FD14_IeAP_cm_FrntRightMinXD_0000 "FD14_IeAP_cm_FrntRightMinXDist_KPI";
BA_ "GenSigSendType" SG_ 2654814232 FD14_IeAP_cm_FrntLeftMinXDi_0000 1;
BA_ "SystemSignalLongSymbol" SG_ 2654814232 FD14_IeAP_cm_FrntLeftMinXDi_0000 "FD14_IeAP_cm_FrntLeftMinXDist_KPI";
BA_ "GenSigSendType" SG_ 2654814232 FD14_IeAP_cm_FrntCenterMinX_0000 1;
BA_ "SystemSignalLongSymbol" SG_ 2654814232 FD14_IeAP_cm_FrntCenterMinX_0000 "FD14_IeAP_cm_FrntCenterMinXDist_KPI";
BA_ "GenSigSendType" SG_ 2654814209 FD14_BOR_CommUnknown 1;
BA_ "GenSigSendType" SG_ 2654814209 FD14_AOR_CommUnknown 1;
BA_ "GenSigSendType" SG_ 2654814209 FD14_BOL_CommUnknown 1;
BA_ "GenSigSendType" SG_ 2654814209 FD14_AOL_CommUnknown 1;
BA_ "GenSigSendType" SG_ 2654814209 FD14_RSL_CommUnknown 1;
BA_ "GenSigSendType" SG_ 2654814209 FD14_ROL_CommUnknown 1;
BA_ "GenSigSendType" SG_ 2654814209 FD14_RIL_CommUnknown 1;
BA_ "GenSigSendType" SG_ 2654814209 FD14_RIR_CommUnknown 1;
BA_ "GenSigSendType" SG_ 2654814209 FD14_ROR_CommUnknown 1;
BA_ "GenSigSendType" SG_ 2654814209 FD14_RSR_CommUnknown 1;
BA_ "GenSigSendType" SG_ 2654814209 FD14_FSL_CommUnknown 1;
BA_ "GenSigSendType" SG_ 2654814209 FD14_FOL_CommUnknown 1;
BA_ "GenSigSendType" SG_ 2654814209 FD14_FIL_CommUnknown 1;
BA_ "GenSigSendType" SG_ 2654814209 FD14_FIR_CommUnknown 1;
BA_ "GenSigSendType" SG_ 2654814209 FD14_FOR_CommUnknown 1;
BA_ "GenSigSendType" SG_ 2654814209 FD14_FSR_CommUnknown 1;
BA_ "GenSigSendType" SG_ 2654814209 FD14_BOR_hardware_Fault 1;
BA_ "GenSigSendType" SG_ 2654814209 FD14_AOR_hardware_Fault 1;
BA_ "GenSigSendType" SG_ 2654814209 FD14_BOL_hardware_Fault 1;
BA_ "GenSigSendType" SG_ 2654814209 FD14_AOL_hardware_Fault 1;
BA_ "GenSigSendType" SG_ 2654814209 FD14_RSL_hardware_Fault 1;
BA_ "GenSigSendType" SG_ 2654814209 FD14_ROL_hardware_Fault 1;
BA_ "GenSigSendType" SG_ 2654814209 FD14_RIL_hardware_Fault 1;
BA_ "GenSigSendType" SG_ 2654814209 FD14_RIR_hardware_Fault 1;
BA_ "GenSigSendType" SG_ 2654814209 FD14_ROR_hardware_Fault 1;
BA_ "GenSigSendType" SG_ 2654814209 FD14_RSR_hardware_Fault 1;
BA_ "GenSigSendType" SG_ 2654814209 FD14_FSL_hardware_Fault 1;
BA_ "GenSigSendType" SG_ 2654814209 FD14_FOL_hardware_Fault 1;
BA_ "GenSigSendType" SG_ 2654814209 FD14_FIL_hardware_Fault 1;
BA_ "GenSigSendType" SG_ 2654814209 FD14_FIR_hardware_Fault 1;
BA_ "GenSigSendType" SG_ 2654814209 FD14_FOR_hardware_Fault 1;
BA_ "GenSigSendType" SG_ 2654814209 FD14_FSR_hardware_Fault 1;
BA_ "GenSigSendType" SG_ 2654814209 FD14_FIR_comm_Fault 1;
BA_ "GenSigSendType" SG_ 2654814209 FD14_BOR_comm_Fault 1;
BA_ "GenSigSendType" SG_ 2654814209 FD14_AOR_comm_Fault 1;
BA_ "GenSigSendType" SG_ 2654814209 FD14_BOL_comm_Fault 1;
BA_ "GenSigSendType" SG_ 2654814209 FD14_AOL_comm_Fault 1;
BA_ "GenSigSendType" SG_ 2654814209 FD14_RSL_comm_Fault 1;
BA_ "GenSigSendType" SG_ 2654814209 FD14_ROL_comm_Fault 1;
BA_ "GenSigSendType" SG_ 2654814209 FD14_RIL_comm_Fault 1;
BA_ "GenSigSendType" SG_ 2654814209 FD14_RIR_comm_Fault 1;
BA_ "GenSigSendType" SG_ 2654814209 FD14_ROR_comm_Fault 1;
BA_ "GenSigSendType" SG_ 2654814209 FD14_RSR_comm_Fault 1;
BA_ "GenSigSendType" SG_ 2654814209 FD14_FSL_comm_Fault 1;
BA_ "GenSigSendType" SG_ 2654814209 FD14_FOL_comm_Fault 1;
BA_ "GenSigSendType" SG_ 2654814209 FD14_FIL_comm_Fault 1;
BA_ "GenSigSendType" SG_ 2654814209 FD14_FOR_comm_Fault 1;
BA_ "GenSigSendType" SG_ 2654814209 FD14_FSR_comm_Fault 1;
BA_ "GenSigSendType" SG_ 2654814209 FD14_RSR_overTemp_Fault 1;
BA_ "GenSigSendType" SG_ 2654814209 FD14_RSL_overTemp_Fault 1;
BA_ "GenSigSendType" SG_ 2654814209 FD14_ROR_overTemp_Fault 1;
BA_ "GenSigSendType" SG_ 2654814209 FD14_ROL_overTemp_Fault 1;
BA_ "GenSigSendType" SG_ 2654814209 FD14_RIR_overTemp_Fault 1;
BA_ "GenSigSendType" SG_ 2654814209 FD14_RIL_overTemp_Fault 1;
BA_ "GenSigSendType" SG_ 2654814209 FD14_FSL_overTemp_Fault 1;
BA_ "GenSigSendType" SG_ 2654814209 FD14_FOL_overTemp_Fault 1;
BA_ "GenSigSendType" SG_ 2654814209 FD14_FIR_overTemp_Fault 1;
BA_ "GenSigSendType" SG_ 2654814209 FD14_FIL_overTemp_Fault 1;
BA_ "GenSigSendType" SG_ 2654814209 FD14_BOR_overTemp_Fault 1;
BA_ "GenSigSendType" SG_ 2654814209 FD14_BOL_overTemp_Fault 1;
BA_ "GenSigSendType" SG_ 2654814209 FD14_AOR_overTemp_Fault 1;
BA_ "GenSigSendType" SG_ 2654814209 FD14_AOL_overTemp_Fault 1;
BA_ "GenSigSendType" SG_ 2654814209 FD14_FOR_overTemp_Fault 1;
BA_ "GenSigSendType" SG_ 2654814209 FD14_FSR_overTemp_Fault 1;
BA_ "GenSigSendType" SG_ 2654552195 FD14_Point_Map_Cruising_Age_7 1;
BA_ "GenSigSendType" SG_ 2654552195 FD14_Point_Map_Cruising_Age_6 1;
BA_ "GenSigSendType" SG_ 2654552195 FD14_Point_Map_Cruising_Age_5 1;
BA_ "GenSigSendType" SG_ 2654552195 FD14_Point_Map_Cruising_Age_4 1;
BA_ "GenSigSendType" SG_ 2654552195 FD14_Point_Map_Cruising_Age_3 1;
BA_ "GenSigSendType" SG_ 2654552195 FD14_Point_Map_Cruising_Age_2 1;
BA_ "GenSigSendType" SG_ 2654552195 FD14_Point_Map_Cruising_Age_1 1;
BA_ "GenSigSendType" SG_ 2654552195 FD14_Point_Map_Cruising_Age_0 1;
BA_ "GenSigSendType" SG_ 2654552195 FD14_Point_Map_Reserved_7 1;
BA_ "GenSigSendType" SG_ 2654552195 FD14_Point_Map_Reserved_6 1;
BA_ "GenSigSendType" SG_ 2654552195 FD14_Point_Map_Reserved_5 1;
BA_ "GenSigSendType" SG_ 2654552195 FD14_Point_Map_Reserved_4 1;
BA_ "GenSigSendType" SG_ 2654552195 FD14_Point_Map_Reserved_3 1;
BA_ "GenSigSendType" SG_ 2654552195 FD14_Point_Map_Reserved_2 1;
BA_ "GenSigSendType" SG_ 2654552195 FD14_Point_Map_Reserved_1 1;
BA_ "GenSigSendType" SG_ 2654552195 FD14_Point_Map_Reserved_0 1;
BA_ "GenSigSendType" SG_ 2654552195 FD14_Point_Map_Age_7 1;
BA_ "GenSigSendType" SG_ 2654552195 FD14_Point_Map_Confidence_7 1;
BA_ "GenSigSendType" SG_ 2654552195 FD14_Point_Map_Height_7 1;
BA_ "GenSigSendType" SG_ 2654552195 FD14_Point_Map_Y_7 1;
BA_ "GenSigSendType" SG_ 2654552195 FD14_Point_Map_X_7 1;
BA_ "GenSigSendType" SG_ 2654552195 FD14_Point_Map_Age_6 1;
BA_ "GenSigSendType" SG_ 2654552195 FD14_Point_Map_Confidence_6 1;
BA_ "GenSigSendType" SG_ 2654552195 FD14_Point_Map_Height_6 1;
BA_ "GenSigSendType" SG_ 2654552195 FD14_Point_Map_Y_6 1;
BA_ "GenSigSendType" SG_ 2654552195 FD14_Point_Map_X_6 1;
BA_ "GenSigSendType" SG_ 2654552195 FD14_Point_Map_Age_5 1;
BA_ "GenSigSendType" SG_ 2654552195 FD14_Point_Map_Confidence_5 1;
BA_ "GenSigSendType" SG_ 2654552195 FD14_Point_Map_Height_5 1;
BA_ "GenSigSendType" SG_ 2654552195 FD14_Point_Map_Y_5 1;
BA_ "GenSigSendType" SG_ 2654552195 FD14_Point_Map_X_5 1;
BA_ "GenSigSendType" SG_ 2654552195 FD14_Point_Map_Age_4 1;
BA_ "GenSigSendType" SG_ 2654552195 FD14_Point_Map_Confidence_4 1;
BA_ "GenSigSendType" SG_ 2654552195 FD14_Point_Map_Height_4 1;
BA_ "GenSigSendType" SG_ 2654552195 FD14_Point_Map_Y_4 1;
BA_ "GenSigSendType" SG_ 2654552195 FD14_Point_Map_X_4 1;
BA_ "GenSigSendType" SG_ 2654552195 FD14_Point_Map_Age_3 1;
BA_ "GenSigSendType" SG_ 2654552195 FD14_Point_Map_Confidence_3 1;
BA_ "GenSigSendType" SG_ 2654552195 FD14_Point_Map_Height_3 1;
BA_ "GenSigSendType" SG_ 2654552195 FD14_Point_Map_Y_3 1;
BA_ "GenSigSendType" SG_ 2654552195 FD14_Point_Map_X_3 1;
BA_ "GenSigSendType" SG_ 2654552195 FD14_Point_Map_Age_2 1;
BA_ "GenSigSendType" SG_ 2654552195 FD14_Point_Map_Confidence_2 1;
BA_ "GenSigSendType" SG_ 2654552195 FD14_Point_Map_Height_2 1;
BA_ "GenSigSendType" SG_ 2654552195 FD14_Point_Map_Y_2 1;
BA_ "GenSigSendType" SG_ 2654552195 FD14_Point_Map_X_2 1;
BA_ "GenSigSendType" SG_ 2654552195 FD14_Point_Map_Age_1 1;
BA_ "GenSigSendType" SG_ 2654552195 FD14_Point_Map_Confidence_1 1;
BA_ "GenSigSendType" SG_ 2654552195 FD14_Point_Map_Height_1 1;
BA_ "GenSigSendType" SG_ 2654552195 FD14_Point_Map_Y_1 1;
BA_ "GenSigSendType" SG_ 2654552195 FD14_Point_Map_X_1 1;
BA_ "GenSigSendType" SG_ 2654552195 FD14_Point_Map_Age_0 1;
BA_ "GenSigSendType" SG_ 2654552195 FD14_Point_Map_Confidence_0 1;
BA_ "GenSigSendType" SG_ 2654552195 FD14_Point_Map_Height_0 1;
BA_ "GenSigSendType" SG_ 2654552195 FD14_Point_Map_Y_0 1;
BA_ "GenSigSendType" SG_ 2654552195 FD14_Point_Map_X_0 1;
BA_ "GenSigSendType" SG_ 2654552196 FD14_Point_Map_Cruising_Age_15 1;
BA_ "GenSigSendType" SG_ 2654552196 FD14_Point_Map_Cruising_Age_14 1;
BA_ "GenSigSendType" SG_ 2654552196 FD14_Point_Map_Cruising_Age_13 1;
BA_ "GenSigSendType" SG_ 2654552196 FD14_Point_Map_Cruising_Age_12 1;
BA_ "GenSigSendType" SG_ 2654552196 FD14_Point_Map_Cruising_Age_11 1;
BA_ "GenSigSendType" SG_ 2654552196 FD14_Point_Map_Cruising_Age_10 1;
BA_ "GenSigSendType" SG_ 2654552196 FD14_Point_Map_Cruising_Age_9 1;
BA_ "GenSigSendType" SG_ 2654552196 FD14_Point_Map_Cruising_Age_8 1;
BA_ "GenSigSendType" SG_ 2654552196 FD14_Point_Map_Reserved_8 1;
BA_ "GenSigSendType" SG_ 2654552196 FD14_Point_Map_Age_8 1;
BA_ "GenSigSendType" SG_ 2654552196 FD14_Point_Map_Confidence_8 1;
BA_ "GenSigSendType" SG_ 2654552196 FD14_Point_Map_Height_8 1;
BA_ "GenSigSendType" SG_ 2654552196 FD14_Point_Map_Y_8 1;
BA_ "GenSigSendType" SG_ 2654552196 FD14_Point_Map_X_8 1;
BA_ "GenSigSendType" SG_ 2654552196 FD14_Point_Map_Reserved_15 1;
BA_ "GenSigSendType" SG_ 2654552196 FD14_Point_Map_Reserved_14 1;
BA_ "GenSigSendType" SG_ 2654552196 FD14_Point_Map_Reserved_13 1;
BA_ "GenSigSendType" SG_ 2654552196 FD14_Point_Map_Reserved_12 1;
BA_ "GenSigSendType" SG_ 2654552196 FD14_Point_Map_Reserved_11 1;
BA_ "GenSigSendType" SG_ 2654552196 FD14_Point_Map_Reserved_10 1;
BA_ "GenSigSendType" SG_ 2654552196 FD14_Point_Map_Reserved_9 1;
BA_ "GenSigSendType" SG_ 2654552196 FD14_Point_Map_Age_15 1;
BA_ "GenSigSendType" SG_ 2654552196 FD14_Point_Map_Confidence_15 1;
BA_ "GenSigSendType" SG_ 2654552196 FD14_Point_Map_Height_15 1;
BA_ "GenSigSendType" SG_ 2654552196 FD14_Point_Map_Y_15 1;
BA_ "GenSigSendType" SG_ 2654552196 FD14_Point_Map_X_15 1;
BA_ "GenSigSendType" SG_ 2654552196 FD14_Point_Map_Age_14 1;
BA_ "GenSigSendType" SG_ 2654552196 FD14_Point_Map_Confidence_14 1;
BA_ "GenSigSendType" SG_ 2654552196 FD14_Point_Map_Height_14 1;
BA_ "GenSigSendType" SG_ 2654552196 FD14_Point_Map_Y_14 1;
BA_ "GenSigSendType" SG_ 2654552196 FD14_Point_Map_X_14 1;
BA_ "GenSigSendType" SG_ 2654552196 FD14_Point_Map_Age_13 1;
BA_ "GenSigSendType" SG_ 2654552196 FD14_Point_Map_Confidence_13 1;
BA_ "GenSigSendType" SG_ 2654552196 FD14_Point_Map_Height_13 1;
BA_ "GenSigSendType" SG_ 2654552196 FD14_Point_Map_Y_13 1;
BA_ "GenSigSendType" SG_ 2654552196 FD14_Point_Map_X_13 1;
BA_ "GenSigSendType" SG_ 2654552196 FD14_Point_Map_Age_12 1;
BA_ "GenSigSendType" SG_ 2654552196 FD14_Point_Map_Confidence_12 1;
BA_ "GenSigSendType" SG_ 2654552196 FD14_Point_Map_Height_12 1;
BA_ "GenSigSendType" SG_ 2654552196 FD14_Point_Map_Y_12 1;
BA_ "GenSigSendType" SG_ 2654552196 FD14_Point_Map_X_12 1;
BA_ "GenSigSendType" SG_ 2654552196 FD14_Point_Map_Age_11 1;
BA_ "GenSigSendType" SG_ 2654552196 FD14_Point_Map_Confidence_11 1;
BA_ "GenSigSendType" SG_ 2654552196 FD14_Point_Map_Height_11 1;
BA_ "GenSigSendType" SG_ 2654552196 FD14_Point_Map_Y_11 1;
BA_ "GenSigSendType" SG_ 2654552196 FD14_Point_Map_X_11 1;
BA_ "GenSigSendType" SG_ 2654552196 FD14_Point_Map_Age_10 1;
BA_ "GenSigSendType" SG_ 2654552196 FD14_Point_Map_Confidence_10 1;
BA_ "GenSigSendType" SG_ 2654552196 FD14_Point_Map_Height_10 1;
BA_ "GenSigSendType" SG_ 2654552196 FD14_Point_Map_Y_10 1;
BA_ "GenSigSendType" SG_ 2654552196 FD14_Point_Map_X_10 1;
BA_ "GenSigSendType" SG_ 2654552196 FD14_Point_Map_Age_9 1;
BA_ "GenSigSendType" SG_ 2654552196 FD14_Point_Map_Confidence_9 1;
BA_ "GenSigSendType" SG_ 2654552196 FD14_Point_Map_Height_9 1;
BA_ "GenSigSendType" SG_ 2654552196 FD14_Point_Map_Y_9 1;
BA_ "GenSigSendType" SG_ 2654552196 FD14_Point_Map_X_9 1;
BA_ "GenSigSendType" SG_ 2654552197 FD14_Point_Map_Cruising_Age_23 1;
BA_ "GenSigSendType" SG_ 2654552197 FD14_Point_Map_Cruising_Age_22 1;
BA_ "GenSigSendType" SG_ 2654552197 FD14_Point_Map_Cruising_Age_21 1;
BA_ "GenSigSendType" SG_ 2654552197 FD14_Point_Map_Cruising_Age_20 1;
BA_ "GenSigSendType" SG_ 2654552197 FD14_Point_Map_Cruising_Age_19 1;
BA_ "GenSigSendType" SG_ 2654552197 FD14_Point_Map_Cruising_Age_18 1;
BA_ "GenSigSendType" SG_ 2654552197 FD14_Point_Map_Cruising_Age_17 1;
BA_ "GenSigSendType" SG_ 2654552197 FD14_Point_Map_Cruising_Age_16 1;
BA_ "GenSigSendType" SG_ 2654552197 FD14_Point_Map_Reserved_17 1;
BA_ "GenSigSendType" SG_ 2654552197 FD14_Point_Map_Height_17 1;
BA_ "GenSigSendType" SG_ 2654552197 FD14_Point_Map_Age_17 1;
BA_ "GenSigSendType" SG_ 2654552197 FD14_Point_Map_Confidence_17 1;
BA_ "GenSigSendType" SG_ 2654552197 FD14_Point_Map_Y_17 1;
BA_ "GenSigSendType" SG_ 2654552197 FD14_Point_Map_X_17 1;
BA_ "GenSigSendType" SG_ 2654552197 FD14_Point_Map_Reserved_16 1;
BA_ "GenSigSendType" SG_ 2654552197 FD14_Point_Map_Age_16 1;
BA_ "GenSigSendType" SG_ 2654552197 FD14_Point_Map_Confidence_16 1;
BA_ "GenSigSendType" SG_ 2654552197 FD14_Point_Map_Height_16 1;
BA_ "GenSigSendType" SG_ 2654552197 FD14_Point_Map_Y_16 1;
BA_ "GenSigSendType" SG_ 2654552197 FD14_Point_Map_X_16 1;
BA_ "GenSigSendType" SG_ 2654552197 FD14_Point_Map_Reserved_23 1;
BA_ "GenSigSendType" SG_ 2654552197 FD14_Point_Map_Reserved_22 1;
BA_ "GenSigSendType" SG_ 2654552197 FD14_Point_Map_Reserved_21 1;
BA_ "GenSigSendType" SG_ 2654552197 FD14_Point_Map_Reserved_20 1;
BA_ "GenSigSendType" SG_ 2654552197 FD14_Point_Map_Reserved_19 1;
BA_ "GenSigSendType" SG_ 2654552197 FD14_Point_Map_Reserved_18 1;
BA_ "GenSigSendType" SG_ 2654552197 FD14_Point_Map_Age_23 1;
BA_ "GenSigSendType" SG_ 2654552197 FD14_Point_Map_Confidence_23 1;
BA_ "GenSigSendType" SG_ 2654552197 FD14_Point_Map_Height_23 1;
BA_ "GenSigSendType" SG_ 2654552197 FD14_Point_Map_Y_23 1;
BA_ "GenSigSendType" SG_ 2654552197 FD14_Point_Map_X_23 1;
BA_ "GenSigSendType" SG_ 2654552197 FD14_Point_Map_Age_22 1;
BA_ "GenSigSendType" SG_ 2654552197 FD14_Point_Map_Confidence_22 1;
BA_ "GenSigSendType" SG_ 2654552197 FD14_Point_Map_Height_22 1;
BA_ "GenSigSendType" SG_ 2654552197 FD14_Point_Map_Y_22 1;
BA_ "GenSigSendType" SG_ 2654552197 FD14_Point_Map_X_22 1;
BA_ "GenSigSendType" SG_ 2654552197 FD14_Point_Map_Age_21 1;
BA_ "GenSigSendType" SG_ 2654552197 FD14_Point_Map_Confidence_21 1;
BA_ "GenSigSendType" SG_ 2654552197 FD14_Point_Map_Height_21 1;
BA_ "GenSigSendType" SG_ 2654552197 FD14_Point_Map_Y_21 1;
BA_ "GenSigSendType" SG_ 2654552197 FD14_Point_Map_X_21 1;
BA_ "GenSigSendType" SG_ 2654552197 FD14_Point_Map_Age_20 1;
BA_ "GenSigSendType" SG_ 2654552197 FD14_Point_Map_Confidence_20 1;
BA_ "GenSigSendType" SG_ 2654552197 FD14_Point_Map_Height_20 1;
BA_ "GenSigSendType" SG_ 2654552197 FD14_Point_Map_Y_20 1;
BA_ "GenSigSendType" SG_ 2654552197 FD14_Point_Map_X_20 1;
BA_ "GenSigSendType" SG_ 2654552197 FD14_Point_Map_Age_19 1;
BA_ "GenSigSendType" SG_ 2654552197 FD14_Point_Map_Confidence_19 1;
BA_ "GenSigSendType" SG_ 2654552197 FD14_Point_Map_Height_19 1;
BA_ "GenSigSendType" SG_ 2654552197 FD14_Point_Map_Y_19 1;
BA_ "GenSigSendType" SG_ 2654552197 FD14_Point_Map_X_19 1;
BA_ "GenSigSendType" SG_ 2654552197 FD14_Point_Map_Age_18 1;
BA_ "GenSigSendType" SG_ 2654552197 FD14_Point_Map_Confidence_18 1;
BA_ "GenSigSendType" SG_ 2654552197 FD14_Point_Map_Height_18 1;
BA_ "GenSigSendType" SG_ 2654552197 FD14_Point_Map_Y_18 1;
BA_ "GenSigSendType" SG_ 2654552197 FD14_Point_Map_X_18 1;
BA_ "GenSigSendType" SG_ 2654552198 FD14_Point_Map_Cruising_Age_31 1;
BA_ "GenSigSendType" SG_ 2654552198 FD14_Point_Map_Cruising_Age_30 1;
BA_ "GenSigSendType" SG_ 2654552198 FD14_Point_Map_Cruising_Age_29 1;
BA_ "GenSigSendType" SG_ 2654552198 FD14_Point_Map_Cruising_Age_28 1;
BA_ "GenSigSendType" SG_ 2654552198 FD14_Point_Map_Cruising_Age_27 1;
BA_ "GenSigSendType" SG_ 2654552198 FD14_Point_Map_Cruising_Age_26 1;
BA_ "GenSigSendType" SG_ 2654552198 FD14_Point_Map_Cruising_Age_25 1;
BA_ "GenSigSendType" SG_ 2654552198 FD14_Point_Map_Cruising_Age_24 1;
BA_ "GenSigSendType" SG_ 2654552198 FD14_Point_Map_Reserved_26 1;
BA_ "GenSigSendType" SG_ 2654552198 FD14_Point_Map_Age_26 1;
BA_ "GenSigSendType" SG_ 2654552198 FD14_Point_Map_Confidence_26 1;
BA_ "GenSigSendType" SG_ 2654552198 FD14_Point_Map_Height_26 1;
BA_ "GenSigSendType" SG_ 2654552198 FD14_Point_Map_Y_26 1;
BA_ "GenSigSendType" SG_ 2654552198 FD14_Point_Map_X_26 1;
BA_ "GenSigSendType" SG_ 2654552198 FD14_Point_Map_Reserved_25 1;
BA_ "GenSigSendType" SG_ 2654552198 FD14_Point_Map_Age_25 1;
BA_ "GenSigSendType" SG_ 2654552198 FD14_Point_Map_Confidence_25 1;
BA_ "GenSigSendType" SG_ 2654552198 FD14_Point_Map_Height_25 1;
BA_ "GenSigSendType" SG_ 2654552198 FD14_Point_Map_Y_25 1;
BA_ "GenSigSendType" SG_ 2654552198 FD14_Point_Map_X_25 1;
BA_ "GenSigSendType" SG_ 2654552198 FD14_Point_Map_Reserved_24 1;
BA_ "GenSigSendType" SG_ 2654552198 FD14_Point_Map_Age_24 1;
BA_ "GenSigSendType" SG_ 2654552198 FD14_Point_Map_Confidence_24 1;
BA_ "GenSigSendType" SG_ 2654552198 FD14_Point_Map_Height_24 1;
BA_ "GenSigSendType" SG_ 2654552198 FD14_Point_Map_Y_24 1;
BA_ "GenSigSendType" SG_ 2654552198 FD14_Point_Map_X_24 1;
BA_ "GenSigSendType" SG_ 2654552198 FD14_Point_Map_Reserved_31 1;
BA_ "GenSigSendType" SG_ 2654552198 FD14_Point_Map_Reserved_30 1;
BA_ "GenSigSendType" SG_ 2654552198 FD14_Point_Map_Reserved_29 1;
BA_ "GenSigSendType" SG_ 2654552198 FD14_Point_Map_Reserved_28 1;
BA_ "GenSigSendType" SG_ 2654552198 FD14_Point_Map_Reserved_27 1;
BA_ "GenSigSendType" SG_ 2654552198 FD14_Point_Map_Age_31 1;
BA_ "GenSigSendType" SG_ 2654552198 FD14_Point_Map_Confidence_31 1;
BA_ "GenSigSendType" SG_ 2654552198 FD14_Point_Map_Height_31 1;
BA_ "GenSigSendType" SG_ 2654552198 FD14_Point_Map_Y_31 1;
BA_ "GenSigSendType" SG_ 2654552198 FD14_Point_Map_X_31 1;
BA_ "GenSigSendType" SG_ 2654552198 FD14_Point_Map_Age_30 1;
BA_ "GenSigSendType" SG_ 2654552198 FD14_Point_Map_Confidence_30 1;
BA_ "GenSigSendType" SG_ 2654552198 FD14_Point_Map_Height_30 1;
BA_ "GenSigSendType" SG_ 2654552198 FD14_Point_Map_Y_30 1;
BA_ "GenSigSendType" SG_ 2654552198 FD14_Point_Map_X_30 1;
BA_ "GenSigSendType" SG_ 2654552198 FD14_Point_Map_Age_29 1;
BA_ "GenSigSendType" SG_ 2654552198 FD14_Point_Map_Confidence_29 1;
BA_ "GenSigSendType" SG_ 2654552198 FD14_Point_Map_Height_29 1;
BA_ "GenSigSendType" SG_ 2654552198 FD14_Point_Map_Y_29 1;
BA_ "GenSigSendType" SG_ 2654552198 FD14_Point_Map_X_29 1;
BA_ "GenSigSendType" SG_ 2654552198 FD14_Point_Map_Age_28 1;
BA_ "GenSigSendType" SG_ 2654552198 FD14_Point_Map_Confidence_28 1;
BA_ "GenSigSendType" SG_ 2654552198 FD14_Point_Map_Height_28 1;
BA_ "GenSigSendType" SG_ 2654552198 FD14_Point_Map_Y_28 1;
BA_ "GenSigSendType" SG_ 2654552198 FD14_Point_Map_X_27 1;
BA_ "GenSigSendType" SG_ 2654552198 FD14_Point_Map_Age_27 1;
BA_ "GenSigSendType" SG_ 2654552198 FD14_Point_Map_Confidence_27 1;
BA_ "GenSigSendType" SG_ 2654552198 FD14_Point_Map_Height_27 1;
BA_ "GenSigSendType" SG_ 2654552198 FD14_Point_Map_Y_27 1;
BA_ "GenSigSendType" SG_ 2654552198 FD14_Point_Map_X_28 1;
BA_ "GenSigSendType" SG_ 2654552199 FD14_Point_Map_Cruising_Age_39 1;
BA_ "GenSigSendType" SG_ 2654552199 FD14_Point_Map_Cruising_Age_38 1;
BA_ "GenSigSendType" SG_ 2654552199 FD14_Point_Map_Cruising_Age_37 1;
BA_ "GenSigSendType" SG_ 2654552199 FD14_Point_Map_Cruising_Age_36 1;
BA_ "GenSigSendType" SG_ 2654552199 FD14_Point_Map_Cruising_Age_35 1;
BA_ "GenSigSendType" SG_ 2654552199 FD14_Point_Map_Cruising_Age_34 1;
BA_ "GenSigSendType" SG_ 2654552199 FD14_Point_Map_Cruising_Age_33 1;
BA_ "GenSigSendType" SG_ 2654552199 FD14_Point_Map_Cruising_Age_32 1;
BA_ "GenSigSendType" SG_ 2654552199 FD14_Point_Map_Reserved_35 1;
BA_ "GenSigSendType" SG_ 2654552199 FD14_Point_Map_Age_35 1;
BA_ "GenSigSendType" SG_ 2654552199 FD14_Point_Map_Confidence_35 1;
BA_ "GenSigSendType" SG_ 2654552199 FD14_Point_Map_Height_35 1;
BA_ "GenSigSendType" SG_ 2654552199 FD14_Point_Map_Y_35 1;
BA_ "GenSigSendType" SG_ 2654552199 FD14_Point_Map_X_35 1;
BA_ "GenSigSendType" SG_ 2654552199 FD14_Point_Map_Reserved_34 1;
BA_ "GenSigSendType" SG_ 2654552199 FD14_Point_Map_Age_34 1;
BA_ "GenSigSendType" SG_ 2654552199 FD14_Point_Map_Confidence_34 1;
BA_ "GenSigSendType" SG_ 2654552199 FD14_Point_Map_Height_34 1;
BA_ "GenSigSendType" SG_ 2654552199 FD14_Point_Map_Y_34 1;
BA_ "GenSigSendType" SG_ 2654552199 FD14_Point_Map_X_34 1;
BA_ "GenSigSendType" SG_ 2654552199 FD14_Point_Map_Reserved_33 1;
BA_ "GenSigSendType" SG_ 2654552199 FD14_Point_Map_Age_33 1;
BA_ "GenSigSendType" SG_ 2654552199 FD14_Point_Map_Confidence_33 1;
BA_ "GenSigSendType" SG_ 2654552199 FD14_Point_Map_Height_33 1;
BA_ "GenSigSendType" SG_ 2654552199 FD14_Point_Map_Y_33 1;
BA_ "GenSigSendType" SG_ 2654552199 FD14_Point_Map_X_33 1;
BA_ "GenSigSendType" SG_ 2654552199 FD14_Point_Map_Reserved_32 1;
BA_ "GenSigSendType" SG_ 2654552199 FD14_Point_Map_Age_32 1;
BA_ "GenSigSendType" SG_ 2654552199 FD14_Point_Map_Confidence_32 1;
BA_ "GenSigSendType" SG_ 2654552199 FD14_Point_Map_Height_32 1;
BA_ "GenSigSendType" SG_ 2654552199 FD14_Point_Map_Y_32 1;
BA_ "GenSigSendType" SG_ 2654552199 FD14_Point_Map_X_32 1;
BA_ "GenSigSendType" SG_ 2654552199 FD14_Point_Map_Reserved_39 1;
BA_ "GenSigSendType" SG_ 2654552199 FD14_Point_Map_Reserved_38 1;
BA_ "GenSigSendType" SG_ 2654552199 FD14_Point_Map_Reserved_37 1;
BA_ "GenSigSendType" SG_ 2654552199 FD14_Point_Map_Reserved_36 1;
BA_ "GenSigSendType" SG_ 2654552199 FD14_Point_Map_Age_39 1;
BA_ "GenSigSendType" SG_ 2654552199 FD14_Point_Map_Confidence_39 1;
BA_ "GenSigSendType" SG_ 2654552199 FD14_Point_Map_Height_39 1;
BA_ "GenSigSendType" SG_ 2654552199 FD14_Point_Map_Y_39 1;
BA_ "GenSigSendType" SG_ 2654552199 FD14_Point_Map_X_39 1;
BA_ "GenSigSendType" SG_ 2654552199 FD14_Point_Map_Age_38 1;
BA_ "GenSigSendType" SG_ 2654552199 FD14_Point_Map_Confidence_38 1;
BA_ "GenSigSendType" SG_ 2654552199 FD14_Point_Map_Height_38 1;
BA_ "GenSigSendType" SG_ 2654552199 FD14_Point_Map_Y_38 1;
BA_ "GenSigSendType" SG_ 2654552199 FD14_Point_Map_X_38 1;
BA_ "GenSigSendType" SG_ 2654552199 FD14_Point_Map_Age_37 1;
BA_ "GenSigSendType" SG_ 2654552199 FD14_Point_Map_Confidence_37 1;
BA_ "GenSigSendType" SG_ 2654552199 FD14_Point_Map_Height_37 1;
BA_ "GenSigSendType" SG_ 2654552199 FD14_Point_Map_Y_37 1;
BA_ "GenSigSendType" SG_ 2654552199 FD14_Point_Map_X_37 1;
BA_ "GenSigSendType" SG_ 2654552199 FD14_Point_Map_Age_36 1;
BA_ "GenSigSendType" SG_ 2654552199 FD14_Point_Map_Confidence_36 1;
BA_ "GenSigSendType" SG_ 2654552199 FD14_Point_Map_Height_36 1;
BA_ "GenSigSendType" SG_ 2654552199 FD14_Point_Map_Y_36 1;
BA_ "GenSigSendType" SG_ 2654552199 FD14_Point_Map_X_36 1;
BA_ "GenSigSendType" SG_ 2654552200 FD14_Point_Map_Cruising_Age_47 1;
BA_ "GenSigSendType" SG_ 2654552200 FD14_Point_Map_Cruising_Age_46 1;
BA_ "GenSigSendType" SG_ 2654552200 FD14_Point_Map_Cruising_Age_45 1;
BA_ "GenSigSendType" SG_ 2654552200 FD14_Point_Map_Cruising_Age_44 1;
BA_ "GenSigSendType" SG_ 2654552200 FD14_Point_Map_Cruising_Age_43 1;
BA_ "GenSigSendType" SG_ 2654552200 FD14_Point_Map_Cruising_Age_42 1;
BA_ "GenSigSendType" SG_ 2654552200 FD14_Point_Map_Cruising_Age_41 1;
BA_ "GenSigSendType" SG_ 2654552200 FD14_Point_Map_Cruising_Age_40 1;
BA_ "GenSigSendType" SG_ 2654552200 FD14_Point_Map_Reserved_44 1;
BA_ "GenSigSendType" SG_ 2654552200 FD14_Point_Map_Age_44 1;
BA_ "GenSigSendType" SG_ 2654552200 FD14_Point_Map_Confidence_44 1;
BA_ "GenSigSendType" SG_ 2654552200 FD14_Point_Map_Height_44 1;
BA_ "GenSigSendType" SG_ 2654552200 FD14_Point_Map_Y_44 1;
BA_ "GenSigSendType" SG_ 2654552200 FD14_Point_Map_X_44 1;
BA_ "GenSigSendType" SG_ 2654552200 FD14_Point_Map_Reserved_43 1;
BA_ "GenSigSendType" SG_ 2654552200 FD14_Point_Map_Age_43 1;
BA_ "GenSigSendType" SG_ 2654552200 FD14_Point_Map_Confidence_43 1;
BA_ "GenSigSendType" SG_ 2654552200 FD14_Point_Map_Height_43 1;
BA_ "GenSigSendType" SG_ 2654552200 FD14_Point_Map_Y_43 1;
BA_ "GenSigSendType" SG_ 2654552200 FD14_Point_Map_X_43 1;
BA_ "GenSigSendType" SG_ 2654552200 FD14_Point_Map_Reserved_42 1;
BA_ "GenSigSendType" SG_ 2654552200 FD14_Point_Map_Age_42 1;
BA_ "GenSigSendType" SG_ 2654552200 FD14_Point_Map_Confidence_42 1;
BA_ "GenSigSendType" SG_ 2654552200 FD14_Point_Map_Height_42 1;
BA_ "GenSigSendType" SG_ 2654552200 FD14_Point_Map_Y_42 1;
BA_ "GenSigSendType" SG_ 2654552200 FD14_Point_Map_X_42 1;
BA_ "GenSigSendType" SG_ 2654552200 FD14_Point_Map_Reserved_41 1;
BA_ "GenSigSendType" SG_ 2654552200 FD14_Point_Map_Age_41 1;
BA_ "GenSigSendType" SG_ 2654552200 FD14_Point_Map_Confidence_41 1;
BA_ "GenSigSendType" SG_ 2654552200 FD14_Point_Map_Height_41 1;
BA_ "GenSigSendType" SG_ 2654552200 FD14_Point_Map_Y_41 1;
BA_ "GenSigSendType" SG_ 2654552200 FD14_Point_Map_X_41 1;
BA_ "GenSigSendType" SG_ 2654552200 FD14_Point_Map_Reserved_40 1;
BA_ "GenSigSendType" SG_ 2654552200 FD14_Point_Map_Age_40 1;
BA_ "GenSigSendType" SG_ 2654552200 FD14_Point_Map_Confidence_40 1;
BA_ "GenSigSendType" SG_ 2654552200 FD14_Point_Map_Height_40 1;
BA_ "GenSigSendType" SG_ 2654552200 FD14_Point_Map_Y_40 1;
BA_ "GenSigSendType" SG_ 2654552200 FD14_Point_Map_X_40 1;
BA_ "GenSigSendType" SG_ 2654552200 FD14_Point_Map_Reserved_47 1;
BA_ "GenSigSendType" SG_ 2654552200 FD14_Point_Map_Reserved_46 1;
BA_ "GenSigSendType" SG_ 2654552200 FD14_Point_Map_Reserved_45 1;
BA_ "GenSigSendType" SG_ 2654552200 FD14_Point_Map_Age_47 1;
BA_ "GenSigSendType" SG_ 2654552200 FD14_Point_Map_Confidence_47 1;
BA_ "GenSigSendType" SG_ 2654552200 FD14_Point_Map_Height_47 1;
BA_ "GenSigSendType" SG_ 2654552200 FD14_Point_Map_Y_47 1;
BA_ "GenSigSendType" SG_ 2654552200 FD14_Point_Map_X_47 1;
BA_ "GenSigSendType" SG_ 2654552200 FD14_Point_Map_Age_46 1;
BA_ "GenSigSendType" SG_ 2654552200 FD14_Point_Map_Confidence_46 1;
BA_ "GenSigSendType" SG_ 2654552200 FD14_Point_Map_Height_46 1;
BA_ "GenSigSendType" SG_ 2654552200 FD14_Point_Map_Y_46 1;
BA_ "GenSigSendType" SG_ 2654552200 FD14_Point_Map_X_46 1;
BA_ "GenSigSendType" SG_ 2654552200 FD14_Point_Map_Age_45 1;
BA_ "GenSigSendType" SG_ 2654552200 FD14_Point_Map_Confidence_45 1;
BA_ "GenSigSendType" SG_ 2654552200 FD14_Point_Map_Height_45 1;
BA_ "GenSigSendType" SG_ 2654552200 FD14_Point_Map_Y_45 1;
BA_ "GenSigSendType" SG_ 2654552200 FD14_Point_Map_X_45 1;
BA_ "GenSigSendType" SG_ 2654552201 FD14_Point_Map_Cruising_Age_55 1;
BA_ "GenSigSendType" SG_ 2654552201 FD14_Point_Map_Cruising_Age_54 1;
BA_ "GenSigSendType" SG_ 2654552201 FD14_Point_Map_Cruising_Age_53 1;
BA_ "GenSigSendType" SG_ 2654552201 FD14_Point_Map_Cruising_Age_52 1;
BA_ "GenSigSendType" SG_ 2654552201 FD14_Point_Map_Cruising_Age_51 1;
BA_ "GenSigSendType" SG_ 2654552201 FD14_Point_Map_Cruising_Age_50 1;
BA_ "GenSigSendType" SG_ 2654552201 FD14_Point_Map_Cruising_Age_49 1;
BA_ "GenSigSendType" SG_ 2654552201 FD14_Point_Map_Cruising_Age_48 1;
BA_ "GenSigSendType" SG_ 2654552201 FD14_Point_Map_Reserved_53 1;
BA_ "GenSigSendType" SG_ 2654552201 FD14_Point_Map_Age_53 1;
BA_ "GenSigSendType" SG_ 2654552201 FD14_Point_Map_Confidence_53 1;
BA_ "GenSigSendType" SG_ 2654552201 FD14_Point_Map_Height_53 1;
BA_ "GenSigSendType" SG_ 2654552201 FD14_Point_Map_Y_53 1;
BA_ "GenSigSendType" SG_ 2654552201 FD14_Point_Map_X_53 1;
BA_ "GenSigSendType" SG_ 2654552201 FD14_Point_Map_Reserved_52 1;
BA_ "GenSigSendType" SG_ 2654552201 FD14_Point_Map_Age_52 1;
BA_ "GenSigSendType" SG_ 2654552201 FD14_Point_Map_Confidence_52 1;
BA_ "GenSigSendType" SG_ 2654552201 FD14_Point_Map_Height_52 1;
BA_ "GenSigSendType" SG_ 2654552201 FD14_Point_Map_Y_52 1;
BA_ "GenSigSendType" SG_ 2654552201 FD14_Point_Map_X_52 1;
BA_ "GenSigSendType" SG_ 2654552201 FD14_Point_Map_Reserved_51 1;
BA_ "GenSigSendType" SG_ 2654552201 FD14_Point_Map_Age_51 1;
BA_ "GenSigSendType" SG_ 2654552201 FD14_Point_Map_Confidence_51 1;
BA_ "GenSigSendType" SG_ 2654552201 FD14_Point_Map_Height_51 1;
BA_ "GenSigSendType" SG_ 2654552201 FD14_Point_Map_Y_51 1;
BA_ "GenSigSendType" SG_ 2654552201 FD14_Point_Map_X_51 1;
BA_ "GenSigSendType" SG_ 2654552201 FD14_Point_Map_Reserved_50 1;
BA_ "GenSigSendType" SG_ 2654552201 FD14_Point_Map_Age_50 1;
BA_ "GenSigSendType" SG_ 2654552201 FD14_Point_Map_Confidence_50 1;
BA_ "GenSigSendType" SG_ 2654552201 FD14_Point_Map_Height_50 1;
BA_ "GenSigSendType" SG_ 2654552201 FD14_Point_Map_Y_50 1;
BA_ "GenSigSendType" SG_ 2654552201 FD14_Point_Map_X_50 1;
BA_ "GenSigSendType" SG_ 2654552201 FD14_Point_Map_Reserved_49 1;
BA_ "GenSigSendType" SG_ 2654552201 FD14_Point_Map_Age_49 1;
BA_ "GenSigSendType" SG_ 2654552201 FD14_Point_Map_Confidence_49 1;
BA_ "GenSigSendType" SG_ 2654552201 FD14_Point_Map_Height_49 1;
BA_ "GenSigSendType" SG_ 2654552201 FD14_Point_Map_Y_49 1;
BA_ "GenSigSendType" SG_ 2654552201 FD14_Point_Map_X_49 1;
BA_ "GenSigSendType" SG_ 2654552201 FD14_Point_Map_Reserved_48 1;
BA_ "GenSigSendType" SG_ 2654552201 FD14_Point_Map_Age_48 1;
BA_ "GenSigSendType" SG_ 2654552201 FD14_Point_Map_Confidence_48 1;
BA_ "GenSigSendType" SG_ 2654552201 FD14_Point_Map_Height_48 1;
BA_ "GenSigSendType" SG_ 2654552201 FD14_Point_Map_Y_48 1;
BA_ "GenSigSendType" SG_ 2654552201 FD14_Point_Map_X_48 1;
BA_ "GenSigSendType" SG_ 2654552201 FD14_Point_Map_Reserved_54 1;
BA_ "GenSigSendType" SG_ 2654552201 FD14_Point_Map_Reserved_55 1;
BA_ "GenSigSendType" SG_ 2654552201 FD14_Point_Map_Confidence_55 1;
BA_ "GenSigSendType" SG_ 2654552201 FD14_Point_Map_Age_55 1;
BA_ "GenSigSendType" SG_ 2654552201 FD14_Point_Map_Height_55 1;
BA_ "GenSigSendType" SG_ 2654552201 FD14_Point_Map_Y_55 1;
BA_ "GenSigSendType" SG_ 2654552201 FD14_Point_Map_X_55 1;
BA_ "GenSigSendType" SG_ 2654552201 FD14_Point_Map_Age_54 1;
BA_ "GenSigSendType" SG_ 2654552201 FD14_Point_Map_Confidence_54 1;
BA_ "GenSigSendType" SG_ 2654552201 FD14_Point_Map_Height_54 1;
BA_ "GenSigSendType" SG_ 2654552201 FD14_Point_Map_Y_54 1;
BA_ "GenSigSendType" SG_ 2654552201 FD14_Point_Map_X_54 1;
BA_ "GenSigSendType" SG_ 2654552208 FD14_Point_Map_Cruising_Age_63 1;
BA_ "GenSigSendType" SG_ 2654552208 FD14_Point_Map_Cruising_Age_62 1;
BA_ "GenSigSendType" SG_ 2654552208 FD14_Point_Map_Cruising_Age_61 1;
BA_ "GenSigSendType" SG_ 2654552208 FD14_Point_Map_Cruising_Age_60 1;
BA_ "GenSigSendType" SG_ 2654552208 FD14_Point_Map_Cruising_Age_59 1;
BA_ "GenSigSendType" SG_ 2654552208 FD14_Point_Map_Cruising_Age_58 1;
BA_ "GenSigSendType" SG_ 2654552208 FD14_Point_Map_Cruising_Age_57 1;
BA_ "GenSigSendType" SG_ 2654552208 FD14_Point_Map_Cruising_Age_56 1;
BA_ "GenSigSendType" SG_ 2654552208 FD14_Point_Map_Reserved_62 1;
BA_ "GenSigSendType" SG_ 2654552208 FD14_Point_Map_Age_62 1;
BA_ "GenSigSendType" SG_ 2654552208 FD14_Point_Map_Confidence_62 1;
BA_ "GenSigSendType" SG_ 2654552208 FD14_Point_Map_Height_62 1;
BA_ "GenSigSendType" SG_ 2654552208 FD14_Point_Map_Y_62 1;
BA_ "GenSigSendType" SG_ 2654552208 FD14_Point_Map_X_62 1;
BA_ "GenSigSendType" SG_ 2654552208 FD14_Point_Map_Reserved_61 1;
BA_ "GenSigSendType" SG_ 2654552208 FD14_Point_Map_Age_61 1;
BA_ "GenSigSendType" SG_ 2654552208 FD14_Point_Map_Confidence_61 1;
BA_ "GenSigSendType" SG_ 2654552208 FD14_Point_Map_Height_61 1;
BA_ "GenSigSendType" SG_ 2654552208 FD14_Point_Map_Y_61 1;
BA_ "GenSigSendType" SG_ 2654552208 FD14_Point_Map_X_61 1;
BA_ "GenSigSendType" SG_ 2654552208 FD14_Point_Map_Reserved_60 1;
BA_ "GenSigSendType" SG_ 2654552208 FD14_Point_Map_Confidence_60 1;
BA_ "GenSigSendType" SG_ 2654552208 FD14_Point_Map_Height_60 1;
BA_ "GenSigSendType" SG_ 2654552208 FD14_Point_Map_Age_60 1;
BA_ "GenSigSendType" SG_ 2654552208 FD14_Point_Map_Y_60 1;
BA_ "GenSigSendType" SG_ 2654552208 FD14_Point_Map_X_60 1;
BA_ "GenSigSendType" SG_ 2654552208 FD14_Point_Map_Reserved_59 1;
BA_ "GenSigSendType" SG_ 2654552208 FD14_Point_Map_Age_59 1;
BA_ "GenSigSendType" SG_ 2654552208 FD14_Point_Map_Confidence_59 1;
BA_ "GenSigSendType" SG_ 2654552208 FD14_Point_Map_Height_59 1;
BA_ "GenSigSendType" SG_ 2654552208 FD14_Point_Map_Y_59 1;
BA_ "GenSigSendType" SG_ 2654552208 FD14_Point_Map_X_59 1;
BA_ "GenSigSendType" SG_ 2654552208 FD14_Point_Map_Reserved_58 1;
BA_ "GenSigSendType" SG_ 2654552208 FD14_Point_Map_Age_58 1;
BA_ "GenSigSendType" SG_ 2654552208 FD14_Point_Map_Confidence_58 1;
BA_ "GenSigSendType" SG_ 2654552208 FD14_Point_Map_Height_58 1;
BA_ "GenSigSendType" SG_ 2654552208 FD14_Point_Map_Y_58 1;
BA_ "GenSigSendType" SG_ 2654552208 FD14_Point_Map_X_58 1;
BA_ "GenSigSendType" SG_ 2654552208 FD14_Point_Map_Reserved_57 1;
BA_ "GenSigSendType" SG_ 2654552208 FD14_Point_Map_Age_57 1;
BA_ "GenSigSendType" SG_ 2654552208 FD14_Point_Map_Confidence_57 1;
BA_ "GenSigSendType" SG_ 2654552208 FD14_Point_Map_Height_57 1;
BA_ "GenSigSendType" SG_ 2654552208 FD14_Point_Map_Y_57 1;
BA_ "GenSigSendType" SG_ 2654552208 FD14_Point_Map_X_57 1;
BA_ "GenSigSendType" SG_ 2654552208 FD14_Point_Map_Reserved_56 1;
BA_ "GenSigSendType" SG_ 2654552208 FD14_Point_Map_Age_56 1;
BA_ "GenSigSendType" SG_ 2654552208 FD14_Point_Map_Confidence_56 1;
BA_ "GenSigSendType" SG_ 2654552208 FD14_Point_Map_Height_56 1;
BA_ "GenSigSendType" SG_ 2654552208 FD14_Point_Map_Y_56 1;
BA_ "GenSigSendType" SG_ 2654552208 FD14_Point_Map_X_56 1;
BA_ "GenSigSendType" SG_ 2654552208 FD14_Point_Map_Reserved_63 1;
BA_ "GenSigSendType" SG_ 2654552208 FD14_Point_Map_Age_63 1;
BA_ "GenSigSendType" SG_ 2654552208 FD14_Point_Map_Confidence_63 1;
BA_ "GenSigSendType" SG_ 2654552208 FD14_Point_Map_Height_63 1;
BA_ "GenSigSendType" SG_ 2654552208 FD14_Point_Map_Y_63 1;
BA_ "GenSigSendType" SG_ 2654552208 FD14_Point_Map_X_63 1;
VAL_ 2654814279 FD14_CsmStateCurrent 15 "SNA" 14 "Reserved" 13 "Reserved" 12 "Reserved" 11 "Reserved" 10 "Reserved" 9 "Reserved" 8 "UssCsmStateShutdown" 7 "UssCsmStatePreShutdown" 6 "UssCsmStateSafeState1" 5 "UssCsmStatePreSafeState1" 4 "UssCsmStateDegraded" 3 "UssCsmStatePreDegraded" 2 "UssCsmStateActive" 1 "UssCsmStateInit" 0 "UssCsmStateUninit" ;
VAL_ 2654814279 FD14_CsmStatePrevious 15 "SNA" 14 "Reserved" 13 "Reserved" 12 "Reserved" 11 "Reserved" 10 "Reserved" 9 "Reserved" 8 "UssCsmStateShutdown" 7 "UssCsmStatePreShutdown" 6 "UssCsmStateSafeState1" 5 "UssCsmStatePreSafeState1" 4 "UssCsmStateDegraded" 3 "UssCsmStatePreDegraded" 2 "UssCsmStateActive" 1 "UssCsmStateInit" 0 "UssCsmStateUninit" ;
VAL_ 2654814279 FD14_CsmLocalModuleId 15 "SNA" 14 "Feature" 13 "Reserved" 12 "Reserved" 11 "Reserved" 10 "Reserved" 9 "Reserved" 8 "Reserved" 7 "UssCalibration" 6 "ObjectDetection" 5 "UssSensorControl" 4 "UssSesnsorDriver" 3 "DSI3_Trcv" 2 "HighSideDriver" 1 "Platform" 0 "Csm" ;
VAL_ 2654814279 FD14_CsmLocalErrOrEventState 7 "SNA" 6 "Reserved" 5 "Reserved" 4 "Reserved" 3 "Undefined" 2 "Confirm" 1 "Active" 0 "Passive" ;
VAL_ 2654814208 FD14_BOR_Blockage 3 "SNA" 2 "Not_Active_failure" 1 "Not_Active_blocked" 0 "Active" ;
VAL_ 2654814208 FD14_AOR_Blockage 3 "SNA" 2 "Not_Active_failure" 1 "Not_Active_blocked" 0 "Active" ;
VAL_ 2654814208 FD14_BOL_Blockage 3 "SNA" 2 "Not_Active_failure" 1 "Not_Active_blocked" 0 "Active" ;
VAL_ 2654814208 FD14_AOL_Blockage 3 "SNA" 2 "Not_Active_failure" 1 "Not_Active_blocked" 0 "Active" ;
VAL_ 2654814208 FD14_RSL_Blockage 3 "SNA" 2 "Not_Active_failure" 1 "Not_Active_blocked" 0 "Active" ;
VAL_ 2654814208 FD14_ROL_Blockage 3 "SNA" 2 "Not_Active_failure" 1 "Not_Active_blocked" 0 "Active" ;
VAL_ 2654814208 FD14_RIL_Blockage 3 "SNA" 2 "Not_Active_failure" 1 "Not_Active_blocked" 0 "Active" ;
VAL_ 2654814208 FD14_RIR_Blockage 3 "SNA" 2 "Not_Active_failure" 1 "Not_Active_blocked" 0 "Active" ;
VAL_ 2654814208 FD14_ROR_Blockage 3 "SNA" 2 "Not_Active_failure" 1 "Not_Active_blocked" 0 "Active" ;
VAL_ 2654814208 FD14_RSR_Blockage 3 "SNA" 2 "Not_Active_failure" 1 "Not_Active_blocked" 0 "Active" ;
VAL_ 2654814208 FD14_FSL_Blockage 3 "SNA" 2 "Not_Active_failure" 1 "Not_Active_blocked" 0 "Active" ;
VAL_ 2654814208 FD14_FOL_Blockage 3 "SNA" 2 "Not_Active_failure" 1 "Not_Active_blocked" 0 "Active" ;
VAL_ 2654814208 FD14_FIL_Blockage 3 "SNA" 2 "Not_Active_failure" 1 "Not_Active_blocked" 0 "Active" ;
VAL_ 2654814208 FD14_FIR_Blockage 3 "SNA" 2 "Not_Active_failure" 1 "Not_Active_blocked" 0 "Active" ;
VAL_ 2654814208 FD14_FOR_Blockage 3 "SNA" 2 "Not_Active_failure" 1 "Not_Active_blocked" 0 "Active" ;
VAL_ 2654814208 FD14_FSR_Blockage 3 "SNA" 2 "Not_Active_failure" 1 "Not_Active_blocked" 0 "Active" ;
VAL_ 2654552169 FD14_IeAutoPark_e_AlgoState 4 "Handshake" 3 "Park_Out" 2 "Park_In" 1 "Scanning" 0 "Idle" ;
VAL_ 2654552169 FD14_IeAP_e_AutoParkStatus 6 "Complete" 5 "Abort" 4 "Fault" 3 "Active" 2 "Standby" 1 "Initialize" 0 "Off" ;
VAL_ 2654552169 FD14_MeAP_e_ParkAssistStatus 4 "Sensor_Fault" 3 "Active" 2 "Standby" 1 "Initialize" 0 "Off" ;
VAL_ 2654552217 FD14_CalibStatus_STM_Current_Rig 4 "ME_Hydra3defs_E_CalibAbortFailed" 3 "ME_Hydra3defs_E_CalibCompSuccess" 2 "ME_Hydra3defs_E_CalibRunning" 1 "ME_Hydra3defs_E_CalibPending" 0 "ME_Hydra3defs_E_CalibNotStarted" -1 "ME_Hydra3defs_E_CalStatSzeEnforc" ;
VAL_ 2654552217 FD14_CalibStatus_STM_Current_Rea 4 "ME_Hydra3defs_E_CalibAbortFailed" 3 "ME_Hydra3defs_E_CalibCompSuccess" 2 "ME_Hydra3defs_E_CalibRunning" 1 "ME_Hydra3defs_E_CalibPending" 0 "ME_Hydra3defs_E_CalibNotStarted" -1 "ME_Hydra3defs_E_CalStatSzeEnforc" ;
VAL_ 2654552217 FD14_CalibStatus_STM_Current_Lef 4 "ME_Hydra3defs_E_CalibAbortFailed" 3 "ME_Hydra3defs_E_CalibCompSuccess" 2 "ME_Hydra3defs_E_CalibRunning" 1 "ME_Hydra3defs_E_CalibPending" 0 "ME_Hydra3defs_E_CalibNotStarted" -1 "ME_Hydra3defs_E_CalStatSzeEnforc" ;
VAL_ 2654552217 FD14_CalibStatus_STM_Current_Fro 4 "ME_Hydra3defs_E_CalibAbortFailed" 3 "ME_Hydra3defs_E_CalibCompSuccess" 2 "ME_Hydra3defs_E_CalibRunning" 1 "ME_Hydra3defs_E_CalibPending" 0 "ME_Hydra3defs_E_CalibNotStarted" -1 "ME_Hydra3defs_E_CalStatSzeEnforc" ;
VAL_ 2654552217 FD14_CalibStatus_STM_OC_Right 4 "ME_Hydra3defs_E_CalibAbortFailed" 3 "ME_Hydra3defs_E_CalibCompSuccess" 2 "ME_Hydra3defs_E_CalibRunning" 1 "ME_Hydra3defs_E_CalibPending" 0 "ME_Hydra3defs_E_CalibNotStarted" -1 "ME_Hydra3defs_E_CalStatSzeEnforc" ;
VAL_ 2654552217 FD14_CalibStatus_STM_OC_Rear 4 "ME_Hydra3defs_E_CalibAbortFailed" 3 "ME_Hydra3defs_E_CalibCompSuccess" 2 "ME_Hydra3defs_E_CalibRunning" 1 "ME_Hydra3defs_E_CalibPending" 0 "ME_Hydra3defs_E_CalibNotStarted" -1 "ME_Hydra3defs_E_CalStatSzeEnforc" ;
VAL_ 2654552217 FD14_CalibStatus_STM_OC_Left 4 "ME_Hydra3defs_E_CalibAbortFailed" 3 "ME_Hydra3defs_E_CalibCompSuccess" 2 "ME_Hydra3defs_E_CalibRunning" 1 "ME_Hydra3defs_E_CalibPending" 0 "ME_Hydra3defs_E_CalibNotStarted" -1 "ME_Hydra3defs_E_CalStatSzeEnforc" ;
VAL_ 2654552217 FD14_CalibStatus_STM_OC_Front 4 "ME_Hydra3defs_E_CalibAbortFailed" 3 "ME_Hydra3defs_E_CalibCompSuccess" 2 "ME_Hydra3defs_E_CalibRunning" 1 "ME_Hydra3defs_E_CalibPending" 0 "ME_Hydra3defs_E_CalibNotStarted" -1 "ME_Hydra3defs_E_CalStatSzeEnforc" ;
VAL_ 2654552217 FD14_CalibStatus_STM_SC_Right 4 "ME_Hydra3defs_E_CalibAbortFailed" 3 "ME_Hydra3defs_E_CalibCompSuccess" 2 "ME_Hydra3defs_E_CalibRunning" 1 "ME_Hydra3defs_E_CalibPending" 0 "ME_Hydra3defs_E_CalibNotStarted" -1 "ME_Hydra3defs_E_CalStatSzeEnforc" ;
VAL_ 2654552217 FD14_CalibStatus_STM_SC_Rear 4 "ME_Hydra3defs_E_CalibAbortFailed" 3 "ME_Hydra3defs_E_CalibCompSuccess" 2 "ME_Hydra3defs_E_CalibRunning" 1 "ME_Hydra3defs_E_CalibPending" 0 "ME_Hydra3defs_E_CalibNotStarted" -1 "ME_Hydra3defs_E_CalStatSzeEnforc" ;
VAL_ 2654552217 FD14_CalibStatus_STM_SC_Left 4 "ME_Hydra3defs_E_CalibAbortFailed" 3 "ME_Hydra3defs_E_CalibCompSuccess" 2 "ME_Hydra3defs_E_CalibRunning" 1 "ME_Hydra3defs_E_CalibPending" 0 "ME_Hydra3defs_E_CalibNotStarted" -1 "ME_Hydra3defs_E_CalStatSzeEnforc" ;
VAL_ 2654552217 FD14_CalibStatus_STM_SC_Front 4 "ME_Hydra3defs_E_CalibAbortFailed" 3 "ME_Hydra3defs_E_CalibCompSuccess" 2 "ME_Hydra3defs_E_CalibRunning" 1 "ME_Hydra3defs_E_CalibPending" 0 "ME_Hydra3defs_E_CalibNotStarted" -1 "ME_Hydra3defs_E_CalStatSzeEnforc" ;
VAL_ 2654552217 FD14_CalibStatus_STM_EOL_Right 4 "ME_Hydra3defs_E_CalibAbortFailed" 3 "ME_Hydra3defs_E_CalibCompSuccess" 2 "ME_Hydra3defs_E_CalibRunning" 1 "ME_Hydra3defs_E_CalibPending" 0 "ME_Hydra3defs_E_CalibNotStarted" -1 "ME_Hydra3defs_E_CalStatSzeEnforc" ;
VAL_ 2654552217 FD14_CalibStatus_STM_EOL_Rear 4 "ME_Hydra3defs_E_CalibAbortFailed" 3 "ME_Hydra3defs_E_CalibCompSuccess" 2 "ME_Hydra3defs_E_CalibRunning" 1 "ME_Hydra3defs_E_CalibPending" 0 "ME_Hydra3defs_E_CalibNotStarted" -1 "ME_Hydra3defs_E_CalStatSzeEnforc" ;
VAL_ 2654552217 FD14_CalibStatus_STM_EOL_Left 4 "ME_Hydra3defs_E_CalibAbortFailed" 3 "ME_Hydra3defs_E_CalibCompSuccess" 2 "ME_Hydra3defs_E_CalibRunning" 1 "ME_Hydra3defs_E_CalibPending" 0 "ME_Hydra3defs_E_CalibNotStarted" -1 "ME_Hydra3defs_E_CalStatSzeEnforc" ;
VAL_ 2654552217 FD14_CalibStatus_STM_EOL_Front 4 "ME_Hydra3defs_E_CalibAbortFailed" 3 "ME_Hydra3defs_E_CalibCompSuccess" 2 "ME_Hydra3defs_E_CalibRunning" 1 "ME_Hydra3defs_E_CalibPending" 0 "ME_Hydra3defs_E_CalibNotStarted" -1 "ME_Hydra3defs_E_CalStatSzeEnforc" ;
VAL_ 2654552216 FD14_Err_Code_OC_Right 8 "e_OC_Num" 7 "e_OC_UnexpectedRequest" 6 "e_OC_InvalidSavedData" 5 "e_OC_InvalidConfiguration" 4 "e_OC_CalibrationError" 3 "e_OC_FeatureCollectionError" 2 "e_OC_StartFail" 1 "e_OC_InitFail" 0 "  e_OC_NoError " -1 "e_OCErrorCode_Size_Enforcer " ;
VAL_ 2654552216 FD14_Err_Code_OC_Rear 8 "e_OC_Num" 7 "e_OC_UnexpectedRequest" 6 "e_OC_InvalidSavedData" 5 "e_OC_InvalidConfiguration" 4 "e_OC_CalibrationError" 3 "e_OC_FeatureCollectionError" 2 "e_OC_StartFail" 1 "e_OC_InitFail" 0 "  e_OC_NoError " -1 "e_OCErrorCode_Size_Enforcer " ;
VAL_ 2654552216 FD14_Err_Code_OC_Left 8 "e_OC_Num" 7 "e_OC_UnexpectedRequest" 6 "e_OC_InvalidSavedData" 5 "e_OC_InvalidConfiguration" 4 "e_OC_CalibrationError" 3 "e_OC_FeatureCollectionError" 2 "e_OC_StartFail" 1 "e_OC_InitFail" 0 "  e_OC_NoError " -1 "e_OCErrorCode_Size_Enforcer " ;
VAL_ 2654552216 FD14_Err_Code_OC_Front 8 "e_OC_Num" 7 "e_OC_UnexpectedRequest" 6 "e_OC_InvalidSavedData" 5 "e_OC_InvalidConfiguration" 4 "e_OC_CalibrationError" 3 "e_OC_FeatureCollectionError" 2 "e_OC_StartFail" 1 "e_OC_InitFail" 0 "  e_OC_NoError " -1 "e_OCErrorCode_Size_Enforcer " ;
VAL_ 2654552216 FD14_Err_Code_SC_Right 8 "e_OC_Num" 7 "e_OC_UnexpectedRequest" 6 "e_OC_InvalidSavedData" 5 "e_OC_InvalidConfiguration" 4 "e_OC_CalibrationError" 3 "e_OC_FeatureCollectionError" 2 "e_OC_StartFail" 1 "e_OC_InitFail" 0 "  e_OC_NoError " -1 "e_OCErrorCode_Size_Enforcer " ;
VAL_ 2654552216 FD14_Err_Code_SC_Rear 8 "e_OC_Num" 7 "e_OC_UnexpectedRequest" 6 "e_OC_InvalidSavedData" 5 "e_OC_InvalidConfiguration" 4 "e_OC_CalibrationError" 3 "e_OC_FeatureCollectionError" 2 "e_OC_StartFail" 1 "e_OC_InitFail" 0 "  e_OC_NoError " -1 "e_OCErrorCode_Size_Enforcer " ;
VAL_ 2654552216 FD14_Err_Code_SC_Left 8 "e_OC_Num" 7 "e_OC_UnexpectedRequest" 6 "e_OC_InvalidSavedData" 5 "e_OC_InvalidConfiguration" 4 "e_OC_CalibrationError" 3 "e_OC_FeatureCollectionError" 2 "e_OC_StartFail" 1 "e_OC_InitFail" 0 "  e_OC_NoError " -1 "e_OCErrorCode_Size_Enforcer " ;
VAL_ 2654552216 FD14_Err_Code_SC_Front 8 "e_OC_Num" 7 "e_OC_UnexpectedRequest" 6 "e_OC_InvalidSavedData" 5 "e_OC_InvalidConfiguration" 4 "e_OC_CalibrationError" 3 "e_OC_FeatureCollectionError" 2 "e_OC_StartFail" 1 "e_OC_InitFail" 0 "  e_OC_NoError " -1 "e_OCErrorCode_Size_Enforcer " ;
VAL_ 2654552216 FD14_Err_Code_EOL_Rear_Copy_1 25 "e_EOL_PRECONDITION_NOT_CORRECT" 24 " e_EOL_WRONG_CAMERA_SOFTWARE" 23 "e_EOL_PRECOND_NOT_CORRECT_DOORS" 22 "e_EOL_PRECOND_NOT_CORRECT_VELOC" 21 "e_EOL_HMOGRAPHY_ESTIMATION_ERROR" 20 "e_EOL_ABORTED" 19 "e_EOL_NOT_CALIBRATED" 18 "e_EOL_RESULT_EXCEED_QUAL_LIM" 17 "e_EOL_TARGET_IDENTIF_ERROR_RIGHT" 16 "e_EOL_TARGET_IDENTIF_ERROR_LEFT" 9 "e_EOL_TARGET_NOT_FOUND_RIGHT" 8 "e_EOL_TARGET_NOT_FOUND_LEFT" 7 "e_EOL_TARGET_NOT_FOUND_INIT" 6 "e_EOL_VARIANT_CODING_ISSUE" 5 "e_EOL_MISSING_INTERNAL_LINK" 4 "e_EOL_PRECON_NOT_CORRECT_NUMCAMS" 3 "e_EOL_PRECOND_NOT_CORRECT_VRANGE" 2 "e_EOL_MISSING_SOFTWARE" 1 "e_EOL_CALIBRATION_SUCCESS" 0 "e_EOL_CALIBRATION_IN_PROCESS " -1 "e_EOLErrorCode_Size_Enforcer " ;
VAL_ 2654552216 FD14_Err_Code_EOL_Rear 25 "e_EOL_PRECONDITION_NOT_CORRECT" 24 " e_EOL_WRONG_CAMERA_SOFTWARE" 23 "e_EOL_PRECOND_NOT_CORRECT_DOORS" 22 "e_EOL_PRECOND_NOT_CORRECT_VELOC" 21 "e_EOL_HMOGRAPHY_ESTIMATION_ERROR" 20 "e_EOL_ABORTED" 19 "e_EOL_NOT_CALIBRATED" 18 "e_EOL_RESULT_EXCEED_QUAL_LIM" 17 "e_EOL_TARGET_IDENTIF_ERROR_RIGHT" 16 "e_EOL_TARGET_IDENTIF_ERROR_LEFT" 9 "e_EOL_TARGET_NOT_FOUND_RIGHT" 8 "e_EOL_TARGET_NOT_FOUND_LEFT" 7 "e_EOL_TARGET_NOT_FOUND_INIT" 6 "e_EOL_VARIANT_CODING_ISSUE" 5 "e_EOL_MISSING_INTERNAL_LINK" 4 "e_EOL_PRECON_NOT_CORRECT_NUMCAMS" 3 "e_EOL_PRECOND_NOT_CORRECT_VRANGE" 2 "e_EOL_MISSING_SOFTWARE" 1 "e_EOL_CALIBRATION_SUCCESS" 0 "e_EOL_CALIBRATION_IN_PROCESS " -1 "e_EOLErrorCode_Size_Enforcer " ;
VAL_ 2654552216 FD14_Err_Code_EOL_Left 25 "e_EOL_PRECONDITION_NOT_CORRECT" 24 " e_EOL_WRONG_CAMERA_SOFTWARE" 23 "e_EOL_PRECOND_NOT_CORRECT_DOORS" 22 "e_EOL_PRECOND_NOT_CORRECT_VELOC" 21 "e_EOL_HMOGRAPHY_ESTIMATION_ERROR" 20 "e_EOL_ABORTED" 19 "e_EOL_NOT_CALIBRATED" 18 "e_EOL_RESULT_EXCEED_QUAL_LIM" 17 "e_EOL_TARGET_IDENTIF_ERROR_RIGHT" 16 "e_EOL_TARGET_IDENTIF_ERROR_LEFT" 9 "e_EOL_TARGET_NOT_FOUND_RIGHT" 8 "e_EOL_TARGET_NOT_FOUND_LEFT" 7 "e_EOL_TARGET_NOT_FOUND_INIT" 6 "e_EOL_VARIANT_CODING_ISSUE" 5 "e_EOL_MISSING_INTERNAL_LINK" 4 "e_EOL_PRECON_NOT_CORRECT_NUMCAMS" 3 "e_EOL_PRECOND_NOT_CORRECT_VRANGE" 2 "e_EOL_MISSING_SOFTWARE" 1 "e_EOL_CALIBRATION_SUCCESS" 0 "e_EOL_CALIBRATION_IN_PROCESS " -1 "e_EOLErrorCode_Size_Enforcer " ;
VAL_ 2654552216 FD14_Err_Code_EOL_Front 25 "e_EOL_PRECONDITION_NOT_CORRECT" 24 " e_EOL_WRONG_CAMERA_SOFTWARE" 23 "e_EOL_PRECOND_NOT_CORRECT_DOORS" 22 "e_EOL_PRECOND_NOT_CORRECT_VELOC" 21 "e_EOL_HMOGRAPHY_ESTIMATION_ERROR" 20 "e_EOL_ABORTED" 19 "e_EOL_NOT_CALIBRATED" 18 "e_EOL_RESULT_EXCEED_QUAL_LIM" 17 "e_EOL_TARGET_IDENTIF_ERROR_RIGHT" 16 "e_EOL_TARGET_IDENTIF_ERROR_LEFT" 9 "e_EOL_TARGET_NOT_FOUND_RIGHT" 8 "e_EOL_TARGET_NOT_FOUND_LEFT" 7 "e_EOL_TARGET_NOT_FOUND_INIT" 6 "e_EOL_VARIANT_CODING_ISSUE" 5 "e_EOL_MISSING_INTERNAL_LINK" 4 "e_EOL_PRECON_NOT_CORRECT_NUMCAMS" 3 "e_EOL_PRECOND_NOT_CORRECT_VRANGE" 2 "e_EOL_MISSING_SOFTWARE" 1 "e_EOL_CALIBRATION_SUCCESS" 0 "e_EOL_CALIBRATION_IN_PROCESS " -1 "e_EOLErrorCode_Size_Enforcer " ;
VAL_ 2654552178 FD14_perpParkDirectionSel 2 "Front_In" 1 "Rear_In" 0 "None" ;
VAL_ 2654552178 FD14_parkExtSideSel 2 "Right" 1 "Left" 0 "None" ;
VAL_ 2654552178 FD14_slotSide 2 "SLOT_RIGHT" 1 "SLOT_LEFT" 0 "SLOT_NULL" ;
VAL_ 2654552178 FD14_parkingDirection 2 "REAR_IN_OUT" 1 "FRONT_IN_OUT" 0 "CAR_NULL" ;
VAL_ 2654552178 FD14_parkingSlotType 7 "PW_DIAGONAL_LINE" 6 "PW_PARALLEL_LINE" 5 "PW_PERPENDICULAR_LINE" 4 "PW_FISHBONE" 3 "PW_DIAGONAL" 2 "PW_PARALLEL" 1 "PW_PERPENDICULAR" 0 "PW_NODIR" ;
VAL_ 2654552149 FD14_tchScrnStatus_e 7 "CM_TCH_STAT_SNA" 6 "TCH_CFG_MAX    " 5 "TCH_CFG_OFFSET " 4 "TCH_CFG_RES    " 2 "TCH_PS_CAN     " 1 "TCH_PSD     " 0 "TCH_NOT_PSD    " ;
VAL_ 2654552149 FD14_View_Error_e 1 "View_NoError" 0 "View_ForceDEFAULT" ;
VAL_ 2654552149 FD14_DynOvl_Error_e 1 "DynOvl_NoError" 0 "DynOvl_ForceOFF" ;
VAL_ 2654552149 FD14_SoftBtn_Error_e 1 "SoftBtns_Functional" 0 "SoftBtns_NotFunctional" ;
VAL_ 2654552149 FD14_ImageDefeat_Error_e 2 "ImageDefeat_NoError " 1 "ImageDefeat_ForceON " 0 "ImageDefeat_ForceOFF" ;
VAL_ 2654552149 FD14_tgwDispStatus_e 21 "TGW_DISP_STAT_SNA    " 7 "DISP_SVS_MORECAMS_POPUP" 6 "DISP_WIRLESS_CAMERA  " 5 "TGW_DISP_STAT_SNA    " 4 "DISP_REAR_CAMERA     " 0 "DISP_OFF     " ;
VAL_ 2654552149 FD14_CameraDisplaySts2_e 14 "CameraDisplaySts2_View14" 13 "CameraDisplaySts2_View13" 12 "CameraDisplaySts2_View12" 11 "CameraDisplaySts2_View11" 10 "CameraDisplaySts2_View10" 9 "CameraDisplaySts2_View9" 8 "CameraDisplaySts2_View8" 7 "CameraDisplaySts2_View7" 6 "CameraDisplaySts2_View6" 5 "CameraDisplaySts2_View5" 4 "CameraDisplaySts2_View4" 3 "CameraDisplaySts2_View3" 2 "CameraDisplaySts2_View2   " 1 "CameraDisplaySts2_View1   " 0 "CameraDisplaySts2_OFF     " -1 "CameraDisplaySts2_Enforcer" ;
VAL_ 2654552149 FD14_prndStatus_e 21 "PRND_STAT_SNA  " 16 "PRND_STAT_UNDEF" 5 "PRND_STAT_NOT_R" 4 "PRND_STAT_D    " 3 "PRND_STAT_N    " 2 "PRND_STAT_R    " 1 "PRND_STAT_P    " 0 "PRND_STAT_NA   " ;
VAL_ 2654552149 FD14_transEquipped_e 2 "TRANS_SNA      " 1 "TRANS_MANUAL   " 0 "TRANS_AUTOMATIC" ;
VAL_ 2654552149 FD14_ignitionStatus_e 7 "IGN_SNA    " 5 "IGN_START  " 4 "IGN_RUN    " 3 "IGN_OFF_ACC" 2 "IGN_ACC    " 1 "IGN_OFF    " 0 "IGN_LK     " ;
VAL_ 2654552149 FD14_trscStat_e 597 "TRSC_INVALID    " 7 "TRSC_SNA        " 4 "TRSC_ACTIVE     " 3 "TRSC_PRE_ACTIVE " 2 "TRSC_CALIBRATING" 1 "TRSC_STANDBY    " 0 "TRSC_OFF        " ;
VAL_ 2654552149 FD14_NetCfg_TRSCM_e 2 "TRSCM_Prsnt_SNA  " 1 "TRSCM_Prsnt_TRUE " 0 "TRSCM_Prsnt_FALSE" ;
VAL_ 2654552149 FD14_revGear_e 2 "REV_GEAR_SNA" 1 "REV_GEAR_ENGAGED" 0 "REV_GEAR_NOT_ENGAGED" ;
VAL_ 2654552149 FD14_lrwsST_e 4 "LRWS_ST_SNA    " 3 "LRWS_ST_ERR_INI" 2 "LRWS_ST_ERR    " 1 "LRWS_ST_INI    " 0 "LRWS_ST_OK     " ;
VAL_ 2654552150 FD14_LastViewBeforeTestPattern_e 37 "ViewCount          " 36 "BlindRight" 35 "BlindLeft" 34 "THAZoomRearView2   " 33 "THAZoomRearView1   " 32 "THANormalRearView  " 31 "TRGRightCurbView   " 30 "TRGLeftCurbView   " 29 "FrontWithTiretracks" 28 "TRGRightZoomView   " 27 "TRGRightView  " 26 "TRGLeftZoomView " 25 "TRGLeftView        " 24 "TRG34L14RZoomView  " 23 "TRG34L14RView      " 22 "TRG14L34RZoomView  " 21 "TRG14L34RView      " 20 "TRG5050ZoomView   " 19 "TRG5050View        " 18 "CHMSL_ZoomView     " 17 "CHMSL_NormalView " 16 "BUZRV      " 15 "BUNRV       " 14 "RVCOnlyZoomView    " 13 "RVCOnlyNormalView  " 12 "NonViewRequested   " 11 "QuadView   " 10 "RAW_ECU   " 9 "RAW_5th       " 8 "RAW_Right       " 7 "RAW_Rear           " 6 "RAW_Left   " 5 "RAW_Front  " 4 "RearCrossView      " 3 "FrontCrossView     " 2 "RearTopView        " 1 "FrontTopView       " 0 "NoView             " ;
VAL_ 2654552150 FD14_Prev_DisplayedViewByAcore_e 37 "ViewCount          " 36 "BlindRight" 35 "BlindLeft" 34 "THAZoomRearView2   " 33 "THAZoomRearView1   " 32 "THANormalRearView  " 31 "TRGRightCurbView   " 30 "TRGLeftCurbView   " 29 "FrontWithTiretracks" 28 "TRGRightZoomView   " 27 "TRGRightView  " 26 "TRGLeftZoomView " 25 "TRGLeftView        " 24 "TRG34L14RZoomView  " 23 "TRG34L14RView      " 22 "TRG14L34RZoomView  " 21 "TRG14L34RView      " 20 "TRG5050ZoomView   " 19 "TRG5050View        " 18 "CHMSL_ZoomView     " 17 "CHMSL_NormalView " 16 "BUZRV      " 15 "BUNRV       " 14 "RVCOnlyZoomView    " 13 "RVCOnlyNormalView  " 12 "NonViewRequested   " 11 "QuadView   " 10 "RAW_ECU   " 9 "RAW_5th       " 8 "RAW_Right       " 7 "RAW_Rear           " 6 "RAW_Left   " 5 "RAW_Front  " 4 "RearCrossView      " 3 "FrontCrossView     " 2 "RearTopView        " 1 "FrontTopView       " 0 "NoView             " ;
VAL_ 2654552150 FD14_Curr_DisplayedViewByAcore_e 37 "ViewCount          " 36 "BlindRight" 35 "BlindLeft" 34 "THAZoomRearView2   " 33 "THAZoomRearView1   " 32 "THANormalRearView  " 31 "TRGRightCurbView   " 30 "TRGLeftCurbView   " 29 "FrontWithTiretracks" 28 "TRGRightZoomView   " 27 "TRGRightView  " 26 "TRGLeftZoomView " 25 "TRGLeftView        " 24 "TRG34L14RZoomView  " 23 "TRG34L14RView      " 22 "TRG14L34RZoomView  " 21 "TRG14L34RView      " 20 "TRG5050ZoomView   " 19 "TRG5050View        " 18 "CHMSL_ZoomView     " 17 "CHMSL_NormalView " 16 "BUZRV      " 15 "BUNRV       " 14 "RVCOnlyZoomView    " 13 "RVCOnlyNormalView  " 12 "NonViewRequested   " 11 "QuadView   " 10 "RAW_ECU   " 9 "RAW_5th       " 8 "RAW_Right       " 7 "RAW_Rear           " 6 "RAW_Left   " 5 "RAW_Front  " 4 "RearCrossView      " 3 "FrontCrossView     " 2 "RearTopView        " 1 "FrontTopView       " 0 "NoView             " ;
VAL_ 2654552150 FD14_Prev_RequestedViewByHmiM_e 37 "ViewCount          " 36 "BlindRight" 35 "BlindLeft" 34 "THAZoomRearView2   " 33 "THAZoomRearView1   " 32 "THANormalRearView  " 31 "TRGRightCurbView   " 30 "TRGLeftCurbView   " 29 "FrontWithTiretracks" 28 "TRGRightZoomView   " 27 "TRGRightView  " 26 "TRGLeftZoomView " 25 "TRGLeftView        " 24 "TRG34L14RZoomView  " 23 "TRG34L14RView      " 22 "TRG14L34RZoomView  " 21 "TRG14L34RView      " 20 "TRG5050ZoomView   " 19 "TRG5050View        " 18 "CHMSL_ZoomView     " 17 "CHMSL_NormalView " 16 "BUZRV      " 15 "BUNRV       " 14 "RVCOnlyZoomView    " 13 "RVCOnlyNormalView  " 12 "NonViewRequested   " 11 "QuadView   " 10 "RAW_ECU   " 9 "RAW_5th       " 8 "RAW_Right       " 7 "RAW_Rear           " 6 "RAW_Left   " 5 "RAW_Front  " 4 "RearCrossView      " 3 "FrontCrossView     " 2 "RearTopView        " 1 "FrontTopView       " 0 "NoView             " ;
VAL_ 2654552150 FD14_Curr_RequestedViewByHmiM_e 37 "ViewCount          " 36 "BlindRight" 35 "BlindLeft" 34 "THAZoomRearView2   " 33 "THAZoomRearView1   " 32 "THANormalRearView  " 31 "TRGRightCurbView   " 30 "TRGLeftCurbView   " 29 "FrontWithTiretracks" 28 "TRGRightZoomView   " 27 "TRGRightView  " 26 "TRGLeftZoomView " 25 "TRGLeftView        " 24 "TRG34L14RZoomView  " 23 "TRG34L14RView      " 22 "TRG14L34RZoomView  " 21 "TRG14L34RView      " 20 "TRG5050ZoomView   " 19 "TRG5050View        " 18 "CHMSL_ZoomView     " 17 "CHMSL_NormalView " 16 "BUZRV      " 15 "BUNRV       " 14 "RVCOnlyZoomView    " 13 "RVCOnlyNormalView  " 12 "NonViewRequested   " 11 "QuadView   " 10 "RAW_ECU   " 9 "RAW_5th       " 8 "RAW_Right       " 7 "RAW_Rear           " 6 "RAW_Left   " 5 "RAW_Front  " 4 "RearCrossView      " 3 "FrontCrossView     " 2 "RearTopView        " 1 "FrontTopView       " 0 "NoView             " ;
VAL_ 2654552150 FD14_Prev_SystemState_e 2 "RVC_Only" 1 "SystemONVideoON" 0 "SystemONVideoOFF" ;
VAL_ 2654552150 FD14_Curr_SystemState_e 2 "RVC_Only" 1 "SystemONVideoON" 0 "SystemONVideoOFF" ;
VAL_ 2654552150 FD14_M_FFClatch_e 1 "M_FFClatch_Set" 0 "M_FFClatch_NotSet" ;
VAL_ 2654552150 FD14_M_BURV_Memory_e 1 "M_ZoomLevel_Zoom" 0 "M_ZoomLevel_Normal" ;
VAL_ 2654552148 FD14_TrailerCalibrationStatus 2 "TeTRSC_e_TrlrCalInfo_Undefined" 1 "TeTRSC_e_TrlrCalInfo_Calibrated" 0 "TrlrCalInfo_NotCalibrated" -1 "TeTRSC_e_TrlrCalInfo_MAX" ;
VAL_ 2654552148 FD14_TrscStatus 7 "TeTRSC_e_TRSCStat_SNA" 6 "TeTRSC_e_TRSCStat_Fault" 5 "TeTRSC_e_TRSCStat_ActiveHoldOvr" 4 "TeTRSC_e_TRSCStat_Active" 3 "TeTRSC_e_TRSCStat_PreActive" 2 "TeTRSC_e_TRSCStat_Calibrating" 1 "TeTRSC_e_TRSCStat_Standby" 0 "TeTRSC_e_TRSCStat_Off      " -1 "TeTRSC_e_TRSCStat_MAX" ;
VAL_ 2654552148 FD14_TrailerAngleSign 1 "Anticlockwise" 0 "Clockwise" ;
VAL_ 2654552148 FD14_Prev_TRG_Stat 3 "TRG_STAT_SNA" 2 "TRG_MANU_PAN" 1 "TRG_AUTO_PAN" 0 "TRG_INACTIVE" ;
VAL_ 2654552148 FD14_Curr_TRG_Stat 3 "TRG_STAT_SNA" 2 "TRG_MANU_PAN" 1 "TRG_AUTO_PAN" 0 "TRG_INACTIVE" ;
VAL_ 2654552320 FD14_OC_ModuleState_STM_Right -1 "aZynqM_E_OC_STM_Size_Enforcer0xF" 18 "aZynqM_E_OC_STM_NumStates" 17 "aZynqM_E_OC_STM_End" 16 "aZynqM_E_OC_STM_Error" 9 "aZynqM_E_OC_STM_Stop" 8 "aZynqM_E_OC_STM_Resume" 7 "aZynqM_E_OC_STM_Paused" 6 "aZynqM_E_OC_STM_Pause" 5 " aZynqM_E_OC_STM_CheckStatus" 4 "aZynqM_E_OC_STM_StartCamCalib" 3 "aZynqM_E_OC_STM_SelectCurrCam" 2 "aZynqM_E_OC_STM_Idle" 1 "aZynqM_E_OC_STM_Init" 0 "aZynqM_E_OC_STM_NotInit " ;
VAL_ 2654552320 FD14_OC_ModuleState_STM_Rear -1 "aZynqM_E_OC_STM_Size_Enforcer0xF" 18 "aZynqM_E_OC_STM_NumStates" 17 "aZynqM_E_OC_STM_End" 16 "aZynqM_E_OC_STM_Error" 9 "aZynqM_E_OC_STM_Stop" 8 "aZynqM_E_OC_STM_Resume" 7 "aZynqM_E_OC_STM_Paused" 6 "aZynqM_E_OC_STM_Pause" 5 " aZynqM_E_OC_STM_CheckStatus" 4 "aZynqM_E_OC_STM_StartCamCalib" 3 "aZynqM_E_OC_STM_SelectCurrCam" 2 "aZynqM_E_OC_STM_Idle" 1 "aZynqM_E_OC_STM_Init" 0 "aZynqM_E_OC_STM_NotInit " ;
VAL_ 2654552320 FD14_OC_ModuleState_STM_Left -1 "aZynqM_E_OC_STM_Size_Enforcer0xF" 18 "aZynqM_E_OC_STM_NumStates" 17 "aZynqM_E_OC_STM_End" 16 "aZynqM_E_OC_STM_Error" 9 "aZynqM_E_OC_STM_Stop" 8 "aZynqM_E_OC_STM_Resume" 7 "aZynqM_E_OC_STM_Paused" 6 "aZynqM_E_OC_STM_Pause" 5 " aZynqM_E_OC_STM_CheckStatus" 4 "aZynqM_E_OC_STM_StartCamCalib" 3 "aZynqM_E_OC_STM_SelectCurrCam" 2 "aZynqM_E_OC_STM_Idle" 1 "aZynqM_E_OC_STM_Init" 0 "aZynqM_E_OC_STM_NotInit " ;
VAL_ 2654552320 FD14_OC_ModuleState_STM_Front -1 "aZynqM_E_OC_STM_Size_Enforcer0xF" 18 "aZynqM_E_OC_STM_NumStates" 17 "aZynqM_E_OC_STM_End" 16 "aZynqM_E_OC_STM_Error" 9 "aZynqM_E_OC_STM_Stop" 8 "aZynqM_E_OC_STM_Resume" 7 "aZynqM_E_OC_STM_Paused" 6 "aZynqM_E_OC_STM_Pause" 5 " aZynqM_E_OC_STM_CheckStatus" 4 "aZynqM_E_OC_STM_StartCamCalib" 3 "aZynqM_E_OC_STM_SelectCurrCam" 2 "aZynqM_E_OC_STM_Idle" 1 "aZynqM_E_OC_STM_Init" 0 "aZynqM_E_OC_STM_NotInit " ;
VAL_ 2654552320 FD14_SC_ModuleState_STM_Right 19 "  aZynqM_E_SC_STM_NumStates" 18 "aZynqM_E_SC_STM_E_End" 17 "aZynqM_E_SC_STM_E_Error" 16 "aZynqM_E_SC_STM_E_Stop" 9 "aZynqM_E_SC_STM_E_Resume" 8 "aZynqM_E_SC_STM_E_Paused" 7 "aZynqM_E_SC_STM_E_Pause" 6 "aZynqM_E_SC_STM_E_CheckStatus" 5 "aZynqM_E_SC_STM_E_StartCamCalib" 4 "aZynqM_E_SC_STM_E_SelectCurrCam" 3 "aZynqM_E_SC_STM_E_WaitEEPROMRead" 2 "  aZynqM_E_SC_STM_E_Idle" 1 "aZynqM_E_SC_STM_E_Init" 0 "aZynqM_E_SC_STM_E_NotInit " -1 "  aZynqM_E_SC_STM_Size_Enforcer " ;
VAL_ 2654552320 FD14_SC_ModuleState_STM_Rear 19 "  aZynqM_E_SC_STM_NumStates" 18 "aZynqM_E_SC_STM_E_End" 17 "aZynqM_E_SC_STM_E_Error" 16 "aZynqM_E_SC_STM_E_Stop" 9 "aZynqM_E_SC_STM_E_Resume" 8 "aZynqM_E_SC_STM_E_Paused" 7 "aZynqM_E_SC_STM_E_Pause" 6 "aZynqM_E_SC_STM_E_CheckStatus" 5 "aZynqM_E_SC_STM_E_StartCamCalib" 4 "aZynqM_E_SC_STM_E_SelectCurrCam" 3 "aZynqM_E_SC_STM_E_WaitEEPROMRead" 2 "  aZynqM_E_SC_STM_E_Idle" 1 "aZynqM_E_SC_STM_E_Init" 0 "aZynqM_E_SC_STM_E_NotInit " -1 "  aZynqM_E_SC_STM_Size_Enforcer " ;
VAL_ 2654552320 FD14_SC_ModuleState_STM_Left 19 "  aZynqM_E_SC_STM_NumStates" 18 "aZynqM_E_SC_STM_E_End" 17 "aZynqM_E_SC_STM_E_Error" 16 "aZynqM_E_SC_STM_E_Stop" 9 "aZynqM_E_SC_STM_E_Resume" 8 "aZynqM_E_SC_STM_E_Paused" 7 "aZynqM_E_SC_STM_E_Pause" 6 "aZynqM_E_SC_STM_E_CheckStatus" 5 "aZynqM_E_SC_STM_E_StartCamCalib" 4 "aZynqM_E_SC_STM_E_SelectCurrCam" 3 "aZynqM_E_SC_STM_E_WaitEEPROMRead" 2 "  aZynqM_E_SC_STM_E_Idle" 1 "aZynqM_E_SC_STM_E_Init" 0 "aZynqM_E_SC_STM_E_NotInit " -1 "  aZynqM_E_SC_STM_Size_Enforcer " ;
VAL_ 2654552320 FD14_SC_ModuleState_STM_Front 19 "  aZynqM_E_SC_STM_NumStates" 18 "aZynqM_E_SC_STM_E_End" 17 "aZynqM_E_SC_STM_E_Error" 16 "aZynqM_E_SC_STM_E_Stop" 9 "aZynqM_E_SC_STM_E_Resume" 8 "aZynqM_E_SC_STM_E_Paused" 7 "aZynqM_E_SC_STM_E_Pause" 6 "aZynqM_E_SC_STM_E_CheckStatus" 5 "aZynqM_E_SC_STM_E_StartCamCalib" 4 "aZynqM_E_SC_STM_E_SelectCurrCam" 3 "aZynqM_E_SC_STM_E_WaitEEPROMRead" 2 "  aZynqM_E_SC_STM_E_Idle" 1 "aZynqM_E_SC_STM_E_Init" 0 "aZynqM_E_SC_STM_E_NotInit " -1 "  aZynqM_E_SC_STM_Size_Enforcer " ;
VAL_ 2654552320 FD14_EOL_ModuleState_STM_Right 9 "aZynqM_E_EOL_STM_NumStates" 8 "aZynqM_E_EOL_STM_E_End" 7 "aZynqM_E_EOL_STM_E_Error" 6 " aZynqM_E_EOL_STM_E_Stop" 5 "aZynqM_E_EOL_STM_E_CheckStatus" 4 "aZynqM_E_EOL_STM_E_StartCamCalib" 3 "aZynqM_E_EOL_STM_E_SelectCurrCam" 2 "aZynqM_E_EOL_STM_E_Idle" 1 "aZynqM_E_EOL_STM_E_Init" 0 "aZynqM_E_EOL_STM_E_NotInit" -1 "aZynqM_E_EOL_STM_Size_Enforcer" ;
VAL_ 2654552320 FD14_EOL_ModuleState_STM_Rear 9 "aZynqM_E_EOL_STM_NumStates" 8 "aZynqM_E_EOL_STM_E_End" 7 "aZynqM_E_EOL_STM_E_Error" 6 " aZynqM_E_EOL_STM_E_Stop" 5 "aZynqM_E_EOL_STM_E_CheckStatus" 4 "aZynqM_E_EOL_STM_E_StartCamCalib" 3 "aZynqM_E_EOL_STM_E_SelectCurrCam" 2 "aZynqM_E_EOL_STM_E_Idle" 1 "aZynqM_E_EOL_STM_E_Init" 0 "aZynqM_E_EOL_STM_E_NotInit" -1 "aZynqM_E_EOL_STM_Size_Enforcer" ;
VAL_ 2654552320 FD14_EOL_ModuleState_STM_Left 9 "aZynqM_E_EOL_STM_NumStates" 8 "aZynqM_E_EOL_STM_E_End" 7 "aZynqM_E_EOL_STM_E_Error" 6 " aZynqM_E_EOL_STM_E_Stop" 5 "aZynqM_E_EOL_STM_E_CheckStatus" 4 "aZynqM_E_EOL_STM_E_StartCamCalib" 3 "aZynqM_E_EOL_STM_E_SelectCurrCam" 2 "aZynqM_E_EOL_STM_E_Idle" 1 "aZynqM_E_EOL_STM_E_Init" 0 "aZynqM_E_EOL_STM_E_NotInit" -1 "aZynqM_E_EOL_STM_Size_Enforcer" ;
VAL_ 2654552320 FD14_EOL_ModuleState_STM_Front 9 "aZynqM_E_EOL_STM_NumStates" 8 "aZynqM_E_EOL_STM_E_End" 7 "aZynqM_E_EOL_STM_E_Error" 6 " aZynqM_E_EOL_STM_E_Stop" 5 "aZynqM_E_EOL_STM_E_CheckStatus" 4 "aZynqM_E_EOL_STM_E_StartCamCalib" 3 "aZynqM_E_EOL_STM_E_SelectCurrCam" 2 "aZynqM_E_EOL_STM_E_Idle" 1 "aZynqM_E_EOL_STM_E_Init" 0 "aZynqM_E_EOL_STM_E_NotInit" -1 "aZynqM_E_EOL_STM_Size_Enforcer" ;
SIG_VALTYPE_ 2654552169 FD14_MeAP_e_Park_state : 1;
SIG_VALTYPE_ 2654552169 FD14_MeAP_a_ThrtlCmd : 1;
SIG_VALTYPE_ 2654552169 FD14_MeAP_a_BrkCmd : 1;
SIG_VALTYPE_ 2654552169 FD14_MeAP_deg_StrCmd : 1;
SIG_VALTYPE_ 2654552163 FD14_Z_f32_Current_Right : 1;
SIG_VALTYPE_ 2654552163 FD14_Z_f32_Current_Rear : 1;
SIG_VALTYPE_ 2654552163 FD14_Pitch_f32_Current_Right : 1;
SIG_VALTYPE_ 2654552163 FD14_Pitch_f32_Current_Rear : 1;
SIG_VALTYPE_ 2654552163 FD14_Roll_f32_Current_Right : 1;
SIG_VALTYPE_ 2654552163 FD14_Roll_f32_Current_Rear : 1;
SIG_VALTYPE_ 2654552163 FD14_Yaw_f32_Current_Right : 1;
SIG_VALTYPE_ 2654552163 FD14_Yaw_f32_Current_Rear : 1;
SIG_VALTYPE_ 2654552163 FD14_Y_f32_Current_Right : 1;
SIG_VALTYPE_ 2654552163 FD14_Y_f32_Current_Rear : 1;
SIG_VALTYPE_ 2654552163 FD14_X_f32_Current_Right : 1;
SIG_VALTYPE_ 2654552163 FD14_X_f32_Current_Rear : 1;
SIG_VALTYPE_ 2654552152 FD14_Pitch_f32_EOL_Left : 1;
SIG_VALTYPE_ 2654552152 FD14_Roll_f32_EOL_Left : 1;
SIG_VALTYPE_ 2654552152 FD14_Yaw_f32_EOL_Left : 1;
SIG_VALTYPE_ 2654552152 FD14_Z_f32_EOL_Left : 1;
SIG_VALTYPE_ 2654552152 FD14_Y_f32_EOL_Left : 1;
SIG_VALTYPE_ 2654552152 FD14_X_f32_EOL_Left : 1;
SIG_VALTYPE_ 2654552152 FD14_Pitch_f32_EOL_Front : 1;
SIG_VALTYPE_ 2654552152 FD14_Roll_f32_EOL_Front : 1;
SIG_VALTYPE_ 2654552152 FD14_Yaw_f32_EOL_Front : 1;
SIG_VALTYPE_ 2654552152 FD14_Z_f32_EOL_Front : 1;
SIG_VALTYPE_ 2654552152 FD14_Y_f32_EOL_Front : 1;
SIG_VALTYPE_ 2654552152 FD14_X_f32_EOL_Front : 1;
SIG_VALTYPE_ 2654552164 FD14_Roll_f32_EOL_Right : 1;
SIG_VALTYPE_ 2654552164 FD14_Pitch_f32_EOL_Right : 1;
SIG_VALTYPE_ 2654552164 FD14_Yaw_f32_EOL_Right : 1;
SIG_VALTYPE_ 2654552164 FD14_Z_f32_EOL_Right : 1;
SIG_VALTYPE_ 2654552164 FD14_Y_f32_EOL_Right : 1;
SIG_VALTYPE_ 2654552164 FD14_X_f32_EOL_Right : 1;
SIG_VALTYPE_ 2654552164 FD14_Pitch_f32_EOL_Rear : 1;
SIG_VALTYPE_ 2654552164 FD14_Roll_f32_EOL_Rear : 1;
SIG_VALTYPE_ 2654552164 FD14_Yaw_f32_EOL_Rear : 1;
SIG_VALTYPE_ 2654552164 FD14_Z_f32_EOL_Rear : 1;
SIG_VALTYPE_ 2654552164 FD14_Y_f32_EOL_Rear : 1;
SIG_VALTYPE_ 2654552164 FD14_X_f32_EOL_Rear : 1;
SIG_VALTYPE_ 2654552178 FD14_MaAP_m_ParkSpot4RearStreetY : 1;
SIG_VALTYPE_ 2654552178 FD14_MaAP_m_ParkSpot4RearStreetX : 1;
SIG_VALTYPE_ 2654552178 FD14_MaAP_m_ParkSpot3RearBorderY : 1;
SIG_VALTYPE_ 2654552178 FD14_MaAP_m_ParkSpot3RearBorderX : 1;
SIG_VALTYPE_ 2654552178 FD14_MaAP_m_ParkSpot2FrntBorderY : 1;
SIG_VALTYPE_ 2654552178 FD14_MaAP_m_ParkSpot2FrntBorderX : 1;
SIG_VALTYPE_ 2654552178 FD14_MaAP_m_ParkSpot1FrntStreetY : 1;
SIG_VALTYPE_ 2654552178 FD14_MaAP_m_ParkSpot1FrntStreetX : 1;
SIG_VALTYPE_ 2654552149 FD14_vehicleSpeed_f32 : 1;
SIG_VALTYPE_ 2654552149 FD14_steeringWheelAngle_f32 : 1;
SIG_VALTYPE_ 2654552148 FD14__JackKnifeAngle : 1;
SIG_VALTYPE_ 2654552148 FD14_KnobAngle : 1;
SIG_VALTYPE_ 2654552148 FD14_MaxTadAngle : 1;
SIG_VALTYPE_ 2654552148 FD14_TadAngle : 1;
SIG_VALTYPE_ 2654552176 FD14_NFCD_DistanceToClosestPoint : 1;
SIG_VALTYPE_ 2654552176 FD14_NFCD_DistanceToClosest_0000 : 1;
SIG_VALTYPE_ 2654552176 FD14_NFCD_DistanceToClosest_0001 : 1;
SIG_VALTYPE_ 2654552176 FD14_NFCD_DistanceToClosest_0002 : 1;
SIG_VALTYPE_ 2654552176 FD14_NFCD_DistanceToClosest_0003 : 1;
SIG_VALTYPE_ 2654552176 FD14_NFCD_DistanceToClosest_0004 : 1;
SIG_VALTYPE_ 2654552176 FD14_NFCD_DistanceToClosest_0005 : 1;
SIG_VALTYPE_ 2654552176 FD14_NFCD_DistanceToClosest_0006 : 1;
SIG_VALTYPE_ 2654552176 FD14_NFCD_DistanceToClosest_0007 : 1;
SIG_VALTYPE_ 2654552176 FD14_NFCD_DistanceToClosest_0008 : 1;
SIG_VALTYPE_ 2654552177 FD14_IeVBII_nfcd_MinDisToCollisi : 1;
SIG_VALTYPE_ 2654552177 FD14_NFCD_DistanceToClosest_0009 : 1;
SIG_VALTYPE_ 2654552177 FD14_NFCD_DistanceToClosest_0010 : 1;
SIG_VALTYPE_ 2654552177 FD14_NFCD_DistanceToClosest_0011 : 1;
SIG_VALTYPE_ 2654552177 FD14_NFCD_DistanceToClosest_0012 : 1;
SIG_VALTYPE_ 2654552177 FD14_NFCD_DistanceToClosest_0013 : 1;
SIG_VALTYPE_ 2654552177 FD14_NFCD_DistanceToClosest_0014 : 1;
SIG_VALTYPE_ 2654552177 FD14_NFCD_DistanceToClosest_0015 : 1;
SIG_VALTYPE_ 2654552177 FD14_NFCD_DistanceToClosest_0016 : 1;
SIG_VALTYPE_ 2654552177 FD14_NFCD_DistanceToClosest_0017 : 1;
SIG_VALTYPE_ 2654552177 FD14_NFCD_DistanceToClosest_0018 : 1;
SIG_VALTYPE_ 2654552160 FD14_Z_f32_Current_Rear : 1;
SIG_VALTYPE_ 2654552160 FD14_Y_f32_Current_Rear : 1;
SIG_VALTYPE_ 2654552160 FD14_X_f32_Current_Rear : 1;
SIG_VALTYPE_ 2654552160 FD14_Pitch_f32_OC_Right : 1;
SIG_VALTYPE_ 2654552160 FD14_Roll_f32_OC_Right : 1;
SIG_VALTYPE_ 2654552160 FD14_Yaw_f32_OC_Right : 1;
SIG_VALTYPE_ 2654552160 FD14_Pitch_f32_OC_Rear : 1;
SIG_VALTYPE_ 2654552160 FD14_Roll_f32_OC_Rear : 1;
SIG_VALTYPE_ 2654552160 FD14_Yaw_f32_OC_Rear : 1;
SIG_VALTYPE_ 2654552160 FD14_Pitch_f32_OC_Left : 1;
SIG_VALTYPE_ 2654552160 FD14_Roll_f32_OC_Left : 1;
SIG_VALTYPE_ 2654552160 FD14_Yaw_f32_OC_Left : 1;
SIG_VALTYPE_ 2654552160 FD14_Pitch_f32_OC_Front : 1;
SIG_VALTYPE_ 2654552160 FD14_Roll_f32_OC_Front : 1;
SIG_VALTYPE_ 2654552160 FD14_Yaw_f32_OC_Front : 1;
SIG_VALTYPE_ 2654552153 FD14_Pitch_f32_SC_Right : 1;
SIG_VALTYPE_ 2654552153 FD14_Roll_f32_SC_Right : 1;
SIG_VALTYPE_ 2654552153 FD14_Yaw_f32_SC_Right : 1;
SIG_VALTYPE_ 2654552153 FD14_Pitch_f32_SC_Rear : 1;
SIG_VALTYPE_ 2654552153 FD14_Roll_f32_SC_Rear : 1;
SIG_VALTYPE_ 2654552153 FD14_Yaw_f32_SC_Rear : 1;
SIG_VALTYPE_ 2654552153 FD14_Pitch_f32_SC_Left : 1;
SIG_VALTYPE_ 2654552153 FD14_Roll_f32_SC_Left : 1;
SIG_VALTYPE_ 2654552153 FD14_Yaw_f32_SC_Left : 1;
SIG_VALTYPE_ 2654552153 FD14_Pitch_f32_SC_Front : 1;
SIG_VALTYPE_ 2654552153 FD14_Roll_f32_SC_Front : 1;
SIG_VALTYPE_ 2654552153 FD14_Yaw_f32_SC_Front : 1;
